VERSION "Version"

NS_ :

BS_:

BU_: Tester MCU BMS GCU EOP EVCC CCU CCURT1 CCURT2 CCU3 CCU4 ZCUF ZCUL ZCUR ZCUT PADS VDC GSM PCU TCU EMS DCDC IPS DCU2 OBC OPC LPC CPC DCU IPU SRS ECS EPS EPB IBCS RBM ICM IDC AMP WHUD IMR INU ADC IFC RRR RLR RADARRR RADARRL RADARFR RADARFL PAS PCS RPC RADARFRT RADARR SCMR SCMRR SCMRL MFS AVAS DLPFL FBLCM FLISD FLLCM FRLCM RLLCMA RLLCMB RRLCMA RRLCMB DLPML DLPMR PSDL PSDR HVSPRL HVSPRR UWB RFR SBM WCM ETC TBOX IDUR Rema2 Rema1 IID TMC RCICP CD SCMRM SCMT FCP RCP RLISD RRISD LBMS FR PLGM EDL

BO_ 2015 Fun_Diag_Rx: 64 Tester
 SG_ Fun_Diag_Request : 7|512@0+ (1,0) [0|0] ""  CCURT1,CCURT2,CCU3,CCU4,ZCUF,ZCUL,ZCUR,ZCUT,PADS,VDC,GSM,PCU,TCU,EMS,DCDC,IPS,MCU,DCU2,OBC,OPC,LPC,CPC,GCU,DCU,IPU,BMS,EOP,EVCC,SRS,ECS,EPS,EPB,IBCS,RBM,ICM,IDC,AMP,WHUD,IMR,INU,ADC,IFC,RRR,RLR,RADARRR,RADARRL,RADARFR,RADARFL,PAS,PCS,RPC,RADARFRT,RADARR,SCMR,SCMRR,SCMRL,MFS,AVAS,DLPFL,FBLCM,FLISD,FLLCM,FRLCM,RLLCMA,RLLCMB,RRLCMA,RRLCMB,DLPML,DLPMR,PSDL,PSDR,HVSPRL,HVSPRR,UWB,RFR,SBM,WCM,ETC,TBOX

BO_ 1179 DCU2_DiagEvent: 64 MCU
 SG_ DCU2_DTCCode15 : 487|32@0+ (1,0) [0|4294967295] ""  CCU,CCURT1
 SG_ DCU2_DTCCode14 : 455|32@0+ (1,0) [0|4294967295] ""  CCU,CCURT1
 SG_ DCU2_DTCCode13 : 423|32@0+ (1,0) [0|4294967295] ""  CCU,CCURT1
 SG_ DCU2_DTCCode12 : 391|32@0+ (1,0) [0|4294967295] ""  CCU,CCURT1
 SG_ DCU2_DTCCode11 : 359|32@0+ (1,0) [0|4294967295] ""  CCU,CCURT1
 SG_ DCU2_DTCCode10 : 327|32@0+ (1,0) [0|4294967295] ""  CCU,CCURT1
 SG_ DCU2_DTCCode9 : 295|32@0+ (1,0) [0|4294967295] ""  CCU,CCURT1
 SG_ DCU2_DTCCode8 : 263|32@0+ (1,0) [0|4294967295] ""  CCU,CCURT1
 SG_ DCU2_DTCCode7 : 231|32@0+ (1,0) [0|4294967295] ""  CCU,CCURT1
 SG_ DCU2_DTCCode6 : 199|32@0+ (1,0) [0|4294967295] ""  CCU,CCURT1
 SG_ DCU2_DTCCode5 : 167|32@0+ (1,0) [0|4294967295] ""  CCU,CCURT1
 SG_ DCU2_DTCCode4 : 135|32@0+ (1,0) [0|4294967295] ""  CCU,CCURT1
 SG_ DCU2_DTCCode3 : 103|32@0+ (1,0) [0|4294967295] ""  CCU,CCURT1
 SG_ DCU2_DTCCode2 : 71|32@0+ (1,0) [0|4294967295] ""  CCU,CCURT1
 SG_ DCU2_DTCCode1 : 39|32@0+ (1,0) [0|4294967295] ""  CCU,CCURT1
 SG_ DCU2_DTCCode0 : 7|32@0+ (1,0) [0|4294967295] ""  CCU,CCURT1

BO_ 1185 IPS_DigEvent: 64 MCU
 SG_ IPS_DigEvent : 7|512@0+ (1,0) [0|0] ""  CCU,CCURT1

BO_ 378 BMS_1: 64 BMS
 SG_ BMS_1_CRC : 7|16@0+ (1,0) [0|65535] ""  CCU,CCURT1,DCDC,IPS,MCU,DCU2,IDUR,OBC,GCU,DCU,IPU
 SG_ BMS_1_Counter : 23|8@0+ (1,0) [0|255] ""  CCU,CCURT1,DCDC,IPS,MCU,DCU2,IDUR,OBC,GCU,DCU,IPU
 SG_ BMS_BattCurr : 31|16@0+ (0.1,-1000) [-1000|5553.5] "A"  CCU,MCU,DCU2,IDUR,GCU,DCU,IPU
 SG_ BMS_BattVolt : 47|10@0+ (1,0) [0|1023] "V"  CCU,MCU,DCU2,IDUR,GCU,DCU,IPU
 SG_ BMS_BusVolt : 49|10@0+ (1,0) [0|1023] "V"  CCU,MCU,DCU2,IDUR,GCU,DCU,IPU
 SG_ BMS_PwrDwnReq : 97|2@0+ (1,0) [0|3] ""  CCU,DCDC,IPS,MCU,DCU2,IDUR,OBC,GCU,DCU,IPU
 SG_ BMS_DCUBattSt : 108|1@0+ (1,0) [0|1] ""  CCU,CCURT1,CCURT2,DCDC,IPS,MCU,DCU2,IDUR,OBC,GCU,DCU,IPU

BO_ 729 EDL_1: 24 EDL
 SG_ EDL_DiffLockModSt_R : 59|3@0+ (1,0) [0|7] ""  CCU,CCURT1,MCU,Rema1

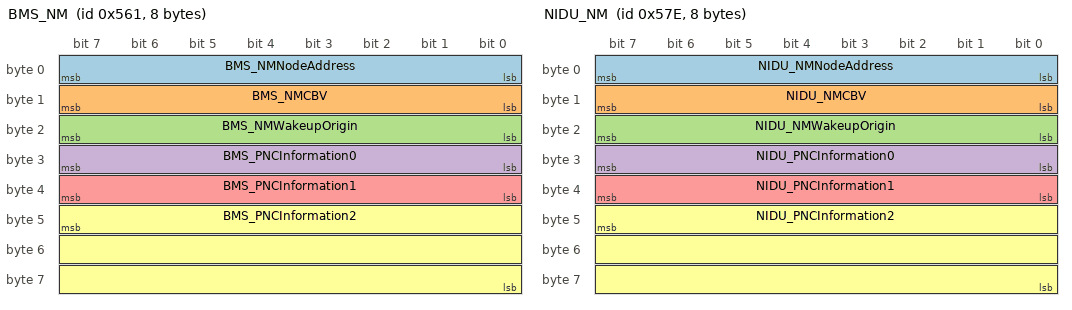
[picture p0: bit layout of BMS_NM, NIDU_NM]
BO_ 1377 BMS_NM: 8 BMS
 SG_ BMS_NMNodeAddress : 7|8@0+ (1,0) [0|255] ""  CCU,DCDC,IPS,MCU,OBC,OPC,GCU,DCU,IPU
 SG_ BMS_NMCBV : 15|8@0+ (1,0) [0|0] ""  CCU,DCDC,IPS,MCU,OBC,OPC,GCU,DCU,IPU
 SG_ BMS_NMWakeupOrigin : 23|8@0+ (1,0) [0|255] ""  CCU,DCDC,IPS,MCU,OBC,OPC,GCU,DCU,IPU
 SG_ BMS_PNCInformation0 : 31|8@0+ (1,0) [0|255] ""  CCU,DCDC,IPS,MCU,OBC,OPC,GCU,DCU,IPU
 SG_ BMS_PNCInformation1 : 39|8@0+ (1,0) [0|0] ""  CCU,DCDC,IPS,MCU,OBC,OPC,GCU,DCU,IPU
 SG_ BMS_PNCInformation2 : 47|24@0+ (1,0) [0|0] ""  CCU,DCDC,IPS,MCU,OBC,OPC,GCU,DCU,IPU

BO_ 410 GCU_1: 64 GCU
 SG_ GCU_IdcAct : 47|11@0+ (1,-1023) [-1023|1022] "A"  CCU,MCU,DCU2,IDUR,DCU,BMS

BO_ 369 DCU2_1: 64 MCU
 SG_ DCU2_1_CRC : 7|16@0+ (1,0) [0|65535] ""  CCU,CCURT1,BMS,EOP,Tester
 SG_ DCU2_1_Counter : 23|8@0+ (1,0) [0|255] ""  CCU,CCURT1,BMS,EOP,Tester
 SG_ DCU2_RotSpdAct : 31|16@0+ (1,-32767) [-32767|32766] "rpm"  CCU,CCURT1,BMS,EOP
 SG_ DCU2_IdcAct : 47|11@0+ (1,-1023) [-1023|1022] "A"  CCU,CCURT1,BMS
 SG_ DCU2_UdcAct : 52|10@0+ (1,0) [0|1021] "V"  CCU,CCURT1,BMS
 SG_ DCU2_CCUEOPPowerSup : 57|2@0+ (1,0) [0|3] ""  CCU,CCURT1,EOP
 SG_ DCU2_TorqMax : 75|10@0+ (1,0) [0|1021] "Nm"  CCU,CCURT1
 SG_ DCU2_HvilSt : 81|2@0+ (1,0) [0|3] ""  CCU,CCURT1
 SG_ DCU2_TorqMin : 95|10@0+ (1,-1023) [-1021|0] "Nm"  CCU,CCURT1
 SG_ DCU2_SelfTorqMax : 101|10@0+ (1,0) [0|1021] "Nm"  CCU,CCURT1
 SG_ DCU2_SelfTorqMin : 106|10@0+ (1,-1023) [-1021|0] "Nm"  CCU,CCURT1
 SG_ DCU2_DstActive : 112|1@0+ (1,0) [0|1] ""  CCU,CCURT1
 SG_ DCU2_GateDrvSt : 127|2@0+ (1,0) [0|3] ""  CCU,CCURT1
 SG_ DCU2_DiagErrCode : 125|6@0+ (1,0) [0|63] ""  CCU,CCURT1
 SG_ DCU2_EOP_SpdSet : 188|12@0+ (1,0) [0|4000] "rpm"  CCU,CCURT1,EOP
 SG_ DCU2_ModeSt_Hyb : 221|4@0+ (1,0) [0|15] ""  CCU,CCURT1,BMS
 SG_ DCU2_TorqAct : 169|13@0+ (0.2,-819) [-819|819] "Nm"  CCU,CCURT1,EOP
 SG_ DCU2_ADC_MCUBlkst : 268|3@0+ (1,0) [0|7] ""  CCU,CCURT1,Rema2
 SG_ DCU2_ADC_SpdSvModAvl : 256|1@0+ (1,0) [0|1] ""  CCU,CCURT1,Rema2
 SG_ DCU2_ADC_MCUStandstill : 257|1@0+ (1,0) [0|1] ""  CCU,CCURT1,Rema2
 SG_ DCU2_ADC_MCUSpdSVModFit : 271|3@0+ (1,0) [0|7] ""  CCU,CCURT1,Rema2
 SG_ DCU2_ADC_MCUVehSldSt : 258|1@0+ (1,0) [0|1] ""  CCU,CCURT1,Rema2
 SG_ DCU2_ADC_MCUReqTq : 253|11@0+ (1,-1023) [-1023|1023] "Nm"  CCU,CCURT1,Rema2
 SG_ DCU2_Iq : 338|15@0+ (0.1,-1500) [-1500|1776.7] "A"  CCU,Rema1
 SG_ DCU2_Id : 355|15@0+ (0.1,-1500) [-1500|1776.7] "A"  CCU,Rema1
 SG_ DCU2_TrqWoDstC : 406|10@0+ (1,-511) [-511|510] "Nm"  CCU,CCURT1
 SG_ DCU2_stTrqEmLim : 417|11@0+ (1,0) [0|2045] ""  CCU,CCURT1
 SG_ DCU2_KL15St : 217|1@0+ (1,0) [0|1] ""  CCU,CCURT1,Rema1

BO_ 866 DCU2_2: 64 MCU
 SG_ DCU2_2_CRC : 7|16@0+ (1,0) [0|65535] ""  CCU,CCURT1
 SG_ DCU2_2_Counter : 23|8@0+ (1,0) [0|255] ""  CCU,CCURT1
 SG_ DCU2_OffsetCalInd : 64|1@0+ (1,0) [0|1] ""  CCU,CCURT1
 SG_ DCU2_InvtTemp : 72|8@0+ (1,-40) [-40|213] "degC"  CCU,CCURT1
 SG_ DCU2_VoltageT30 : 80|6@0+ (0.5,0) [0|31.5] "V"  CCU,CCURT1
 SG_ DCU2_SysTempOvrInd : 90|1@0+ (1,0) [0|1] ""  CCU,CCURT1
 SG_ DCU2_RotTemp : 89|9@0+ (1,-40) [-40|469] "degC"  CCU,CCURT1
 SG_ DCU2_CooltReq : 96|6@0+ (0.25,0) [0|15.5] "L/min"  CCU,CCURT1
 SG_ DCU2_FaultLampInd : 106|1@0+ (1,0) [0|1] ""  CCU,CCURT1
 SG_ DCU2_StatTemp : 105|9@0+ (1,-40) [-40|469] "degC"  CCU,CCURT1
 SG_ DCU2_ErrNotice : 135|3@0+ (1,0) [0|7] ""  CCU,Rema1
 SG_ DCU2_ETCS : 182|1@0+ (1,0) [0|1] ""  CCU,CCURT1,Rema1
 SG_ DCU2_TEL_MotorNumOrder : 194|3@0+ (1,0) [0|7] ""  CCU,CCURT1
 SG_ DCU2_TEL_ECUTempOvrErr : 195|1@0+ (1,0) [0|1] ""  CCU,CCURT1
 SG_ DCU2_TEL_MotTempOvrErr : 196|1@0+ (1,0) [0|1] ""  CCU,CCURT1
 SG_ DCU2_TEL_MotorNumTotal : 199|3@0+ (1,0) [0|7] ""  CCU,CCURT1
 SG_ DCU2_TEL_InvtTemp : 207|8@0+ (1,-40) [-40|213] "deg"  CCU,CCURT1
 SG_ DCU2_TEL_RotSpdAct : 215|16@0+ (1,-20000) [-20000|45533] "rpm"  CCU,CCURT1
 SG_ DCU2_TEL_TorqAct : 231|16@0+ (0.1,-2000) [-2000|4553.3] "Nm"  CCU,CCURT1
 SG_ DCU2_TEL_StatTemp : 247|8@0+ (1,-40) [-40|213] "deg"  CCU,CCURT1
 SG_ DCU2_TEL_ModeSt : 293|3@0+ (1,0) [0|7] ""  CCU,CCURT1
 SG_ DCU2_TEL_CurrActAmend : 255|16@0+ (0.1,-1000) [-1000|1000] "A"  CCU,CCURT1
 SG_ DCU2_TEL_UdcAct : 181|14@0+ (0.1,0) [0|1000] "V"  CCU,CCURT1
 SG_ DCU2_TEL_BattCurr : 271|16@0+ (0.1,-1000) [-1000|1000] "A"  CCU,CCURT1
 SG_ DCU2_Fault1 : 138|16@0+ (1,0) [0|65535] ""  CCU,Rema1
 SG_ DCU2_Fault2 : 154|16@0+ (1,0) [0|65535] ""  CCU,Rema1
 SG_ DCU2_Fault3 : 406|16@0+ (1,0) [0|65535] ""  CCU,Rema1
 SG_ DCU2_Fault4 : 422|16@0+ (1,0) [0|65535] ""  CCU,Rema1
 SG_ DCU2_OffsetCalVal : 389|13@0+ (0.05,0) [0|409.45] "deg"  CCU,CCURT1
 SG_ DCU2_EngMilLampReq : 392|1@0+ (1,0) [0|1] ""  CCU,CCURT1
 SG_ DCU2_ZeroTorqCompensateSt : 407|1@0+ (1,0) [0|1] ""  CCU,CCURT1

BO_ 1275 DCU2_BigData: 64 MCU
 SG_ DCU2_Data1No M : 7|8@0+ (1,0) [0|205] ""  CCU,Rema1
 SG_ DCU2_Hwversion m1 : 15|16@0+ (1,0) [0|65535] ""  CCU,Rema1
 SG_ DCU2_Swversion m1 : 31|16@0+ (1,0) [0|65535] ""  CCU,Rema1
 SG_ DCU2_SwVerExt m1 : 47|32@0+ (1,0) [0|4294967295] ""  CCU,Rema1
 SG_ DCU2_OffsetAngle m1 : 79|12@0+ (1,0) [0|4095] ""  CCU,Rema1
 SG_ DCU2_BootSV m1 : 83|12@0+ (1,0) [0|4095] ""  CCU,Rema1
 SG_ DCU2_BSWVersion m1 : 103|32@0+ (1,0) [0|4294967295] ""  CCU,Rema1
 SG_ DCU2_HWConfig m1 : 135|32@0+ (1,0) [0|4294967295] ""  CCU,Rema1
 SG_ DCU2_SWConfig m1 : 167|32@0+ (1,0) [0|4294967295] ""  CCU,Rema1
 SG_ DCU2_MCAConfig m1 : 199|32@0+ (1,0) [0|4294967295] ""  CCU,Rema1
 SG_ DCU2_FHConfig m1 : 231|32@0+ (1,0) [0|4294967295] ""  CCU,Rema1
 SG_ DCU2_InvtPhaUTemp m1 : 263|8@0+ (1,-40) [-40|214] "degC"  CCU,Rema1
 SG_ DCU2_InvtPhaVTemp m1 : 271|8@0+ (1,-40) [-40|214] "degC"  CCU,Rema1
 SG_ DCU2_InvtPhaWTemp m1 : 279|8@0+ (1,-40) [-40|214] "degC"  CCU,Rema1
 SG_ DCU2_Stat1Temp m1 : 287|8@0+ (1,-40) [-40|214] "degC"  CCU,Rema1
 SG_ DCU2_Stat2Temp m1 : 295|8@0+ (1,-40) [-40|214] "degC"  CCU,Rema1
 SG_ DCU2_CtrlBoardTemp m1 : 303|8@0+ (1,-40) [-40|214] "degC"  CCU,Rema1
 SG_ DCU2_DrvBoardTemp m1 : 311|8@0+ (1,-40) [-40|214] "degC"  CCU,Rema1
 SG_ DCU2_CapTemp m1 : 319|8@0+ (1,-40) [-40|214] "degC"  CCU,Rema1
 SG_ DCU2_FusastSafePathReq m1 : 327|3@0+ (1,0) [0|7] ""  CCU,Rema1
 SG_ DCU2_FusaModeSt m1 : 324|4@0+ (1,0) [0|15] ""  CCU,Rema1
 SG_ DCU2_FusaQDisChargeReq m1 : 320|1@0+ (1,0) [0|1] ""  CCU,Rema1
 SG_ DCU2_FusastPWMEna m1 : 335|1@0+ (1,0) [0|1] ""  CCU,Rema1
 SG_ DCU2_FusaErrCode m1 : 334|6@0+ (1,0) [0|63] ""  CCU,Rema1
 SG_ DCU2_FusaRotSpdAct m1 : 328|16@0+ (1,-32767) [-32767|32766] ""  CCU,Rema1
 SG_ DCU2_FusaTorqAct m1 : 344|13@0+ (0.2,-819) [-819|819] ""  CCU,Rema1
 SG_ DCU2_FusaFaultInfo7 m1 : 363|32@0+ (1,0) [0|4294967295] ""  CCU,Rema1
 SG_ DCU2_FusaFaultInfo8 m1 : 395|32@0+ (1,0) [0|4294967295] ""  CCU,Rema1
 SG_ DCU2_FaultData_RC m2 : 15|8@0+ (1,0) [0|255] ""  CCU,Rema1
 SG_ DCU2_stHandleOff m2 : 23|1@0+ (1,0) [0|1] ""  CCU,Rema1
 SG_ DCU2_stPWMEna m2 : 22|1@0+ (1,0) [0|1] ""  CCU,Rema1
 SG_ DCU2_stMode m2 : 21|4@0+ (1,0) [0|15] ""  CCU,Rema1
 SG_ DCU2_FailCode m2 : 17|10@0+ (1,0) [0|1023] ""  CCU,Rema1
 SG_ DCU2_stASCProt m2 : 39|16@0+ (1,0) [0|65535] ""  CCU,Rema1
 SG_ DCU2_agRotorPosn m2 : 55|12@0+ (1,0) [0|4095] ""  CCU,Rema1
 SG_ DCU2_RelativeTime m2 : 193|18@0+ (1,0) [0|262143] "s"  CCU,Rema1
 SG_ DCU2_stFaultFlag100us m2 : 223|16@0+ (1,0) [0|65535] ""  CCU,Rema1
 SG_ DCU2_PWMFreq m2 : 239|16@0+ (1,0) [0|65535] "Hz"  CCU,Rema1
 SG_ DCU2_uDcVolt m2 : 255|10@0+ (1,0) [0|1023] "V"  CCU,Rema1
 SG_ DCU2_uLowVolt m2 : 261|8@0+ (0.1,0) [0|25.5] "V"  CCU,Rema1
 SG_ DCU2_iCurdFinalRef m2 : 59|12@0+ (1,-2048) [-2048|2047] "A"  CCU,Rema1
 SG_ DCU2_iCurqFinalRef m2 : 79|12@0+ (1,-2048) [-2048|2047] "A"  CCU,Rema1
 SG_ DCU2_iCurdFb m2 : 83|12@0+ (1,-2048) [-2048|2047] "A"  CCU,Rema1
 SG_ DCU2_iCurqFb m2 : 103|12@0+ (1,-2048) [-2048|2047] "A"  CCU,Rema1
 SG_ DCU2_iPhaCurU m2 : 107|12@0+ (1,-2048) [-2048|2047] "A"  CCU,Rema1
 SG_ DCU2_iPhaCurV m2 : 127|12@0+ (1,-2048) [-2048|2047] "A"  CCU,Rema1
 SG_ DCU2_iPhaCurW m2 : 131|12@0+ (1,-2048) [-2048|2047] "A"  CCU,Rema1
 SG_ DCU2_uVoltdFinalRef m2 : 151|12@0+ (1,-2048) [-2048|2047] "V"  CCU,Rema1
 SG_ DCU2_uVoltqFinalRef m2 : 155|12@0+ (1,-2048) [-2048|2047] "V"  CCU,Rema1
 SG_ DCU2_iDcCur m2 : 175|12@0+ (1,-2048) [-2048|2047] "A"  CCU,Rema1
 SG_ DCU2_ResFaultFlag m2 : 269|16@0+ (1,0) [0|65535] ""  CCU,Rema1
 SG_ DCU2_stTsc m2 : 285|16@0+ (1,0) [0|65535] ""  CCU,Rema1
 SG_ DCU2_OperatingCycle m2 : 179|18@0+ (1,0) [0|262143] ""  CCU,Rema1
 SG_ DCU2_Year m2 : 317|8@0+ (1,2000) [2000|2255] "Y"  CCU,Rema1
 SG_ DCU2_Month m2 : 325|4@0+ (1,0) [1|12] "M"  CCU,Rema1
 SG_ DCU2_Day m2 : 321|5@0+ (1,0) [1|31] "D"  CCU,Rema1
 SG_ DCU2_Hour m2 : 332|5@0+ (1,0) [0|23] "h"  CCU,Rema1
 SG_ DCU2_Minute m2 : 343|6@0+ (1,0) [0|59] "m"  CCU,Rema1
 SG_ DCU2_Second m2 : 337|6@0+ (1,0) [0|59] "s"  CCU,Rema1
 SG_ DCU2_FaultData_1Bit_1 m2 : 467|1@0+ (1,0) [0|1] ""  CCU,Rema1
 SG_ DCU2_FaultData_1Bit_2 m2 : 466|1@0+ (1,0) [0|1] ""  CCU,Rema1
 SG_ DCU2_FaultData_1Bit_3 m2 : 465|1@0+ (1,0) [0|1] ""  CCU,Rema1
 SG_ DCU2_FaultData_1Bit_4 m2 : 464|1@0+ (1,0) [0|1] ""  CCU,Rema1
 SG_ DCU2_FaultData_4Bit_1 m2 : 479|4@0+ (1,0) [0|15] ""  CCU,Rema1
 SG_ DCU2_FaultData_12Bit_1 m2 : 475|12@0+ (1,-2048) [-2048|2047] ""  CCU,Rema1
 SG_ DCU2_FaultData_16Bit_1 m2 : 495|16@0+ (1,0) [0|65535] ""  CCU,Rema1
 SG_ DCU2_stIGBTFault m2 : 301|16@0+ (1,0) [0|65535] ""  CCU,Rema1
 SG_ DCU2_stBigDataTrigger m2 : 347|4@0+ (1,0) [0|15] ""  CCU,Rema1
 SG_ DCU2_FaultData_4Bit_2 m2 : 359|4@0+ (1,0) [0|15] ""  CCU,Rema1
 SG_ DCU2_FaultData_4Bit_3 m2 : 355|4@0+ (1,0) [0|15] ""  CCU,Rema1
 SG_ DCU2_FaultData_8Bit_1 m2 : 383|8@0+ (1,0) [0|255] ""  CCU,Rema1
 SG_ DCU2_FaultData_8Bit_2 m2 : 391|8@0+ (1,0) [0|255] ""  CCU,Rema1
 SG_ DCU2_FaultData_8Bit_3 m2 : 399|8@0+ (1,0) [0|255] ""  CCU,Rema1
 SG_ DCU2_FaultData_8Bit_4 m2 : 407|8@0+ (1,0) [0|255] ""  CCU,Rema1
 SG_ DCU2_FaultData_12Bit_2 m2 : 415|12@0+ (1,0) [0|4095] ""  CCU,Rema1
 SG_ DCU2_FaultData_12Bit_3 m2 : 419|12@0+ (1,0) [0|4095] ""  CCU,Rema1
 SG_ DCU2_FaultData_16Bit_2 m2 : 439|16@0+ (1,0) [0|65535] ""  CCU,Rema1
 SG_ DCU2_FaultData_20Bit_1 m2 : 455|20@0+ (1,0) [0|1048575] ""  CCU,Rema1
 SG_ DCU2_stSBCFault m2 : 367|16@0+ (1,0) [0|65535] ""  CCU,Rema1

BO_ 384 EOP_1: 64 EOP
 SG_ EOP_1_CRC : 7|16@0+ (1,0) [0|65535] ""  MCU,DCU2
 SG_ EOP_1_Counter : 23|8@0+ (1,0) [0|255] ""  MCU,DCU2
 SG_ EOP_IdcAct : 55|8@0+ (0.1,0) [0|25] "A"  MCU,DCU2
 SG_ EOP_IphAct : 33|10@0+ (0.1,0) [0|50] "A"  MCU,DCU2
 SG_ EOP_UdcAct : 63|8@0+ (0.1,0) [0|25] "V"  MCU,DCU2
 SG_ EOP_SpdAct : 29|12@0+ (1,0) [0|4000] "rpm"  MCU,DCU2
 SG_ EOP_Status : 71|3@0+ (1,0) [0|4] ""  MCU,DCU2
 SG_ EOP_duty : 79|7@0+ (1,0) [0|100] "%"  MCU,DCU2
 SG_ EOP_ErrLevel : 68|3@0+ (1,0) [0|7] ""  MCU,DCU2
 SG_ EOP_RemoteDiagCode : 31|2@0+ (1,0) [0|3] ""  MCU,DCU2
 SG_ EOP_1_FreshnessValue : 455|16@0+ (1,0) [0|255] ""  MCU,DCU2
 SG_ EOP_1_MAC_Check : 471|48@0+ (1,0) [0|255] ""  MCU,DCU2

BO_ 704 IPS_1: 64 MCU
 SG_ IPS_DCDCHVPwr : 342|10@0+ (5,0) [0|5115] "" Vector__XXX
 SG_ IPS_1_CRC : 7|16@0+ (1,0) [0|65535] ""  CCU,CCURT1,BMS
 SG_ IPS_1_Counter : 23|8@0+ (1,0) [0|255] ""  CCU,CCURT1,BMS
 SG_ IPS_DCDCDiagErrCode : 31|8@0+ (1,0) [0|255] ""  CCU
 SG_ IPS_DCDCModeSt : 39|3@0+ (1,0) [0|7] ""  CCU,CCURT1,CCURT2
 SG_ IPS_KL15State : 36|1@0+ (1,0) [0|1] ""  CCU
 SG_ IPS_DCDCVoltLvAct : 35|10@0+ (0.1,0) [0|102.3] "V"  CCU,CCURT1
 SG_ IPS_DCDCCurrHvAct : 41|9@0+ (0.125,0) [0|63.875] "A"  CCU,DCU2
 SG_ IPS_DCDCCurrLvAct : 63|9@0+ (1,0) [0|511] "A"  CCU,CCURT1
 SG_ IPS_DCDCVoltHvAct : 70|10@0+ (1,0) [0|1023] "V"  CCU,DCU2
 SG_ IPS_OBCDiagErrCode : 151|8@0+ (1,0) [0|255] ""  CCU,CCURT1,BMS
 SG_ IPS_OBCCC_St : 159|3@0+ (1,0) [0|7] ""  CCU,CCURT1,DCU2,BMS
 SG_ IPS_OBCCC_Res : 156|10@0+ (10,0) [0|10230] "Ω"  CCU,CCURT1
 SG_ IPS_DchgOverload : 161|1@0+ (1,0) [0|1] ""  CCU
 SG_ IPS_OBCDschDisable : 162|1@0+ (1,0) [0|1] ""  CCU,CCURT1,BMS
 SG_ IPS_OBCModeSt : 175|4@0+ (1,0) [0|15] ""  CCU,CCURT1,BMS
 SG_ IPS_OBCHvDcCurrAct : 171|11@0+ (0.1,-102.4) [-102.4|102.3] "A"  CCU,CCURT1,BMS
 SG_ IPS_OBCHvDcVoltAct : 176|10@0+ (1,0) [0|1023] "V"  CCU,CCURT1,BMS
 SG_ IPS_OBCCC_Cap : 198|3@0+ (1,0) [0|7] ""  CCU,CCURT1,BMS
 SG_ IPS_OBCCpS2St : 200|1@0+ (1,0) [0|1] ""  CCU,CCURT1,BMS
 SG_ IPS_OBCCpFreqSt : 160|1@0+ (1,0) [0|1] ""  CCU,CCURT1,BMS
 SG_ IPS_OBCCPSt : 195|1@0+ (1,0) [0|1] ""  CCU,CCURT1,BMS
 SG_ IPS_OBCCp_DutyCycle : 194|10@0+ (0.1,0) [0|100] ""  CCU,CCURT1,BMS
 SG_ IPS_OBCCPVolt : 215|8@0+ (0.1,0) [0|12.7] "V"  CCU,CCURT1,BMS
 SG_ IPS_OBCV2CSt : 242|3@0+ (1,0) [0|7] ""  CCU,CCURT1,Rema1
 SG_ IPS_V2CMicSwitSt : 245|3@0+ (1,0) [0|7] ""  CCU,CCURT1,Rema1
 SG_ IPS_smo_ObcModeSt : 275|7@0+ (1,0) [0|127] ""  CCU
 SG_ IPS_smd_DcdcModeSt : 300|6@0+ (1,0) [0|63] ""  CCU
 SG_ IPS_WakeOriginSignal1 : 310|16@0+ (1,0) [0|65535] ""  CCU
 SG_ IPS_WakeOriginSignal2 : 326|16@0+ (1,0) [0|65535] ""  CCU
 SG_ IPS_OBCCurrActL1 : 254|9@0+ (0.1,0) [0|51.1] "A"  CCU,CCURT1,BMS
 SG_ IPS_OBCCurrActL2 : 261|9@0+ (0.1,0) [0|51.1] "A"  CCU,CCURT1
 SG_ IPS_OBCCurrActL3 : 268|9@0+ (0.1,0) [0|51.1] "A"  CCU,CCURT1
 SG_ IPS_DCDCKL30VoltForHyb : 384|9@0+ (0.1,0) [0|51.1] ""  CCU
 SG_ IPS_DCDCHVilSt : 302|2@0+ (1,0) [0|3] ""  CCU,CCURT1,Rema1
 SG_ IPS_OBC_DCVolt : 378|10@0+ (1,0) [0|1023] "V"  CCU,CCURT1,BMS,Rema1
 SG_ IPS_OBCUacActL1 : 431|9@0+ (1,0) [0|511] "V"  CCU,CCURT1,BMS
 SG_ IPS_OBCUacActL2 : 408|9@0+ (1,0) [0|511] "V"  CCU,CCURT1
 SG_ IPS_OBCUacActL3 : 407|9@0+ (1,0) [0|511] "V"  CCU,CCURT1
 SG_ IPS_HVDCHVilStForHyb : 435|2@0+ (1,0) [0|3] ""  CCU,BMS
 SG_ IPS_ACHvilStForHyb : 437|2@0+ (1,0) [0|3] ""  CCU,CCURT1,BMS
 SG_ IPS_OBCStStep : 433|2@0+ (1,0) [0|3] ""  CCU,CCURT1,BMS
 SG_ Reserved1 : 440|1@0+ (1,0) [0|0] ""  CCU

BO_ 872 IPS_2: 64 MCU
 SG_ IPS_2_CRC : 7|16@0+ (1,0) [0|65535] ""  CCU,CCURT1,DCU2
 SG_ IPS_2_Counter : 23|8@0+ (1,0) [0|255] ""  CCU,CCURT1,DCU2
 SG_ IPS_SwVersion : 31|16@0+ (1,0) [0|65535] ""  CCU
 SG_ IPS_HwSt : 47|4@0+ (1,0) [0|15] ""  CCU
 SG_ IPS_RemoteDiagCode : 43|2@0+ (1,0) [0|3] ""  CCU,Rema1
 SG_ IPS_TEL_DCDCFaultLampInd : 41|1@0+ (1,0) [0|1] ""  CCU
 SG_ IPS_TEL_DCDCTempOvrErr : 40|1@0+ (1,0) [0|1] ""  CCU
 SG_ IPS_TEL_DCDCModeSt : 55|2@0+ (1,0) [0|3] ""  CCU
 SG_ IPS_TempAct : 63|8@0+ (1,-40) [-40|215] "degC"  CCU,CCURT1,DCU2
 SG_ IPS_DCDCFaultLampInd : 53|1@0+ (1,0) [0|1] ""  CCU,CCURT1,ICM,IDC
 SG_ IPS_DCDCFlowReq : 52|4@0+ (1,0) [0|15] "LpMin"  CCU
 SG_ IPS_ChgWakeDisableFlg : 136|1@0+ (1,0) [0|1] ""  CCU,CCURT1,Rema1
 SG_ IPS_OBCChgPwrMax : 135|10@0+ (0.05,0) [0|51.15] "kW"  CCU,CCURT1,BMS
 SG_ IPS_OBCFlowReq : 141|4@0+ (1,0) [0|15] "LpMin"  CCU,CCURT1
 SG_ IPS_OBCFaultLampInd : 137|1@0+ (1,0) [0|1] ""  CCU,CCURT1
 SG_ IPS_DCDCState1 : 87|8@0+ (1,0) [0|255] ""  CCU
 SG_ IPS_DCDCState2 : 95|8@0+ (1,0) [0|255] ""  CCU
 SG_ IPS_DCDCState3 : 103|8@0+ (1,0) [0|255] ""  CCU
 SG_ IPS_DCDCState4 : 111|8@0+ (1,0) [0|255] ""  CCU
 SG_ IPS_DCDCState5 : 119|8@0+ (1,0) [0|255] ""  CCU
 SG_ IPS_OBCState6 : 279|8@0+ (1,0) [0|255] ""  CCU,Rema1
 SG_ IPS_OBCState7 : 207|8@0+ (1,0) [0|255] ""  CCU,Rema1
 SG_ IPS_OBCState8 : 215|8@0+ (1,0) [0|255] ""  CCU,Rema1
 SG_ IPS_OBCState9 : 223|8@0+ (1,0) [0|255] ""  CCU,Rema1
 SG_ IPS_OBCState1 : 159|8@0+ (1,0) [0|255] ""  CCU,CCURT1
 SG_ IPS_OBCState2 : 167|8@0+ (1,0) [0|255] ""  CCU,CCURT1
 SG_ IPS_OBCState3 : 175|8@0+ (1,0) [0|255] ""  CCU,CCURT1
 SG_ IPS_OBCState4 : 183|8@0+ (1,0) [0|255] ""  CCU,CCURT1
 SG_ IPS_OBCState5 : 191|8@0+ (1,0) [0|255] ""  CCU,CCURT1
 SG_ IPS_DCDCTempAct : 423|8@0+ (1,-40) [-40|215] "degC"  CCU
 SG_ IPS_ChgCurResp : 149|5@0+ (1,0) [0|31] ""  CCU,Rema1
 SG_ IPS_ChgCurRespAvail : 144|1@0+ (1,0) [0|1] ""  CCU,Rema1
 SG_ IPS_DCDCState6 : 127|8@0+ (1,0) [0|255] ""  CCU,Rema1
 SG_ IPS_DCDCFaultLampIndOperationFla : 199|1@0+ (1,0) [0|1] ""  CCU,Rema1
 SG_ IPS_DCDCFaultLampIndFlag : 198|1@0+ (1,0) [0|1] ""  CCU,Rema1
 SG_ IPS_OBCFaultLampIndOperationFlag : 197|1@0+ (1,0) [0|1] ""  CCU,Rema1
 SG_ IPS_OBCState10 : 231|8@0+ (1,0) [0|255] ""  CCU,Rema1
 SG_ IPS_OBCState11 : 239|8@0+ (1,0) [0|255] ""  CCU,Rema1
 SG_ IPS_DCDCState7 : 247|8@0+ (1,0) [0|255] ""  CCU,Rema1
 SG_ IPS_DCDCState8 : 255|8@0+ (1,0) [0|255] ""  CCU,Rema1
 SG_ IPS_DCDCState9 : 263|8@0+ (1,0) [0|255] ""  CCU,Rema1
 SG_ IPS_DCDCState10 : 271|8@0+ (1,0) [0|255] ""  CCU,Rema1
 SG_ IPS_OBCAclso_Res : 309|6@0+ (20,0) [0|1260] "KΩ"  CCU,Rema1
 SG_ IPS_OBCState12 : 319|8@0+ (1,0) [0|255] ""  CCU,Rema1
 SG_ IPS_OBCState13 : 327|8@0+ (1,0) [0|255] ""  CCU,Rema1
 SG_ IPS_OBCState14 : 335|8@0+ (1,0) [0|255] ""  CCU,Rema1
 SG_ IPS_DCDCState11 : 343|8@0+ (1,0) [0|255] ""  CCU,Rema1
 SG_ IPS_DCDCState12 : 351|8@0+ (1,0) [0|255] ""  CCU,Rema1
 SG_ IPS_DCDCState13 : 359|8@0+ (1,0) [0|255] ""  CCU,Rema1
 SG_ IPS_OBCV2CCurr : 292|9@0+ (0.1,0) [0|51.1] "A"  CCU,CCURT1,Rema1
 SG_ IPS_OBCV2CRlySt : 299|3@0+ (1,0) [0|7] ""  CCU,CCURT1,Rema1
 SG_ IPS_OBCV2LRlySt : 296|3@0+ (1,0) [0|7] ""  CCU,CCURT1,Rema1
 SG_ IPS_OBCDsgPortPwrCons : 427|12@0+ (10,0) [0|40000] "W"  CCU,CCURT1
 SG_ IPS_OBCEngMilLampReq : 428|1@0+ (1,0) [0|1] ""  CCU,CCURT1
 SG_ IPS_OBCDispDiagInfo : 447|8@0+ (1,0) [0|255] ""  CCU,CCURT1

BO_ 1790 NIDU_UDS_Diag_Tx: 64 MCU
 SG_ NIDU_UDS_Diag_Response : 7|64@0+ (1,0) [0|0] ""  Tester

BO_ 1662 NIDU_UDS_Diag_Rx: 64 Tester
 SG_ NIDU_UDS_Diag_Request : 7|64@0+ (1,0) [0|0] ""  MCU

BO_ 2028 NIDU_OBD_Diag_Tx: 64 MCU
 SG_ NIDU_OBD_Diag_Response : 7|64@0+ (1,0) [0|0] ""  Tester

BO_ 2020 NIDU_OBD_Diag_Rx: 64 Tester
 SG_ NIDU_OBD_Diag_Request : 7|64@0+ (1,0) [0|0] ""  MCU

BO_ 1406 NIDU_NM: 8 MCU
 SG_ NIDU_NMNodeAddress : 7|8@0+ (1,0) [0|255] ""  CCU,OPC,GCU,DCU,IPU,BMS
 SG_ NIDU_NMCBV : 15|8@0+ (1,0) [0|0] ""  CCU,OPC,GCU,DCU,IPU,BMS
 SG_ NIDU_NMWakeupOrigin : 23|8@0+ (1,0) [0|255] ""  CCU,OPC,GCU,DCU,IPU,BMS
 SG_ NIDU_PNCInformation0 : 31|8@0+ (1,0) [0|255] ""  CCU,OPC,GCU,DCU,IPU,BMS
 SG_ NIDU_PNCInformation1 : 39|8@0+ (1,0) [0|0] ""  CCU,OPC,GCU,DCU,IPU,BMS
 SG_ NIDU_PNCInformation2 : 47|24@0+ (1,0) [0|0] ""  CCU,OPC,GCU,DCU,IPU,BMS

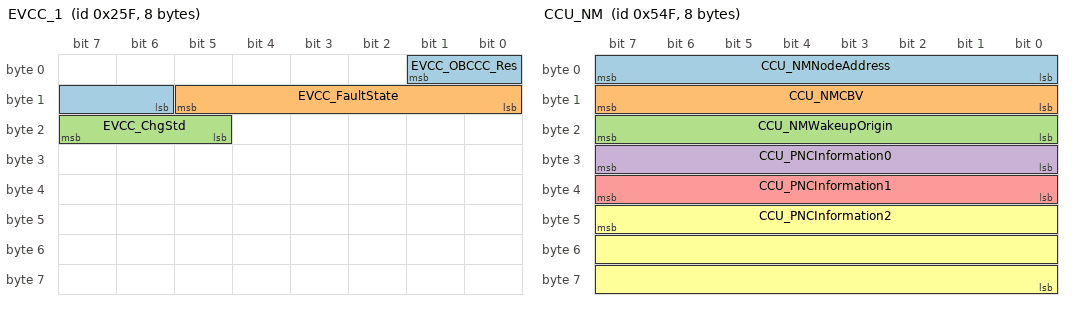
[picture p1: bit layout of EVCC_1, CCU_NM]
BO_ 607 EVCC_1: 8 EVCC
 SG_ EVCC_OBCCC_Res : 1|4@0+ (1,0) [0|15] ""  CCU,IPS,MCU
 SG_ EVCC_FaultState : 13|6@0+ (1,0) [0|63] ""  CCU,IPS,MCU
 SG_ EVCC_ChgStd : 23|3@0+ (1,0) [0|7] ""  CCU,IPS,MCU

BO_ 418 CCU_VCU_2: 48 CCU
 SG_ VCU_MotTqRateLimMin : 220|12@0+ (5,-20475) [-20475|0] "Nm/s"  MCU,DCU2,DCU,IPU,Rema2
 SG_ VCU_TqUnloadEna : 161|2@0+ (1,0) [0|3] ""  MCU,DCU2,DCU,IPU,Rema2
 SG_ VCU_MotTqRateLimMax : 224|10@0+ (5,0) [0|5115] "Nm/s"  MCU,DCU2,DCU,IPU,Rema2

BO_ 417 CCU_VCU_13: 64 CCU
 SG_ VCU_13_CRC : 7|16@0+ (1,0) [0|65535] ""  MCU,DCU2,IDUR
 SG_ VCU_13_Counter : 23|8@0+ (1,0) [0|255] ""  MCU,DCU2,IDUR
 SG_ VCU_DCU2_IdcMax : 31|11@0+ (1,-1024) [-1024|1023] "A"  MCU,DCU2,IDUR
 SG_ VCU_DCU2_IdcMin : 36|11@0+ (1,-1024) [-1024|1023] "A"  MCU,DCU2,IDUR
 SG_ VCU_DCU2_TorqAllwd : 41|2@0+ (1,0) [0|3] ""  MCU,DCU2,IDUR
 SG_ VCU_DCU2_UdcMin : 55|10@0+ (1,0) [0|1021] "V"  MCU,DCU2,IDUR
 SG_ VCU_DCU2_UdcMax : 61|10@0+ (1,0) [0|1021] "V"  MCU,DCU2,IDUR
 SG_ VCU_DCU2_ModeReq : 67|4@0+ (1,0) [0|15] ""  MCU,DCU2,IDUR
 SG_ VCU_DCU2_SpdSet : 79|16@0+ (1,-32767) [-32767|32766] "rpm"  MCU,DCU2,IDUR
 SG_ VCU_DCU2_DampGain : 95|2@0+ (1,0) [0|3] ""  MCU,DCU2,IDUR
 SG_ VCU_DCU2_ZeroTorqCompensateReq : 97|1@0+ (1,0) [0|1] ""  MCU,DCU2,IDUR
 SG_ VCU_DCU2_DampReq : 98|1@0+ (1,0) [0|1] ""  MCU,DCU2,IDUR
 SG_ VCU_DCU2_MaxTorqGradient : 96|14@0+ (32,0) [0|524192] "Nm/s"  MCU,DCU2,IDUR
 SG_ VCU_DCU2_TorqMinETCS : 114|10@0+ (1,-512) [-512|511] "Nm"  MCU,DCU2,IDUR
 SG_ VCU_DCU2_TorqMaxETCS : 120|10@0+ (1,-512) [-512|511] "Nm"  MCU,DCU2,IDUR
 SG_ VCU_DCU2_TorqMin : 142|10@0+ (1,-512) [-512|511] "Nm"  MCU,DCU2,IDUR
 SG_ VCU_DCU2_TorqMax : 148|10@0+ (1,-512) [-512|511] "Nm"  MCU,DCU2,IDUR
 SG_ VCU_DCU2_SpdLmt : 154|16@0+ (1,-32767) [-32767|32766] "rpm"  MCU,DCU2,IDUR
 SG_ VCU_DCU2_MaxTorqDampgCtl : 170|8@0+ (1,0) [0|253] "Nm"  MCU,DCU2,IDUR
 SG_ VCU_DCU2_TorqSet_Hyb : 178|13@0+ (0.2,-819) [-819|819] "Nm"  MCU,DCU2,IDUR
 SG_ VCU_ReTqUnloadEna : 437|2@0+ (1,0) [0|3] ""  MCU,DCU2
 SG_ VCU_ReMotTqRateLimMax : 431|10@0+ (5,0) [0|5115] "Nm/s"  MCU,DCU2
 SG_ VCU_ReMotTqRateLimMin : 435|12@0+ (5,-20475) [-20475|0] "Nm/s"  MCU,DCU2

BO_ 557 CCU_VCU_3: 24 CCU
 SG_ VCU_3_CRC : 7|16@0+ (1,0) [0|65535] ""  IPS,MCU,OBC,OPC,LPC,BMS
 SG_ VCU_3_Counter : 23|8@0+ (1,0) [0|255] ""  IPS,MCU,OBC,OPC,LPC,BMS
 SG_ VCU_IPS_OBCModeReq : 61|3@0+ (1,0) [0|7] ""  IPS,MCU,OBC
 SG_ VCU_IPS_OBCDsChDCCurrLim : 55|10@0+ (0.1,0) [0|102.3] "A"  IPS,MCU,OBC

BO_ 920 CCU_VCU_4: 64 CCU
 SG_ VCU_4_CRC : 7|16@0+ (1,0) [0|65535] ""  ZCUF,ZCUL,ZCUR,ZCUT,DCDC,IPS,MCU
 SG_ VCU_4_Counter : 23|8@0+ (1,0) [0|255] ""  ZCUF,ZCUL,ZCUR,ZCUT,DCDC,IPS,MCU
 SG_ VCU_IPS_DCDCModeReq : 37|3@0+ (1,0) [0|7] ""  DCDC,IPS,MCU
 SG_ VCU_IPS_DCDCLvCurrLim : 31|10@0+ (0.5,0) [0|500] "A"  DCDC,IPS,MCU
 SG_ VCU_SRSCrashOutputSt : 143|8@0+ (1,0) [0|160] ""  MCU,DCU2,GCU,IPU,BMS
 SG_ VCU_IPS_DCDCVoltLvSet : 176|9@0+ (0.1,0) [0|51.1] "V"  DCDC,IPS,MCU
 SG_ VCU_IPS_DCDCVoltLvModeSt : 223|4@0+ (1,0) [0|15] ""  DCDC,IPS,MCU
 SG_ VCU_DCDCVoltLvModeSt : 219|4@0+ (1,0) [0|15] ""  DCDC,IPS,MCU
 SG_ VCU_DCDCVoltLvSet : 200|9@0+ (0.1,0) [0|51.1] "V"  DCDC,IPS,MCU
 SG_ VCU_OBCCPJumpCounter : 285|6@0+ (1,0) [0|63] ""  IPS,MCU,Rema1
 SG_ VCU_OBCCPWarning : 295|1@0+ (1,0) [0|1] ""  IPS,MCU,Rema1

BO_ 998 CCU_VCU_5: 24 CCU
 SG_ VCU_5_CRC : 7|16@0+ (1,0) [0|65535] ""  IPS,MCU,OBC,BMS
 SG_ VCU_5_Counter : 23|8@0+ (1,0) [0|255] ""  IPS,MCU,OBC,BMS
 SG_ VCU_IPS_OBCChgVoltReq : 63|16@0+ (0.1,0) [0|6553.5] "V"  IPS,MCU,OBC
 SG_ VCU_IPS_OBCChgCurrReq : 79|16@0+ (0.1,0) [0|6553.5] "A"  IPS,MCU,OBC

BO_ 1034 CCU_VCU_6: 24 CCU
 SG_ VCU_6_CRC : 7|16@0+ (1,0) [0|65535] ""  IPS,MCU,DCU2,IDUR,OBC,GCU,DCU,IPU
 SG_ VCU_6_Counter : 23|8@0+ (1,0) [0|255] ""  IPS,MCU,DCU2,IDUR,OBC,GCU,DCU,IPU
 SG_ VCU_SubEngWarmUPCycle : 58|1@0+ (1,0) [0|1] ""  EMS,IPS,MCU,DCU2,IDUR,OBC,GCU,DCU,IPU,BMS,IBCS
 SG_ VCU_VehAltitude : 55|13@0+ (1,-90) [-90|8100] "m"  EMS,IPS,MCU,DCU2,IDUR,OBC,GCU,DCU,IPU,BMS
 SG_ VCU_VehIdleRunningTime : 71|8@0+ (1,0) [0|200] "S"  EMS,IPS,MCU,DCU2,IDUR,OBC,GCU,DCU,IPU,BMS
 SG_ VCU_VehRunningTime : 89|10@0+ (1,0) [0|800] "S"  EMS,IPS,MCU,DCU2,IDUR,OBC,GCU,DCU,IPU,BMS
 SG_ VCU_DriveCycleSt : 94|2@0+ (1,0) [0|3] ""  EMS,IPS,MCU,DCU2,IDUR,OBC,GCU,DCU,IPU,BMS,IBCS
 SG_ VCU_VehStopTime : 87|9@0+ (1,0) [0|400] "min"  EMS,IPS,MCU,DCU2,IDUR,OBC,GCU,DCU,IPU,BMS

BO_ 860 CCU_VCU_7: 64 CCU
 SG_ VCU_VehRdySt : 39|1@0+ (1,0) [0|1] ""  CCURT2,ZCUF,ZCUL,ZCUR,ZCUT,EMS,IPS,MCU,DCU2,IDUR,OBC,GCU,DCU,IPU,BMS,ECS,IBCS,ICM,IID,IDC,ADC,IFC,RRR,RLR
 SG_ VCU_PlgConnSt : 91|1@0+ (1,0) [0|1] ""  CCURT2,ZCUR,ZCUT,MCU,DCU2,IDUR,GCU,DCU,IPU,ECS,ICM,IID,IDC,ADC,IFC

BO_ 516 CCU_VCU_9: 64 CCU
 SG_ VCU_9_CRC : 7|16@0+ (1,0) [0|65535] ""  CCURT2,ZCUF,ZCUL,ZCUR,ZCUT,EMS,MCU,DCU2,IDUR,ECS,IBCS,ICM,IDC,INU,ADC,IFC,RRR,RLR,PAS
 SG_ VCU_9_Counter : 23|8@0+ (1,0) [0|255] ""  CCURT2,ZCUF,ZCUL,ZCUR,ZCUT,EMS,MCU,DCU2,IDUR,ECS,IBCS,ICM,IDC,INU,ADC,IFC,RRR,RLR,PAS
 SG_ VCU_CrntGearLvl : 92|3@0+ (1,0) [0|7] ""  CCURT2,ZCUF,ZCUL,ZCUR,ZCUT,MCU,DCU2,IDUR,DCU,IPU,SRS,ECS,EPS,IBCS,IDC,AMP,INU,ADC,IFC,RRR,RLR,PAS,DLPML,DLPMR,TBOX
 SG_ VCU_BrkPedPstVD : 89|1@0+ (1,0) [0|1] ""  CCURT2,MCU,DCU2,IDUR,SRS,ECS,IBCS,IDC,ADC,IFC
 SG_ VCU_BrkPedPst : 103|8@0+ (0.392,0) [0|99.96] "%"  CCURT2,MCU,DCU2,IDUR,SRS,ECS,IBCS,IDC,ADC,IFC
 SG_ VCU_EMS_AccPedalActPst : 127|8@0+ (0.392,0) [0|99.96] "%"  CCURT2,EMS,MCU,DCU2,IDUR,SRS,ECS,IBCS,IDC,AMP,ADC,IFC,RRR,RLR
 SG_ VCU_EMS_AccPedalActPstVD : 136|1@0+ (1,0) [0|1] ""  CCURT2,EMS,MCU,DCU2,IDUR,SRS,ECS,IBCS,IDC,AMP,ADC,IFC
 SG_ VCU_HTMSMTCoolantTemp : 223|8@0+ (1,-40) [-40|213] "degC"  EMS,DCDC,IPS,MCU,GCU,DCU,IPU
 SG_ VCU_HTMSMTCoolantTempVD : 211|1@0+ (1,0) [0|1] ""  EMS,DCDC,IPS,MCU,GCU,DCU,IPU

BO_ 616 CCU_1: 64 CCU
 SG_ CCU_1_CRC : 7|16@0+ (1,0) [0|65535] ""  CCURT2,ZCUF,ZCUL,ZCUR,ZCUT,MCU,DCU2,BMS,ICM,IDC
 SG_ CCU_1_Counter : 23|8@0+ (1,0) [0|255] ""  CCURT2,ZCUF,ZCUL,ZCUR,ZCUT,MCU,DCU2,BMS,ICM,IDC
 SG_ UMM_UsageModeSt : 26|3@0+ (1,0) [0|7] ""  CCURT2,TMC,ZCUF,ZCUL,ZCUR,ZCUT,PCU,TCU,EMS,DCDC,IPS,MCU,DCU2,IDUR,OBC,OPC,LPC,CPC,GCU,DCU,IPU,BMS,EOP,SRS,ECS,EPS,IBCS,ICM,IID,IDC,RCICP,AMP,WHUD,IMR,CD,INU,ADC,IFC,RRR,RLR,PAS,SCMR,SCMRR,SCMRL,SCMRM,SCMT,MFS,FCP,RCP,AVAS,DLPFL,FBLCM,FLISD,FLLCM,FRLCM,RLLCMA,RLLCMB,RRLCMA,RRLCMB,RLISD,RRISD,DLPML,DLPMR,PSDL,PSDR,HVSPRL,HVSPRR,LBMS,TBOX
 SG_ VMM_VehModeSt : 159|4@0+ (1,0) [0|15] ""  CCURT2,TMC,ZCUF,ZCUL,ZCUR,ZCUT,PADS,VDC,GSM,PCU,TCU,EMS,DCDC,IPS,MCU,DCU2,IDUR,OBC,OPC,LPC,CPC,GCU,DCU,IPU,BMS,EOP,SRS,ECS,EPS,EPB,IBCS,RBM,ICM,IDC,RCICP,AMP,WHUD,IMR,ADC,IFC,RRR,RLR,RADARRR,RADARRL,RADARFR,RADARFL,PAS,RPC,FR,RADARFRT,RADARR,SCMR,SCMRR,SCMRL,SCMT,MFS,FCP,RCP,AVAS,DLPFL,FBLCM,FLISD,FLLCM,FRLCM,RLLCMA,RLLCMB,RRLCMA,RRLCMB,RLISD,RRISD,DLPML,DLPMR,PSDL,PSDR,HVSPRL,HVSPRR,LBMS,UWB,RFR,SBM,WCM,ETC,TBOX
 SG_ VMM_LastVehModeSt : 155|4@0+ (1,0) [0|15] ""  TMC,ZCUF,ZCUL,ZCUR,ZCUT,PADS,VDC,GSM,PCU,TCU,EMS,DCDC,IPS,MCU,DCU2,IDUR,OBC,OPC,LPC,CPC,GCU,DCU,IPU,BMS,SRS,EPS,EPB,IBCS,RBM,ICM,IDC,AMP,ADC,IFC,RADARRR,RADARRL,RADARFR,RADARFL,PAS,RPC,FR,RADARFRT,RADARR,SCMR,SCMRR,SCMRL,MFS,RCP,AVAS,FLLCM,FRLCM,PSDL,UWB,RFR,SBM,WCM,ETC,TBOX
 SG_ VMM_OTAModeSt : 167|2@0+ (1,0) [0|3] ""  CCURT2,ZCUF,ZCUL,ZCUR,ZCUT,PADS,VDC,GSM,PCU,TCU,EMS,DCDC,IPS,MCU,DCU2,IDUR,OBC,OPC,LPC,CPC,GCU,DCU,IPU,BMS,EOP,SRS,ECS,EPS,EPB,IBCS,RBM,ICM,IDC,RCICP,AMP,WHUD,ADC,IFC,RRR,RLR,RADARRR,RADARRL,RADARFR,RADARFL,PAS,RPC,FR,RADARFRT,RADARR,SCMR,SCMRR,SCMRL,SCMT,MFS,RCP,AVAS,DLPFL,FBLCM,FLISD,FLLCM,FRLCM,RLLCMA,RLLCMB,RRLCMA,RRLCMB,RLISD,RRISD,DLPML,DLPMR,PSDL,PSDR,HVSPRL,HVSPRR,LBMS,UWB,RFR,SBM,WCM,ETC,TBOX
 SG_ IPDS_DysWakeupPowerSup : 322|2@0+ (1,0) [0|3] ""  ZCUR,EMS,IPS,MCU,BMS,Rema1
 SG_ IPDS_EnablePowerSup : 327|2@0+ (1,0) [0|3] ""  CCURT2,ZCUF,ZCUL,ZCUR,ZCUT,PCU,TCU,EMS,IPS,MCU,DCU2,IDUR,OBC,OPC,LPC,CPC,GCU,DCU,IPU,BMS,SRS,ECS,IBCS,ICM,IID,IDC,ADC,PCS
 SG_ Time_Year : 343|8@0+ (1,2000) [2000|2255] "y"  CCURT2,TMC,ZCUF,ZCUL,ZCUR,ZCUT,TCU,EMS,DCDC,IPS,MCU,DCU2,IDUR,OBC,OPC,LPC,CPC,GCU,DCU,IPU,BMS,EOP,SRS,ECS,EPS,IBCS,RCICP,AMP,WHUD,IMR,INU,ADC,IFC,RRR,RLR,PAS,PCS,SCMR,SCMRR,SCMRL,SCMT,MFS,RCP,DLPFL,FBLCM,FLISD,FLLCM,FRLCM,RLLCMA,RLLCMB,RRLCMA,RRLCMB,RLISD,RRISD,DLPML,DLPMR,PSDL,PSDR,LBMS
 SG_ Time_Month : 351|4@0+ (1,0) [1|12] "m"  CCURT2,TMC,ZCUF,ZCUL,ZCUR,ZCUT,TCU,EMS,DCDC,IPS,MCU,DCU2,IDUR,OBC,OPC,LPC,CPC,GCU,DCU,IPU,BMS,EOP,SRS,ECS,EPS,IBCS,RCICP,AMP,WHUD,IMR,INU,ADC,IFC,RRR,RLR,PAS,PCS,SCMR,SCMRR,SCMRL,SCMT,MFS,RCP,DLPFL,FBLCM,FLISD,FLLCM,FRLCM,RLLCMA,RLLCMB,RRLCMA,RRLCMB,RLISD,RRISD,DLPML,DLPMR,PSDL,PSDR,LBMS
 SG_ Time_Day : 347|5@0+ (1,0) [1|31] "d"  CCURT2,TMC,ZCUF,ZCUL,ZCUR,ZCUT,TCU,EMS,DCDC,IPS,MCU,DCU2,IDUR,OBC,OPC,LPC,CPC,GCU,DCU,IPU,BMS,EOP,SRS,ECS,EPS,IBCS,RCICP,AMP,WHUD,IMR,INU,ADC,IFC,RRR,RLR,PAS,PCS,SCMR,SCMRR,SCMRL,SCMT,MFS,RCP,DLPFL,FBLCM,FLISD,FLLCM,FRLCM,RLLCMA,RLLCMB,RRLCMA,RRLCMB,RLISD,RRISD,DLPML,DLPMR,PSDL,PSDR,LBMS
 SG_ Time_Hour : 358|5@0+ (1,0) [0|23] "h"  CCURT2,TMC,ZCUF,ZCUL,ZCUR,ZCUT,TCU,EMS,DCDC,IPS,MCU,DCU2,IDUR,OBC,OPC,LPC,CPC,GCU,DCU,IPU,BMS,EOP,SRS,ECS,EPS,IBCS,RCICP,AMP,WHUD,IMR,INU,ADC,IFC,RRR,RLR,PAS,PCS,SCMR,SCMRR,SCMRL,SCMT,MFS,RCP,DLPFL,FBLCM,FLISD,FLLCM,FRLCM,RLLCMA,RLLCMB,RRLCMA,RRLCMB,RLISD,RRISD,DLPML,DLPMR,PSDL,PSDR,LBMS
 SG_ Time_Min : 353|6@0+ (1,0) [0|59] "min"  CCURT2,TMC,ZCUF,ZCUL,ZCUR,ZCUT,TCU,EMS,DCDC,IPS,MCU,DCU2,IDUR,OBC,OPC,LPC,CPC,GCU,DCU,IPU,BMS,EOP,SRS,ECS,EPS,IBCS,RCICP,AMP,WHUD,IMR,INU,ADC,IFC,RRR,RLR,PAS,PCS,SCMR,SCMRR,SCMRL,SCMT,MFS,RCP,DLPFL,FBLCM,FLISD,FLLCM,FRLCM,RLLCMA,RLLCMB,RRLCMA,RRLCMB,RLISD,RRISD,DLPML,DLPMR,PSDL,PSDR,LBMS
 SG_ Time_Sec : 363|6@0+ (1,0) [0|59] "s"  CCURT2,TMC,ZCUF,ZCUL,ZCUR,ZCUT,TCU,EMS,DCDC,IPS,MCU,DCU2,IDUR,OBC,OPC,LPC,CPC,GCU,DCU,IPU,BMS,EOP,SRS,ECS,EPS,IBCS,RCICP,AMP,WHUD,IMR,INU,ADC,IFC,RRR,RLR,PAS,PCS,SCMR,SCMRR,SCMRL,SCMT,MFS,RCP,DLPFL,FBLCM,FLISD,FLLCM,FRLCM,RLLCMA,RLLCMB,RRLCMA,RRLCMB,RLISD,RRISD,DLPML,DLPMR,PSDL,PSDR,LBMS

BO_ 816 CCU_2: 64 CCU
 SG_ HVAC_CorrectedExterTemp : 135|8@0+ (0.5,-40) [-40|87.5] "°C"  CCURT1,CCURT2,TMC,ZCUF,ZCUL,ZCUR,ZCUT,TCU,EMS,IPS,MCU,DCU2,IDUR,OBC,GCU,DCU,IPU,BMS,ECS,IBCS,ICM,IDC,ADC,IFC,PAS
 SG_ HVAC_CorrectedExterTempVD : 143|1@0+ (1,0) [0|1] ""  CCURT1,CCURT2,TMC,ZCUF,ZCUL,ZCUR,ZCUT,TCU,EMS,IPS,MCU,DCU2,IDUR,OBC,GCU,DCU,IPU,BMS,IBCS,ICM,IDC,ADC,IFC,PAS
 SG_ HVAC_PTCHeatingReq : 142|7@0+ (1,0) [0|100] "%"  CCURT1,TMC,ZCUF,ZCUL,MCU,DCU2
 SG_ HVAC_PTCSt : 168|1@0+ (1,0) [0|1] ""  CCURT1,TMC,MCU,DCU2
 SG_ HVAC_ECPPwrConsump : 367|11@0+ (10,0) [0|20320] "W"  CCURT1,TMC,MCU,DCU2,BMS,ICM,IDC
 SG_ HVAC_PTCOnReq : 427|2@0+ (1,0) [0|3] ""  CCURT1,TMC,ZCUF,ZCUL,MCU,DCU2

BO_ 960 TMS_4: 64 CCU
 SG_ TMS_4_CRC : 7|16@0+ (1,0) [0|65535] ""  MCU,DCU2,GCU,Rema1
 SG_ TMS_4_Counter : 23|8@0+ (1,0) [0|255] ""  MCU,DCU2,GCU,Rema1
 SG_ TMS_WtrPmp1DutyReq : 50|7@0+ (1,0) [0|100] "%"  TMC,ZCUF,ZCUL,MCU,DCU2,GCU,Rema1
 SG_ TMS_WtrPmp1PerdReq : 59|9@0+ (100,0) [0|50000] "us"  TMC,ZCUF,ZCUL,MCU,DCU2,GCU,Rema1
 SG_ TMS_MotRadrOutCooltT : 200|9@0+ (0.5,-50) [-50|200] "degC"  TMC,EMS,DCDC,IPS,MCU,DCU2,IDUR,OBC,GCU,IPU,BMS,ADC,Rema1
 SG_ TMS_MotRadrOutCooltTVld : 223|1@0+ (1,0) [0|1] ""  TMC,EMS,DCDC,IPS,MCU,DCU2,IDUR,OBC,GCU,IPU,BMS,ADC,Rema1
 SG_ TMS_WtrPmp1Fault : 264|1@0+ (1,0) [0|1] ""  TMC,ZCUF,ZCUL,EMS,MCU,DCU2,GCU,IPU,ADC,Rema1
 SG_ TMS_MotRadrInCooltTFault : 300|2@0+ (1,0) [0|3] ""  MCU,Rema1
 SG_ TMS_MotRadrInCooltT : 390|9@0+ (0.5,-50) [-50|200] "degC"  MCU,Rema1

BO_ 290 CCU_PowerOn: 64 CCU
 SG_ IPDS_RearEOPPowerSup : 131|2@0+ (1,0) [0|3] ""  CCURT2,ZCUR,ZCUT,MCU,DCU2
 SG_ IPDS_KL15T1PowerSup : 169|2@0+ (1,0) [0|3] ""  CCURT2,ZCUR,ZCUT,MCU,DCU2

BO_ 1359 CCU_NM: 8 CCU
 SG_ CCU_NMNodeAddress : 7|8@0+ (1,0) [0|255] ""  CCURT1,ZCUF,ZCUL,ZCUR,ZCUT,TCU,EMS,DCDC,IPS,MCU,OBC,OPC,GCU,DCU,IPU,BMS,ECS,IBCS,ICM,IDC,AMP,ADC,SCMR,SCMRR,SCMRL,SCMRM,SCMT,MFS,PLGM,PSDL,PSDR,LBMS,TBOX
 SG_ CCU_NMCBV : 15|8@0+ (1,0) [0|0] ""  CCURT1,ZCUF,ZCUL,ZCUR,ZCUT,TCU,EMS,DCDC,IPS,MCU,OBC,OPC,GCU,DCU,IPU,BMS,ECS,IBCS,ICM,IDC,AMP,ADC,SCMR,SCMRR,SCMRL,SCMRM,SCMT,MFS,PLGM,PSDL,PSDR,LBMS,TBOX
 SG_ CCU_NMWakeupOrigin : 23|8@0+ (1,0) [0|255] ""  CCURT1,ZCUF,ZCUL,ZCUR,ZCUT,TCU,EMS,DCDC,IPS,MCU,OBC,OPC,GCU,DCU,IPU,BMS,ECS,IBCS,ICM,IDC,AMP,ADC,SCMR,SCMRR,SCMRL,SCMRM,SCMT,MFS,PLGM,PSDL,PSDR,LBMS,TBOX
 SG_ CCU_PNCInformation0 : 31|8@0+ (1,0) [0|255] ""  CCURT1,ZCUF,ZCUL,ZCUR,ZCUT,TCU,EMS,DCDC,IPS,MCU,OBC,OPC,GCU,DCU,IPU,BMS,ECS,IBCS,ICM,IDC,AMP,ADC,SCMR,SCMRR,SCMRL,SCMRM,SCMT,MFS,PLGM,PSDL,PSDR,LBMS,TBOX
 SG_ CCU_PNCInformation1 : 39|8@0+ (1,0) [0|0] ""  CCURT1,ZCUF,ZCUL,ZCUR,ZCUT,TCU,EMS,DCDC,IPS,MCU,OBC,OPC,GCU,DCU,IPU,BMS,ECS,IBCS,ICM,IDC,AMP,ADC,SCMR,SCMRR,SCMRL,SCMRM,SCMT,MFS,PLGM,PSDL,PSDR,LBMS,TBOX
 SG_ CCU_PNCInformation2 : 47|24@0+ (1,0) [0|0] ""  CCURT1,ZCUF,ZCUL,ZCUR,ZCUT,TCU,EMS,DCDC,IPS,MCU,OBC,OPC,GCU,DCU,IPU,BMS,ECS,IBCS,ICM,IDC,AMP,ADC,SCMR,SCMRR,SCMRL,SCMRM,SCMT,MFS,PLGM,PSDL,PSDR,LBMS,TBOX

BO_ 352 CCU_BCS_2_C: 64 CCU
 SG_ BCS_2_CRC : 7|16@0+ (1,0) [0|65535] ""  ZCUF,ZCUL,ZCUR,ZCUT,IPS,MCU,DCU2,IDUR,OBC,DCU,IPU,ICM,IDC,INU,ADC,IFC,RRR,RLR,FLISD,RLLCMA,RLLCMB,RRLCMA,RRLCMB,PSDL,PSDR
 SG_ BCS_2_Counter : 23|8@0+ (1,0) [0|255] ""  ZCUF,ZCUL,ZCUR,ZCUT,IPS,MCU,DCU2,IDUR,OBC,DCU,IPU,ICM,IDC,INU,ADC,IFC,RRR,RLR,FLISD
 SG_ BCS_VehSpd : 31|13@0+ (0.05625,0) [0|240] "km/h"  TMC,ZCUF,ZCUL,ZCUR,ZCUT,PCU,TCU,EMS,DCDC,IPS,MCU,DCU2,IDUR,OBC,OPC,LPC,CPC,GCU,DCU,IPU,BMS,EDL,ICM,IID,IDC,AMP,IMR,INU,ADC,IFC,RRR,RLR,PAS,PCS,SCMR,SCMRR,SCMRL,SCMRM,SCMT,MFS,RCP,AVAS,DLPFL,FBLCM,FLISD,FLLCM,FRLCM,RLLCMA,RLLCMB,RRLCMA,RRLCMB,RLISD,RRISD,DLPML,DLPMR,PSDL,PSDR,LBMS,TBOX
 SG_ BCS_VehSpdVD : 34|1@0+ (1,0) [0|1] ""  TMC,ZCUF,ZCUL,ZCUR,ZCUT,PCU,TCU,EMS,DCDC,IPS,MCU,DCU2,IDUR,OBC,OPC,LPC,CPC,GCU,DCU,IPU,BMS,ICM,IID,IDC,AMP,IMR,INU,ADC,IFC,RRR,RLR,PAS,SCMR,SCMRR,SCMRL,SCMRM,SCMT,MFS,RCP,AVAS,DLPFL,FBLCM,FLISD,FLLCM,FRLCM,RLLCMA,RLLCMB,RRLCMA,RRLCMB,RLISD,RRISD,DLPML,DLPMR,PSDL,PSDR,LBMS,TBOX
 SG_ BCS_EBDActiveSt : 32|1@0+ (1,0) [0|1] ""  ZCUF,ZCUL,MCU,DCU2,ADC,IFC,RRR,RLR
 SG_ BCS_EBDFaultSt : 47|1@0+ (1,0) [0|1] ""  ZCUF,ZCUL,MCU,DCU2,ICM,IID,IDC,ADC,IFC
 SG_ BCS_ABSActiveSt : 46|1@0+ (1,0) [0|1] ""  ZCUF,ZCUL,MCU,DCU2,IDUR,ADC,IFC,RRR,RLR
 SG_ BCS_ABSFaultSt : 45|1@0+ (1,0) [0|1] ""  ZCUF,ZCUL,MCU,DCU2,IDUR,ICM,IID,IDC,ADC,IFC,TBOX
 SG_ BCS_TCSActiveSt : 44|1@0+ (1,0) [0|1] ""  ZCUF,ZCUL,ZCUR,ZCUT,TCU,MCU,DCU2,IDUR,ICM,IID,IDC,ADC,IFC,RRR,RLR
 SG_ BCS_TCSFaultSt : 43|1@0+ (1,0) [0|1] ""  ZCUF,ZCUL,ZCUR,ZCUT,TCU,MCU,DCU2,IDUR,ICM,IID,IDC,ADC,IFC,RRR,RLR
 SG_ BCS_VDCActiveSt : 42|1@0+ (1,0) [0|1] ""  ZCUF,ZCUL,MCU,DCU2,IDUR,ICM,IID,IDC,ADC,IFC,RRR,RLR,PCS
 SG_ BCS_VDCFaultSt : 41|1@0+ (1,0) [0|1] ""  ZCUF,ZCUL,TCU,MCU,DCU2,IDUR,ICM,IID,IDC,ADC,IFC,RRR,RLR
 SG_ BCS_RegenModulationAvailable : 64|1@0+ (1,0) [0|1] ""  ZCUF,ZCUL,MCU,DCU2,IDUR,ADC,IFC
 SG_ BCS_RegenModuleActive : 79|1@0+ (1,0) [0|1] ""  ZCUF,ZCUL,MCU,DCU2,IDUR,ADC,IFC
 SG_ BCS_DMCTarSpdFA : 135|16@0+ (1,-32767) [-32767|32766] "rpm"  ZCUF,ZCUL,MCU,DCU2,DCU,IPU
 SG_ BCS_DMCCtrModeFA : 151|3@0+ (1,0) [0|7] "NA"  ZCUF,ZCUL,MCU,DCU2,DCU,IPU
 SG_ BCS_DMCVariant : 148|6@0+ (1,0) [0|63] "NA"  ZCUF,ZCUL,MCU,DCU2,IDUR,DCU,IPU
 SG_ BCS_DMCTarSpdRA : 167|16@0+ (1,-32767) [-32767|32766] "rpm"  ZCUF,ZCUL,MCU,DCU2,IDUR,IPU
 SG_ BCS_DMCCtrModeRA : 183|3@0+ (1,0) [0|7] "NA"  ZCUF,ZCUL,MCU,DCU2,IDUR,IPU
 SG_ BCS_EngTorqDecActiveStRA : 233|1@0+ (1,0) [0|1] ""  MCU,DCU2,IDUR,ADC,IFC

BO_ 398 CCU_EMS_1: 48 CCU
 SG_ EMS_EngSpd : 31|16@0+ (1,0) [0|65535] "rpm"  IPS,MCU,DCU2,IDUR,OBC,GCU,DCU,IPU,BMS
 SG_ EMS_EngSpdVD : 48|1@0+ (1,0) [0|1] ""  IPS,MCU,DCU2,IDUR,OBC,GCU,DCU,IPU,BMS
 SG_ EMS_EngIdleRefSpd : 47|12@0+ (1,0) [0|4095] "rpm"  MCU,DCU2,IDUR,GCU,DCU,IPU
 SG_ EMS_OBDDrivingCycleStForPDTC : 60|1@0+ (1,0) [0|1] ""  IPS,MCU,DCU2,IDUR,OBC,GCU,DCU,IPU,BMS
 SG_ EMS_OBDWarmUpCycleSt : 61|1@0+ (1,0) [0|1] ""  IPS,MCU,DCU2,IDUR,OBC,GCU,DCU,IPU,BMS
 SG_ EMS_AbsoluteThrottlepst : 79|8@0+ (0.392,0) [0|99.96] "%"  IPS,MCU,DCU2,IDUR,OBC,GCU,DCU,IPU,BMS
 SG_ EMS_EngWaterTemp : 159|8@0+ (1,-40) [-40|214] "deg C"  IPS,MCU,DCU2,IDUR,OBC,GCU,DCU,IPU,BMS
 SG_ EMS_EngWaterTempVD : 160|1@0+ (1,0) [0|1] ""  IPS,MCU,DCU2,IDUR,OBC,GCU,DCU,IPU,BMS
 SG_ EMS_EngCalculatedLoad : 207|8@0+ (0.392,0) [0|99.96] "%"  IPS,MCU,DCU2,IDUR,OBC,GCU,DCU,IPU,BMS

BO_ 445 CCU_EMS_2: 48 CCU
 SG_ EMS_IUPRGenInh : 36|1@0+ (1,0) [0|1] ""  IPS,MCU,DCU2,IDUR,OBC,GCU,DCU,IPU,BMS
 SG_ EMS_IURPGenDen : 37|1@0+ (1,0) [0|1] ""  IPS,MCU,DCU2,IDUR,OBC,GCU,DCU,IPU,BMS
 SG_ EMS_IUPRIgCnt : 38|1@0+ (1,0) [0|1] ""  IPS,MCU,DCU2,IDUR,OBC,GCU,DCU,IPU,BMS

BO_ 407 CCU_EMS_3: 32 CCU
 SG_ EMS_EngRunningTime : 87|8@0+ (1,0) [0|200] "s"  IPS,MCU,DCU2,IDUR,OBC,GCU,DCU,IPU,BMS

BO_ 905 CCU_IDC_ICM_1: 64 CCU
 SG_ ICM_TotalOdometer : 35|20@0+ (1,0) [0|999999] "km"  ZCUF,ZCUL,ZCUR,ZCUT,TCU,EMS,MCU,DCU2,IDUR,GCU,DCU,IPU,ECS,EPS,IBCS,ADC,IFC,RRR,RLR,PCS

BO_ 161 CCU_IDC_1: 64 CCU
 SG_ ACU_ACChgCurCfg : 209|5@0+ (1,0) [0|31] ""  IPS,MCU,Rema2

BO_ 909 CCU_ZCU_1: 64 CCU
 SG_ WtrPmp1DutyFb : 76|7@0+ (1,0) [0|100] "%"  MCU,DCU2,Rema1
 SG_ IPDS_RearMotorPowerSt : 228|1@0+ (1,0) [0|1] ""  MCU,DCU2,EOP,Rema1
 SG_ IPDS_RearEOPPowerSt : 223|1@0+ (1,0) [0|1] ""  MCU,DCU2,Rema1
 SG_ IPDS_RearMotorPowerFaultSt : 218|3@0+ (1,0) [0|7] ""  MCU,DCU2,EOP,Rema1
 SG_ IPDS_RearEOPPowerFaultSt : 221|3@0+ (1,0) [0|7] ""  MCU,DCU2,Rema1
 SG_ IPDS_KL15T1PowerSt : 222|1@0+ (1,0) [0|1] ""  MCU,DCU2,Rema1

BO_ 2683306021 DCU2_DEBUG_1: 32 MCU
 SG_ DCU2_BSWVersion_Debug : 112|32@0+ (1,0) [0|4294967295] ""  Tester
 SG_ DCU2_OffsetCalSt : 114|2@0+ (1,0) [0|3] ""  Tester
 SG_ DCU2_OffsetAngleCal : 15|16@0+ (1,0) [0|65535] ""  Tester
 SG_ DCU2_EOP_OilTempAct : 7|8@0+ (1,-40) [-40|180] "degC"  Tester
 SG_ DCU2_Debug_1Bit_1 : 95|1@0+ (1,0) [0|1] "-"  Tester
 SG_ DCU2_Ignition : 94|1@0+ (1,0) [0|1] ""  Tester
 SG_ DCU2_OffsetAngle_Debug : 91|12@0+ (1,0) [0|4095] "-"  Tester
 SG_ DCU2_StoreDataSt : 93|2@0+ (1,0) [0|3] ""  Tester
 SG_ DCU2_SendDataSt : 115|1@0+ (1,0) [0|1] ""  Tester
 SG_ DCU2_BootSV_Debug : 111|12@0+ (1,0) [0|4095] "-"  Tester
 SG_ DCU2_Hwversion_Debug : 31|16@0+ (1,0) [0|65535] "-"  Tester
 SG_ DCU2_Swversion_Debug : 47|16@0+ (1,0) [0|65535] "-"  Tester
 SG_ DCU2_SwVerExt_Debug : 63|32@0+ (1,0) [0|4294967295] "-"  Tester

BO_ 2683306010 DCU2_DEBUG_2: 32 MCU
 SG_ DCU2_CapTemp_Debug : 23|8@0+ (1,-40) [-40|215] "degC"  Tester
 SG_ DCU2_CtlBoardTemp_Debug : 15|8@0+ (1,-40) [-40|215] "degC"  Tester
 SG_ DCU2_PWMFreq_Debug : 63|12@0+ (10,0) [0|40950] "Hz"  Tester
 SG_ DCU2_IgbtNtcTempMax : 7|8@0+ (1,-40) [-40|215] "degC"  Tester
 SG_ DCU2_Debug_1Bit_2 : 67|1@0+ (1,0) [0|1] "-"  Tester
 SG_ DCU2_Debug_1Bit_3 : 66|1@0+ (1,0) [0|1] ""  Tester
 SG_ DCU2_Debug_16Bit_2 : 31|16@0+ (1,0) [0|65535] ""  Tester
 SG_ DCU2_Debug_16Bit_3 : 47|16@0+ (1,0) [0|65535] ""  Tester

BO_ 2683305995 DCU2_DEBUG_3: 64 MCU
 SG_ DCU2_FusaFaultInfo8_Debug : 461|32@0+ (1,0) [0|4294967295] ""  Tester
 SG_ DCU2_FusaFaultInfo7_Debug : 429|32@0+ (1,0) [0|4294967295] ""  Tester
 SG_ DCU2_TempCoolant : 421|8@0+ (1,-40) [-40|215] "degC"  Tester
 SG_ DCU2_FusaTorqAct_Debug : 402|13@0+ (0.2,-819) [-819|819] ""  Tester
 SG_ DCU2_FusaRotSpdAct_Debug : 386|16@0+ (1,-32767) [-32767|32766] ""  Tester
 SG_ DCU2_FusaErrCode_Debug : 376|6@0+ (1,0) [0|63] ""  Tester
 SG_ DCU2_FusastPWMEna_Debug : 377|1@0+ (1,0) [0|1] ""  Tester
 SG_ DCU2_FusaQDisChargeReq_Debug : 378|1@0+ (1,0) [0|0] ""  Tester
 SG_ DCU2_FusaModeSt_Debug : 382|4@0+ (1,0) [0|15] ""  Tester
 SG_ DCU2_FusastSafePathReq_Debug : 369|3@0+ (1,0) [0|7] ""  Tester
 SG_ DCU2_DataFaultHandle : 373|4@0+ (1,0) [0|15] ""  Tester
 SG_ DCU2_stTorqLmtTsc : 240|22@0+ (1,0) [0|4194303] "-"  Tester
 SG_ DCU2_TrqAntiJerk : 7|8@0+ (1,-127) [-127|128] "Nm"  Tester
 SG_ DCU2_TrefFinal_Debug : 266|11@0+ (1,-1000) [-1000|1047] "Nm"  Tester
 SG_ DCU2_Iq_Debug : 287|15@0+ (0.1,-1500) [-1500|1776.7] "A"  Tester
 SG_ DCU2_Id_Debug : 288|15@0+ (0.1,-1500) [-1500|1776.7] "A"  Tester
 SG_ DCU2_Debug_1Bit_4 : 239|1@0+ (1,0) [0|1] ""  Tester
 SG_ DCU2_Debug_8Bit_4 : 15|8@0+ (1,0) [0|255] "-"  Tester
 SG_ DCU2_Debug_16Bit_4 : 23|16@0+ (1,0) [0|65535] "-"  Tester
 SG_ DCU2_Fault6_Debug : 39|32@0+ (1,0) [0|65535] ""  Tester
 SG_ DCU2_Fault5_Debug : 71|32@0+ (1,0) [0|65535] "-"  Tester
 SG_ DCU2_Fault4_Debug : 103|32@0+ (1,0) [0|65535] "-"  Tester
 SG_ DCU2_Fault3_Debug : 135|32@0+ (1,0) [0|1048575] "-"  Tester
 SG_ DCU2_Fault2_Debug : 167|32@0+ (1,0) [0|1048575] "-"  Tester
 SG_ DCU2_Fault1_Debug : 199|32@0+ (1,0) [0|1048575] "-"  Tester
 SG_ DCU2_TjMax : 231|8@0+ (1,-40) [-40|215] "degC"  Tester
 SG_ DCU2_VoltUtilRatio : 238|7@0+ (0.01,0) [0|1.27] ""  Tester
 SG_ DCU2_TorqueRatio : 247|7@0+ (0.01,0) [0|1.27] ""  Tester
 SG_ DCU2_iCurqRef_Debug : 305|15@0+ (0.1,-1500) [-1500|1776.7] "A"  Tester
 SG_ DCU2_iCurdRef_Debug : 322|15@0+ (0.1,-1500) [-1500|1776.7] "A"  Tester
 SG_ DCU2_uVoltqRef : 339|15@0+ (0.1,-1500) [-1500|1776.7] "V"  Tester
 SG_ DCU2_uVoltdRef : 356|15@0+ (0.1,-1500) [-1500|1776.7] "V"  Tester

BO_ 2683305992 DCU2_DEBUG_4: 32 MCU
 SG_ DCU2_DMC_BCSDbgSig1 : 7|16@0+ (1,-30000) [-30000|30000] ""  Tester
 SG_ DCU2_DMC_BCSDbgSig2 : 23|16@0+ (1,-30000) [-30000|30000] ""  Tester
 SG_ DCU2_DMC_BCSDbgSig3 : 103|3@0+ (1,0) [0|7] ""  Tester
 SG_ DCU2_DMC_BCSDbgSig4 : 100|3@0+ (1,0) [0|7] ""  Tester
 SG_ DCU2_DMC_BCSDbgSig5 : 39|16@0+ (1,-32767) [-32767|32766] ""  Tester
 SG_ DCU2_DMC_BCSDbgSig6 : 55|16@0+ (1,-32767) [-32767|32766] ""  Tester
 SG_ DCU2_DMC_BCSDbgSig7 : 143|11@0+ (1,-1023) [-1023|1024] ""  Tester
 SG_ DCU2_DMC_BCSDbgSig8 : 97|10@0+ (1,0) [0|1023] ""  Tester
 SG_ DCU2_DMC_BCSDbgSig9 : 113|10@0+ (1,-1023) [-1023|0] ""  Tester
 SG_ DCU2_DMC_BCSDbgSig10 : 71|16@0+ (1,-30000) [-30000|30000] ""  Tester
 SG_ DCU2_DMC_BCSDbgSig11 : 87|16@0+ (1,-30000) [-30000|30000] ""  Tester
 SG_ DCU2_DMC_BCSDbgSig12 : 119|6@0+ (1,0) [0|63] ""  Tester

BO_ 2683305998 DCU2_DEBUG_5: 64 MCU
 SG_ DCU2_OSC_Signal1 : 7|8@0+ (1,0) [0|255] ""  Tester
 SG_ DCU2_OSC_Signal2 : 15|8@0+ (1,0) [0|255] ""  Tester
 SG_ DCU2_OSC_Signal3 : 23|8@0+ (1,0) [0|255] ""  Tester
 SG_ DCU2_OSC_Signal4 : 31|8@0+ (1,0) [0|255] ""  Tester
 SG_ DCU2_OSC_Signal5 : 39|8@0+ (1,0) [0|255] ""  Tester
 SG_ DCU2_OSC_Signal6 : 47|8@0+ (1,0) [0|255] ""  Tester
 SG_ DCU2_OSC_Signal7 : 55|8@0+ (1,0) [0|255] ""  Tester
 SG_ DCU2_OSC_Signal8 : 63|8@0+ (1,0) [0|255] ""  Tester
 SG_ DCU2_OSC_Signal9 : 71|8@0+ (1,0) [0|255] ""  Tester
 SG_ DCU2_OSC_Signal10 : 79|8@0+ (1,0) [0|255] ""  Tester
 SG_ DCU2_OSC_Signal11 : 87|8@0+ (1,0) [0|255] ""  Tester
 SG_ DCU2_OSC_Signal12 : 95|8@0+ (1,0) [0|255] ""  Tester
 SG_ DCU2_OSC_Signal13 : 103|8@0+ (1,0) [0|255] ""  Tester
 SG_ DCU2_OSC_Signal14 : 111|8@0+ (1,0) [0|255] ""  Tester
 SG_ DCU2_OSC_Signal15 : 119|8@0+ (1,0) [0|255] ""  Tester
 SG_ DCU2_OSC_Signal16 : 127|8@0+ (1,0) [0|255] ""  Tester
 SG_ DCU2_OSC_Signal17 : 135|8@0+ (1,0) [0|255] ""  Tester
 SG_ DCU2_OSC_Signal18 : 143|8@0+ (1,0) [0|255] ""  Tester
 SG_ DCU2_OSC_Signal19 : 151|8@0+ (1,0) [0|255] ""  Tester
 SG_ DCU2_OSC_Signal20 : 159|8@0+ (1,0) [0|255] ""  Tester
 SG_ DCU2_OSC_Signal21 : 167|8@0+ (1,0) [0|255] ""  Tester
 SG_ DCU2_OSC_Signal22 : 175|8@0+ (1,0) [0|255] ""  Tester
 SG_ DCU2_OSC_Signal23 : 183|8@0+ (1,0) [0|255] ""  Tester
 SG_ DCU2_OSC_Signal24 : 191|8@0+ (1,0) [0|255] ""  Tester
 SG_ DCU2_OSC_Signal25 : 199|8@0+ (1,0) [0|255] ""  Tester
 SG_ DCU2_OSC_Signal26 : 207|8@0+ (1,0) [0|255] ""  Tester
 SG_ DCU2_OSC_Signal27 : 215|8@0+ (1,0) [0|255] ""  Tester
 SG_ DCU2_OSC_Signal28 : 223|8@0+ (1,0) [0|255] ""  Tester
 SG_ DCU2_OSC_Signal29 : 231|8@0+ (1,0) [0|255] ""  Tester
 SG_ DCU2_OSC_Signal30 : 239|8@0+ (1,0) [0|255] ""  Tester
 SG_ DCU2_OSC_Signal31 : 247|8@0+ (1,0) [0|255] ""  Tester
 SG_ DCU2_OSC_Signal32 : 255|8@0+ (1,0) [0|255] ""  Tester
 SG_ DCU2_OSC_Signal33 : 263|8@0+ (1,0) [0|255] ""  Tester
 SG_ DCU2_OSC_Signal34 : 271|8@0+ (1,0) [0|255] ""  Tester
 SG_ DCU2_OSC_Signal35 : 279|8@0+ (1,0) [0|255] ""  Tester
 SG_ DCU2_OSC_Signal36 : 287|8@0+ (1,0) [0|255] ""  Tester
 SG_ DCU2_OSC_Signal37 : 295|8@0+ (1,0) [0|255] ""  Tester
 SG_ DCU2_OSC_Signal38 : 303|8@0+ (1,0) [0|255] ""  Tester
 SG_ DCU2_OSC_Signal39 : 311|8@0+ (1,0) [0|255] ""  Tester
 SG_ DCU2_OSC_Signal40 : 319|8@0+ (1,0) [0|255] ""  Tester
 SG_ DCU2_OSC_Signal41 : 327|8@0+ (1,0) [0|255] ""  Tester
 SG_ DCU2_OSC_Signal42 : 335|8@0+ (1,0) [0|255] ""  Tester
 SG_ DCU2_OSC_Signal43 : 343|8@0+ (1,0) [0|255] ""  Tester
 SG_ DCU2_OSC_Signal44 : 351|8@0+ (1,0) [0|255] ""  Tester
 SG_ DCU2_OSC_Signal45 : 359|8@0+ (1,0) [0|255] ""  Tester
 SG_ DCU2_OSC_Signal46 : 367|8@0+ (1,0) [0|255] ""  Tester
 SG_ DCU2_OSC_Signal47 : 375|8@0+ (1,0) [0|255] ""  Tester
 SG_ DCU2_OSC_Signal48 : 383|8@0+ (1,0) [0|255] ""  Tester
 SG_ DCU2_OSC_Signal49 : 391|8@0+ (1,0) [0|255] ""  Tester
 SG_ DCU2_OSC_Signal50 : 399|8@0+ (1,0) [0|255] ""  Tester
 SG_ DCU2_OSC_Signal51 : 407|8@0+ (1,0) [0|255] ""  Tester
 SG_ DCU2_OSC_Signal52 : 415|8@0+ (1,0) [0|255] ""  Tester
 SG_ DCU2_OSC_Signal53 : 423|8@0+ (1,0) [0|255] ""  Tester
 SG_ DCU2_OSC_Signal54 : 431|8@0+ (1,0) [0|255] ""  Tester
 SG_ DCU2_OSC_Signal55 : 439|8@0+ (1,0) [0|255] ""  Tester
 SG_ DCU2_OSC_Signal56 : 447|8@0+ (1,0) [0|255] ""  Tester
 SG_ DCU2_OSC_Signal57 : 455|8@0+ (1,0) [0|255] ""  Tester
 SG_ DCU2_OSC_Signal58 : 463|8@0+ (1,0) [0|255] ""  Tester
 SG_ DCU2_OSC_Signal59 : 471|8@0+ (1,0) [0|255] ""  Tester
 SG_ DCU2_OSC_Signal60 : 479|8@0+ (1,0) [0|255] ""  Tester
 SG_ DCU2_OSC_Signal61 : 487|8@0+ (1,0) [0|255] ""  Tester
 SG_ DCU2_OSC_Signal62 : 495|8@0+ (1,0) [0|255] ""  Tester
 SG_ DCU2_OSC_Signal63 : 503|8@0+ (1,0) [0|255] ""  Tester
 SG_ DCU2_OSC_Signal64 : 511|8@0+ (1,0) [0|255] ""  Tester

BO_ 2683305999 DCU2_DEBUG_6: 32 MCU
 SG_ DCU2_Debug_IdcEst : 59|15@0+ (0.1,-1500) [-1500|1776.7] "A"  Tester
 SG_ DCU2_Debug_TorqEstByPower : 42|15@0+ (0.1,-1500) [-1500|1776.7] "Nm"  Tester
 SG_ DCU2_Debug_TorqEstByTable : 25|15@0+ (0.1,-1500) [-1500|1776.7] "Nm"  Tester
 SG_ DCU2_Debug_Iq : 8|15@0+ (0.1,-1500) [-1500|1776.7] "A"  Tester
 SG_ DCU2_Debug_Id : 7|15@0+ (0.1,-1500) [-1500|1776.7] "A"  Tester

BO_ 2683306017 Err_OSCManage: 8 Tester
 SG_ Err_Read : 7|1@0+ (1,0) [0|1] ""  DCU2,MCU
 SG_ Err_Clear : 6|1@0+ (1,0) [0|0] ""  DCU2,MCU

BO_ 2634022913 XCP_Frame_Tx: 8 MCU
 SG_ XCP_Data_Tx : 7|64@0+ (1,0) [0|0] ""  Tester

BO_ 2634022912 XCP_Frame_Rx: 8 Tester
 SG_ XCP_Data_Rx : 7|64@0+ (1,0) [0|0] ""  DCU2,MCU

BO_ 2683306093 IPS_Debug_3: 64 MCU
 SG_ IPS_Debug : 7|64@0+ (1,0) [0|0] ""  Tester

BO_ 2683306000 IPS_Debug_1: 64 Tester
 SG_ IPS_Password : 7|8@0+ (1,0) [0|255] "-"  IPS,MCU
 SG_ IPS_TEL_DCDCFaultLampInd2 : 8|1@0+ (1,0) [0|1] "-"  IPS,MCU
 SG_ IPS_TEL_DCDCTempOvrErr2 : 9|1@0+ (1,0) [0|1] "-"  IPS,MCU
 SG_ IPS_Disable_CC : 12|3@0+ (1,0) [0|7] ""  IPS,MCU
 SG_ IPS_Disable_CP : 15|3@0+ (1,0) [0|7] "-"  IPS,MCU
 SG_ IPS_Disable_RCChecksum : 16|1@0+ (1,0) [0|1] "-"  IPS,MCU
 SG_ IPS_DCDCSet : 17|1@0+ (1,0) [0|1] "-"  IPS,MCU
 SG_ IPS_OBCSet : 18|1@0+ (1,0) [0|1] ""  IPS,MCU
 SG_ IPS_OBCHvVoltLimSet : 19|1@0+ (1,0) [0|1] ""  IPS,MCU
 SG_ IPS_Disable_DCDCSelfChck : 20|1@0+ (1,0) [0|1] ""  IPS,MCU
 SG_ IPS_DCDCLvVoltSet : 31|10@0+ (0.1,0) [0|102.3] "V"  IPS,MCU
 SG_ IPS_OBCChgVoltReqManCal : 37|10@0+ (1,0) [0|1023] "V"  IPS,MCU
 SG_ IPS_OBCChgCurrReqManCal : 43|10@0+ (0.1,0) [0|102.3] "A"  IPS,MCU
 SG_ IPS_OBCDchgDcCurrLim : 49|10@0+ (0.1,0) [0|102.3] "A"  IPS,MCU

BO_ 2683306012 IPS_Debug_2: 64 MCU
 SG_ IPS_DcdcVersion : 279|8@0+ (1,0) [0|255] ""  Tester
 SG_ IPS_LlcVersion : 271|8@0+ (1,0) [0|255] ""  Tester
 SG_ IPS_PfcVersion : 263|8@0+ (1,0) [0|255] ""  Tester
 SG_ IPS_ocm_AswVersion : 255|8@0+ (1,0) [0|255] ""  Tester
 SG_ IPS_DiagDtcSetSt : 8|1@0+ (1,0) [0|1] ""  Tester
 SG_ IPS_DiagClrErr : 9|1@0+ (1,0) [0|1] ""  Tester
 SG_ IPS_pwrObcChgCap : 7|14@0+ (0.01,0) [0|163.83] "KW"  Tester
 SG_ IPS_PfcPwrModeSt : 27|4@0+ (1,0) [0|15] ""  Tester
 SG_ IPS_tPfcTemp : 23|12@0+ (0.1,-50) [-50|359.5] "degC"  Tester
 SG_ IPS_LLcPwrModeSt : 43|4@0+ (1,0) [0|15] ""  Tester
 SG_ IPS_fCpFrq : 39|12@0+ (1,0) [0|4095] "Hz"  Tester
 SG_ IPS_DcdcPwrModeSt : 61|4@0+ (1,0) [0|15] ""  Tester
 SG_ IPS_reAcIsoRes : 55|10@0+ (1,0) [0|1023] "KOhm"  Tester
 SG_ IPS_smd_uDcdcLvVoltSet : 71|10@0+ (0.1,0) [0|102.3] "V"  Tester
 SG_ IPS_fmd_DcdcFaultStopEn : 92|1@0+ (1,0) [0|1] ""  Tester
 SG_ IPS_fmo_ObcFaultStopEn : 93|1@0+ (1,0) [0|1] ""  Tester
 SG_ IPS_smo_dDchgCpDucyc : 87|10@0+ (0.1,0) [0|100] "%"  Tester
 SG_ IPS_smo_IsoTestEn : 101|3@0+ (1,0) [0|7] ""  Tester
 SG_ IPS_fmd_FsDcdcPwrOffEn : 102|1@0+ (1,0) [0|1] ""  Tester
 SG_ IPS_smd_FsDcdcOvpSelfChckSt : 103|1@0+ (1,0) [0|1] ""  Tester
 SG_ IPS_smo_iObcDcCurrLim : 117|4@0+ (1,0) [0|15] ""  Tester
 SG_ IPS_smo_ObcModeSet : 111|10@0+ (0.1,0) [0|102.3] "A"  Tester
 SG_ IPS_smo_uObcDcVoltSet : 113|10@0+ (1,0) [0|1023] "V"  Tester
 SG_ IPS_RelaySts : 139|4@0+ (1,0) [0|15] ""  Tester
 SG_ IPS_DcdcRadTemp : 135|12@0+ (0.1,-50) [-50|359.5] "degC"  Tester
 SG_ IPS_PfcVbulk : 151|14@0+ (0.1,0) [0|1638.3] "V"  Tester
 SG_ IPS_iObcHvCurr : 153|10@0+ (0.1,0) [0|102.3] "A"  Tester
 SG_ IPS_fmo_ObcFaultReset : 171|1@0+ (1,0) [0|1] ""  Tester
 SG_ IPS_fmd_DcdcFaultReset : 172|1@0+ (1,0) [0|1] ""  Tester
 SG_ IPS_smo_Cp9vTiOut : 173|1@0+ (1,0) [0|1] ""  Tester
 SG_ IPS_smo_Cp12vTiOut : 174|1@0+ (1,0) [0|1] ""  Tester
 SG_ IPS_spd_NmReq : 91|4@0+ (1,0) [0|15] ""  Tester
 SG_ IPS_smd_iDcdcLvCurrLim : 170|9@0+ (1,0) [0|511] "A"  Tester
 SG_ IPS_spo_iObcCcCpAcCurrLim : 177|10@0+ (0.1,0) [0|102.3] "A"  Tester
 SG_ IPS_DcdcSRSts : 215|4@0+ (1,0) [0|15] ""  Tester
 SG_ IPS_LlcWorkFreq : 211|12@0+ (0.1,0) [0|409.5] ""  Tester
 SG_ IPS_DcdcBuckDuty : 231|10@0+ (0.1,0) [0|100] "%"  Tester
 SG_ IPS_uFsDcdcLvVolt : 237|10@0+ (0.1,0) [0|102.3] "V"  Tester

CM_ SG_ 2015 Fun_Diag_Request "Diagnostic function request";
CM_ SG_ 1179 DCU2_DTCCode15 "DTC code";
CM_ SG_ 1179 DCU2_DTCCode14 "DTC code";
CM_ SG_ 1179 DCU2_DTCCode13 "DTC code";
CM_ SG_ 1179 DCU2_DTCCode12 "DTC code";
CM_ SG_ 1179 DCU2_DTCCode11 "DTC code";
CM_ SG_ 1179 DCU2_DTCCode10 "DTC code";
CM_ SG_ 1179 DCU2_DTCCode9 "DTC code";
CM_ SG_ 1179 DCU2_DTCCode8 "DTC code";
CM_ SG_ 1179 DCU2_DTCCode7 "DTC code";
CM_ SG_ 1179 DCU2_DTCCode6 "DTC code";
CM_ SG_ 1179 DCU2_DTCCode5 "DTC code";
CM_ SG_ 1179 DCU2_DTCCode4 "DTC code";
CM_ SG_ 1179 DCU2_DTCCode3 "DTC code";
CM_ SG_ 1179 DCU2_DTCCode2 "DTC code";
CM_ SG_ 1179 DCU2_DTCCode1 "DTC code";
CM_ SG_ 1179 DCU2_DTCCode0 "DTC code";
CM_ SG_ 1185 IPS_DigEvent "IPS DTC Sent To CCU";
CM_ SG_ 378 BMS_1_CRC "E2E Profile 5 CRC";
CM_ SG_ 378 BMS_1_Counter "E2E Profile 5 Counter";
CM_ SG_ 378 BMS_BattCurr "actual current of battery";
CM_ SG_ 378 BMS_BattVolt "Sample value of pack voltage ( BR )";
CM_ SG_ 378 BMS_BusVolt "Sample value of HV_BUS voltage( CG )";
CM_ SG_ 378 BMS_PwrDwnReq "Emergency power-off warning. when the HV battery needs an emergency power-off, this signal is used to notify each HV node. The received node should reduce their power  to 0  as soon as possible.";
CM_ SG_ 378 BMS_DCUBattSt "working state of battery system for DCU";
CM_ SG_ 729 EDL_DiffLockModSt_R "Rear differential lock mode state";
CM_ SG_ 1377 BMS_NMNodeAddress "BMS node address";
CM_ SG_ 1377 BMS_NMCBV "BMS Network management control bit vector";
CM_ SG_ 1377 BMS_NMWakeupOrigin "Origin of the wake up";
CM_ SG_ 1377 BMS_PNCInformation0 "PNC Information";
CM_ SG_ 1377 BMS_PNCInformation1 "PNC Information";
CM_ SG_ 1377 BMS_PNCInformation2 "PNC Information";
CM_ SG_ 410 GCU_IdcAct "actual HV current at generator";
CM_ SG_ 369 DCU2_1_CRC "E2E Profile 5 CRC";
CM_ SG_ 369 DCU2_1_Counter "E2E Profile 5 Counter";
CM_ SG_ 369 DCU2_RotSpdAct "actual rotation speed of drvie motor";
CM_ SG_ 369 DCU2_IdcAct "actual current at HV of DCU";
CM_ SG_ 369 DCU2_UdcAct "actual voltage at HV of DCU";
CM_ SG_ 369 DCU2_CCUEOPPowerSup "DCU request CCU give EOP power supply";
CM_ SG_ 369 DCU2_TorqMax "maximum positive Torque allowed (motor)";
CM_ SG_ 369 DCU2_HvilSt "DCU send HVIL status by itself";
CM_ SG_ 369 DCU2_TorqMin "maximum negative torque allowed (generator)";
CM_ SG_ 369 DCU2_SelfTorqMax "Actual value of maximum positive Torque without Idc max limit";
CM_ SG_ 369 DCU2_SelfTorqMin "Actual value maximum negative torque? without Idc mini limit";
CM_ SG_ 369 DCU2_DstActive "Surge Damping state active";
CM_ SG_ 369 DCU2_GateDrvSt "state of gate driver";
CM_ SG_ 369 DCU2_DiagErrCode "DCU diagnostics error code";
CM_ SG_ 369 DCU2_EOP_SpdSet "requestable oil pump speed";
CM_ SG_ 369 DCU2_ModeSt_Hyb "mode status of drive motor";
CM_ SG_ 369 DCU2_TorqAct "actual torque of drive motor";
CM_ SG_ 369 DCU2_ADC_MCUBlkst "DCU2 block state";
CM_ SG_ 369 DCU2_ADC_SpdSvModAvl "DCU2 speed mode available state";
CM_ SG_ 369 DCU2_ADC_MCUStandstill "DCU2 standstill state";
CM_ SG_ 369 DCU2_ADC_MCUSpdSVModFit "DCU2 speed mode fault";
CM_ SG_ 369 DCU2_ADC_MCUVehSldSt "DCU2 detect vehicle slide state";
CM_ SG_ 369 DCU2_ADC_MCUReqTq "DCU2 innner request torque";
CM_ SG_ 369 DCU2_Iq "Actual current of axis q";
CM_ SG_ 369 DCU2_Id "Actual current of axis d";
CM_ SG_ 369 DCU2_TrqWoDstC "Torque without damping control (in Nm)";
CM_ SG_ 369 DCU2_stTrqEmLim "actual state of derating regarding torque";
CM_ SG_ 369 DCU2_KL15St "DCU2 KL15 Enable state";
CM_ SG_ 866 DCU2_2_CRC "E2E Profile 5 CRC";
CM_ SG_ 866 DCU2_2_Counter "E2E Profile 5 Counter";
CM_ SG_ 866 DCU2_OffsetCalInd "indication of óffset calibration successfull flag";
CM_ SG_ 866 DCU2_InvtTemp "Current temperature of inverter";
CM_ SG_ 866 DCU2_VoltageT30 "Current UT30 Voltage at inverter";
CM_ SG_ 866 DCU2_SysTempOvrInd "Indicator of overheat warning lamp, which is lighten if temperature of drive motor system is too high.";
CM_ SG_ 866 DCU2_RotTemp "Current temperature of rotor";
CM_ SG_ 866 DCU2_CooltReq "Requested DCU coolant massflow";
CM_ SG_ 866 DCU2_FaultLampInd "Warning indicator to lighten fault lamp (Malfunction Indication Lamp,MIL)";
CM_ SG_ 866 DCU2_StatTemp "Current temperature of stator";
CM_ SG_ 866 DCU2_ErrNotice "DCU2 error notice";
CM_ SG_ 866 DCU2_ETCS "IPU ETCS function active state";
CM_ SG_ 866 DCU2_TEL_MotorNumOrder "The order number of motors in the vehicle (this value cannot be larger than the total number)";
CM_ SG_ 866 DCU2_TEL_ECUTempOvrErr "The  temperature  of ECU is too high";
CM_ SG_ 866 DCU2_TEL_MotTempOvrErr "The  temperature  of Motor is too high";
CM_ SG_ 866 DCU2_TEL_MotorNumTotal "The total number of motors in the vehicle";
CM_ SG_ 866 DCU2_TEL_InvtTemp "Current temperature of inverter";
CM_ SG_ 866 DCU2_TEL_RotSpdAct "actual rotation speed of drvie motor";
CM_ SG_ 866 DCU2_TEL_TorqAct "actual torque of drive motor";
CM_ SG_ 866 DCU2_TEL_StatTemp "Current temperature of stator";
CM_ SG_ 866 DCU2_TEL_ModeSt "Mode state for TEL ONLY";
CM_ SG_ 866 DCU2_TEL_CurrActAmend "actual current at HV of DCU（by amend）";
CM_ SG_ 866 DCU2_TEL_UdcAct "actual voltage at HV of DCU";
CM_ SG_ 866 DCU2_TEL_BattCurr "actual current of battery(BMS_BattCurr)";
CM_ SG_ 866 DCU2_Fault1 "ERAD fault information1";
CM_ SG_ 866 DCU2_Fault2 "ERAD fault information2";
CM_ SG_ 866 DCU2_Fault3 "ERAD fault information3";
CM_ SG_ 866 DCU2_Fault4 "ERAD fault information4";
CM_ SG_ 866 DCU2_OffsetCalVal "offset angle";
CM_ SG_ 866 DCU2_EngMilLampReq "DCU2 request engine MIL lamp on";
CM_ SG_ 866 DCU2_ZeroTorqCompensateSt "Driving motor zero-torque compensation state";
CM_ SG_ 1275 DCU2_Data1No "DCU2 Data 1 Number 1";
CM_ SG_ 1275 DCU2_Hwversion "Hardware version of Inverter";
CM_ SG_ 1275 DCU2_Swversion "Software1 version of Inverter";
CM_ SG_ 1275 DCU2_SwVerExt "Software2 version of Inverter";
CM_ SG_ 1275 DCU2_OffsetAngle "Resover Offset";
CM_ SG_ 1275 DCU2_BootSV "BOOT  Version";
CM_ SG_ 1275 DCU2_BSWVersion "Basic software Version";
CM_ SG_ 1275 DCU2_InvtPhaUTemp "Current temperature of inverter Phase U";
CM_ SG_ 1275 DCU2_InvtPhaVTemp "Current temperature of inverter Phase V";
CM_ SG_ 1275 DCU2_InvtPhaWTemp "Current temperature of inverter Phase W";
CM_ SG_ 1275 DCU2_Stat1Temp "Current temperature of Stator 1";
CM_ SG_ 1275 DCU2_Stat2Temp "Current temperature of Stator 2";
CM_ SG_ 1275 DCU2_CtrlBoardTemp "Current temperature of Control Board";
CM_ SG_ 1275 DCU2_DrvBoardTemp "Current temperature of Drive Board";
CM_ SG_ 1275 DCU2_CapTemp "Current temperature of Capacitor";
CM_ SG_ 1275 DCU2_FusastSafePathReq "SafePathReq of LV2";
CM_ SG_ 1275 DCU2_FusaModeSt "ModeSt of LV2";
CM_ SG_ 1275 DCU2_FusaQDisChargeReq "QDisChargeReq of LV2";
CM_ SG_ 1275 DCU2_FusastPWMEna "PWMEna of LV2";
CM_ SG_ 1275 DCU2_FusaErrCode "ErrCode of LV2";
CM_ SG_ 1275 DCU2_FusaRotSpdAct "RotSpdAct of LV2";
CM_ SG_ 1275 DCU2_FusaTorqAct "TorqAct of LV2";
CM_ SG_ 1275 DCU2_FusaFaultInfo7 "FaultInfo7 of LV2";
CM_ SG_ 1275 DCU2_FusaFaultInfo8 "FaultInfo8 of LV2";
CM_ SG_ 1275 DCU2_FaultData_RC "Fault Data";
CM_ SG_ 1275 DCU2_stHandleOff "Fault Handle";
CM_ SG_ 1275 DCU2_stPWMEna "PWM Enable Status ";
CM_ SG_ 1275 DCU2_stMode "Mode status of inverter";
CM_ SG_ 1275 DCU2_FailCode "Failcode";
CM_ SG_ 1275 DCU2_stASCProt "Active short curcurt ";
CM_ SG_ 1275 DCU2_agRotorPosn "Rotor position of motor";
CM_ SG_ 1275 DCU2_PWMFreq "PWM  frequency";
CM_ SG_ 1275 DCU2_uDcVolt "actual voltage of inveter";
CM_ SG_ 1275 DCU2_uLowVolt "low voltage";
CM_ SG_ 1275 DCU2_iCurdFinalRef "Target current of axis q";
CM_ SG_ 1275 DCU2_iCurqFinalRef "Target current of axis q";
CM_ SG_ 1275 DCU2_iCurdFb "Actual current of axis d";
CM_ SG_ 1275 DCU2_iCurqFb "Actual current of axis q";
CM_ SG_ 1275 DCU2_iPhaCurU "Phase U  Actual current of Motor";
CM_ SG_ 1275 DCU2_iPhaCurV "Phase V  Actual current of Motor";
CM_ SG_ 1275 DCU2_iPhaCurW "Phase W  Actual current of Motor";
CM_ SG_ 1275 DCU2_uVoltdFinalRef "Axis D  Actual Voltage of Motor";
CM_ SG_ 1275 DCU2_uVoltqFinalRef "Axis Q Actual Voltage of Motor";
CM_ SG_ 1275 DCU2_iDcCur "dc current";
CM_ SG_ 1275 DCU2_ResFaultFlag "reset Flag";
CM_ SG_ 1275 DCU2_OperatingCycle "operating cycle";
CM_ SG_ 1275 DCU2_Year "year";
CM_ SG_ 1275 DCU2_Month "month";
CM_ SG_ 1275 DCU2_Day "day";
CM_ SG_ 1275 DCU2_Hour "hour";
CM_ SG_ 1275 DCU2_Minute "miniute";
CM_ SG_ 1275 DCU2_Second "second";
CM_ SG_ 1275 DCU2_FaultData_1Bit_1 "1bit fault data1";
CM_ SG_ 1275 DCU2_FaultData_1Bit_2 "1bit fault data2";
CM_ SG_ 1275 DCU2_FaultData_1Bit_3 "1bit fault data3";
CM_ SG_ 1275 DCU2_FaultData_1Bit_4 "1bit fault data4";
CM_ SG_ 1275 DCU2_FaultData_4Bit_1 "4bit fault data";
CM_ SG_ 1275 DCU2_FaultData_12Bit_1 "12bit fault data";
CM_ SG_ 1275 DCU2_FaultData_16Bit_1 "16bit fault data";
CM_ SG_ 1275 DCU2_stIGBTFault "Status of IGBT";
CM_ SG_ 1275 DCU2_stBigDataTrigger "Status of BigDataTrigger";
CM_ SG_ 1275 DCU2_FaultData_4Bit_2 "4bit fault data2";
CM_ SG_ 1275 DCU2_FaultData_4Bit_3 "4bit fault data3";
CM_ SG_ 1275 DCU2_FaultData_8Bit_1 "8bit fault data1";
CM_ SG_ 1275 DCU2_FaultData_8Bit_2 "8bit fault data2";
CM_ SG_ 1275 DCU2_FaultData_8Bit_3 "8bit fault data3";
CM_ SG_ 1275 DCU2_FaultData_8Bit_4 "8bit fault data4";
CM_ SG_ 1275 DCU2_FaultData_12Bit_2 "12bit fault data2";
CM_ SG_ 1275 DCU2_FaultData_12Bit_3 "12bit fault data3";
CM_ SG_ 1275 DCU2_FaultData_16Bit_2 "16bit fault data2";
CM_ SG_ 1275 DCU2_FaultData_20Bit_1 "20bit fault data1";
CM_ SG_ 1275 DCU2_stSBCFault "Status of SBC";
CM_ SG_ 384 EOP_1_CRC "E2E Profile 5 CRC";
CM_ SG_ 384 EOP_1_Counter "E2E Profile 5 Counter";
CM_ SG_ 384 EOP_IdcAct "oil pump DC current";
CM_ SG_ 384 EOP_IphAct "oil pump phase current";
CM_ SG_ 384 EOP_UdcAct "actual voltage of oil pump";
CM_ SG_ 384 EOP_SpdAct "Actual speed of oil pump";
CM_ SG_ 384 EOP_Status "EOP Status";
CM_ SG_ 384 EOP_duty "duty cycle of oil pump";
CM_ SG_ 384 EOP_ErrLevel "to inform DCU that the error level of the EOP";
CM_ SG_ 384 EOP_RemoteDiagCode "The flag that ECU need to be remote diagnosed";
CM_ SG_ 704 IPS_DCDCHVPwr "DCDC high-voltage power";
CM_ SG_ 704 IPS_1_CRC "E2E Profile 5 CRC";
CM_ SG_ 704 IPS_1_Counter "E2E Profile 5 Counter";
CM_ SG_ 704 IPS_DCDCDiagErrCode "DCDC diagnostics error code";
CM_ SG_ 704 IPS_DCDCModeSt "mode status of DCDC";
CM_ SG_ 704 IPS_KL15State "IPS or DCDC Enable state";
CM_ SG_ 704 IPS_DCDCVoltLvAct "actual LV voltage at DCDC";
CM_ SG_ 704 IPS_DCDCCurrHvAct "HV Current? of DCDC";
CM_ SG_ 704 IPS_DCDCCurrLvAct "LV Current? of DCDC";
CM_ SG_ 704 IPS_DCDCVoltHvAct "actual HV voltage at DCDC";
CM_ SG_ 704 IPS_OBCDiagErrCode "OBC diagnostics error code";
CM_ SG_ 704 IPS_OBCCC_St "Status of slow charging cable connection (CC) including type of connected cable (charging/V2V, or V2L)";
CM_ SG_ 704 IPS_OBCCC_Res "CC Resistance value in Ohm";
CM_ SG_ 704 IPS_DchgOverload "Discharge Overload";
CM_ SG_ 704 IPS_OBCDschDisable "Status of control pilot signal (CP) for discharging";
CM_ SG_ 704 IPS_OBCModeSt "OBC mode state";
CM_ SG_ 704 IPS_OBCHvDcCurrAct "OBC HVDC actual current (Positive current+：Charging mode output current from IPS to HVBAT, Negative current-: DisCharging mode input current from HVBAT)";
CM_ SG_ 704 IPS_OBCHvDcVoltAct "OBC HVDC voltage";
CM_ SG_ 704 IPS_OBCCC_Cap "AC charging capability of the charging cable detected by OBC";
CM_ SG_ 704 IPS_OBCCpS2St "S2 swtich state";
CM_ SG_ 704 IPS_OBCCpFreqSt "CP frequency is in the GB range";
CM_ SG_ 704 IPS_OBCCPSt "Status of control pilot signal (CP) for charging";
CM_ SG_ 704 IPS_OBCCp_DutyCycle "CP Duty";
CM_ SG_ 704 IPS_OBCCPVolt "CP high level";
CM_ SG_ 704 IPS_OBCV2CSt "OBC V2C mode status";
CM_ SG_ 704 IPS_V2CMicSwitSt "Micro switch state of V2C";
CM_ SG_ 704 IPS_smo_ObcModeSt "OBC basic StateMation";
CM_ SG_ 704 IPS_smd_DcdcModeSt "DCDC basic StateMation";
CM_ SG_ 704 IPS_WakeOriginSignal1 "Wake up OriginSignal1";
CM_ SG_ 704 IPS_WakeOriginSignal2 "Wake up OriginSignal2";
CM_ SG_ 704 IPS_OBCCurrActL1 "L1 phase current";
CM_ SG_ 704 IPS_OBCCurrActL2 "L2 phase current";
CM_ SG_ 704 IPS_OBCCurrActL3 "L3 phase current";
CM_ SG_ 704 IPS_DCDCKL30VoltForHyb "IPS or DCDC LV power supply voltage";
CM_ SG_ 704 IPS_DCDCHVilSt "DCDC send DC side HVIL status measued by itself";
CM_ SG_ 704 IPS_OBC_DCVolt "OBC sample value of DC charging pile voltage( DG ) ";
CM_ SG_ 704 IPS_OBCUacActL1 "L1 phase voltage";
CM_ SG_ 704 IPS_OBCUacActL2 "L2 phase voltage";
CM_ SG_ 704 IPS_OBCUacActL3 "L3 phase voltage";
CM_ SG_ 704 IPS_HVDCHVilStForHyb "IPS send DC side HVIL status measued by itself";
CM_ SG_ 704 IPS_ACHvilStForHyb "IPS send AC side HVIL status measued by itself";
CM_ SG_ 704 IPS_OBCStStep "OBC Charging or V2V orV2L state Step";
CM_ SG_ 872 IPS_2_CRC "E2E Profile 5 CRC";
CM_ SG_ 872 IPS_2_Counter "E2E Profile 5 Counter";
CM_ SG_ 872 IPS_SwVersion "software version of DCDC, according to GAC Definition (see Diagnostic Tables)";
CM_ SG_ 872 IPS_HwSt "tell it is that IPS or DCDC(because they are same ID)";
CM_ SG_ 872 IPS_RemoteDiagCode "The flag that ECU need to be remote diagnosed";
CM_ SG_ 872 IPS_TEL_DCDCFaultLampInd "Warning indicator to lighten fault lamp (Malfunction Indication Lamp, MIL), FOR TEL";
CM_ SG_ 872 IPS_TEL_DCDCTempOvrErr "over temperature, DCDC not able to work, FOR TEL";
CM_ SG_ 872 IPS_TEL_DCDCModeSt "mode status of DCDC for TEL";
CM_ SG_ 872 IPS_TempAct "OBC internal temperature";
CM_ SG_ 872 IPS_DCDCFlowReq "The DCDC required coolant flow speed? (L/min)";
CM_ SG_ 872 IPS_ChgWakeDisableFlg "AC charge wakeup disable flag";
CM_ SG_ 872 IPS_OBCChgPwrMax "Available OBC charging power depending on provided current and voltage from charging station, limitations from cable OBC efficiency and OBC derating.";
CM_ SG_ 872 IPS_OBCFlowReq "The OBC required coolant flow speed? (L/min)";
CM_ SG_ 872 IPS_DCDCState1 "DCDC state information 1";
CM_ SG_ 872 IPS_DCDCState2 "DCDC state information 2";
CM_ SG_ 872 IPS_DCDCState3 "DCDC state information 3";
CM_ SG_ 872 IPS_DCDCState4 "DCDC state information 4";
CM_ SG_ 872 IPS_DCDCState5 "DCDC state information 5";
CM_ SG_ 872 IPS_OBCState6 "OBC state information 6";
CM_ SG_ 872 IPS_OBCState7 "OBC state information 7";
CM_ SG_ 872 IPS_OBCState8 "OBC state information 8";
CM_ SG_ 872 IPS_OBCState9 "OBC state information 9";
CM_ SG_ 872 IPS_OBCState1 "OBC state information 1";
CM_ SG_ 872 IPS_OBCState2 "OBC state information 2";
CM_ SG_ 872 IPS_OBCState3 "OBC state information 3";
CM_ SG_ 872 IPS_OBCState4 "OBC state information 4";
CM_ SG_ 872 IPS_OBCState5 "OBC state information 5";
CM_ SG_ 872 IPS_DCDCTempAct "Actual temperature of DCDC";
CM_ SG_ 872 IPS_ChgCurResp "Charge current response of IPS for display";
CM_ SG_ 872 IPS_ChgCurRespAvail "To indicate if Charge current of HV IPS is available";
CM_ SG_ 872 IPS_DCDCState6 "DCDC state information 6";
CM_ SG_ 872 IPS_DCDCFaultLampIndOperationFla "Operation flag for IPS_DCDCFaultLampInd";
CM_ SG_ 872 IPS_DCDCFaultLampIndFlag "Popup?flag?for??DCDC?error?notice";
CM_ SG_ 872 IPS_OBCFaultLampIndOperationFlag "Operation flag for  IPS_OBCFaultLampInd";
CM_ SG_ 872 IPS_OBCState10 "OBC state information 10";
CM_ SG_ 872 IPS_OBCState11 "OBC state information 11";
CM_ SG_ 872 IPS_DCDCState7 "DCDC state information 7";
CM_ SG_ 872 IPS_DCDCState8 "DCDC state information 8";
CM_ SG_ 872 IPS_DCDCState9 "DCDC state information 9";
CM_ SG_ 872 IPS_DCDCState10 "DCDC state information 10";
CM_ SG_ 872 IPS_OBCAclso_Res "Ac Line Iso Resistance Value";
CM_ SG_ 872 IPS_OBCState12 "OBC state information 12";
CM_ SG_ 872 IPS_OBCState13 "OBC state information 13";
CM_ SG_ 872 IPS_OBCState14 "OBC state information 14";
CM_ SG_ 872 IPS_DCDCState11 "DCDC state information 11";
CM_ SG_ 872 IPS_DCDCState12 "DCDC state information 12";
CM_ SG_ 872 IPS_DCDCState13 "DCDC state information 13";
CM_ SG_ 872 IPS_OBCV2CCurr "OBC V2C  current";
CM_ SG_ 872 IPS_OBCV2CRlySt "Actual state of OBC V2C relay";
CM_ SG_ 872 IPS_OBCV2LRlySt "Actual state of OBC V2L relay";
CM_ SG_ 872 IPS_OBCDsgPortPwrCons "V2V, V2L discharge port constant power max (CC，IPS discharging max power)";
CM_ SG_ 872 IPS_OBCEngMilLampReq "OBC  request engine MIL lamp on";
CM_ SG_ 872 IPS_OBCDispDiagInfo "OBC diagnostics Information for display";
CM_ SG_ 1790 NIDU_UDS_Diag_Response "NIDU diagnostic response For UDS";
CM_ SG_ 1662 NIDU_UDS_Diag_Request "NIDU diagnostic request For UDS";
CM_ SG_ 2028 NIDU_OBD_Diag_Response "NIDU diagnostic response For OBD";
CM_ SG_ 2020 NIDU_OBD_Diag_Request "NIDU diagnostic request For OBD";
CM_ SG_ 1406 NIDU_NMNodeAddress "NIDU node address";
CM_ SG_ 1406 NIDU_NMCBV "NIDU Network management control bit vector";
CM_ SG_ 1406 NIDU_NMWakeupOrigin "Origin of the wake up";
CM_ SG_ 1406 NIDU_PNCInformation0 "PNC Information";
CM_ SG_ 1406 NIDU_PNCInformation1 "PNC Information";
CM_ SG_ 1406 NIDU_PNCInformation2 "PNC Information";
CM_ SG_ 607 EVCC_OBCCC_Res "CC Resistance state";
CM_ SG_ 607 EVCC_FaultState "EVCC fault state";
CM_ SG_ 607 EVCC_ChgStd "Charging pile standard";
CM_ SG_ 418 VCU_MotTqRateLimMin "电机轴端扭矩变化率下限";
CM_ SG_ 418 VCU_TqUnloadEna "请求卸扭使能";
CM_ SG_ 418 VCU_MotTqRateLimMax "电机轴端扭矩变化率上限";
CM_ SG_ 417 VCU_13_CRC "E2E Profile 5 CRC";
CM_ SG_ 417 VCU_13_Counter "E2E Profile 5 Counter";
CM_ SG_ 417 VCU_DCU2_IdcMax "max current for drive torque";
CM_ SG_ 417 VCU_DCU2_IdcMin "max current for regenerative torque";
CM_ SG_ 417 VCU_DCU2_TorqAllwd "Indication if drive motor is allowed to apply propulsive orregenerative torque on wheels";
CM_ SG_ 417 VCU_DCU2_UdcMin "min voltage at HV";
CM_ SG_ 417 VCU_DCU2_UdcMax "max voltage at HV";
CM_ SG_ 417 VCU_DCU2_ModeReq "requestable state/mode of drive motor";
CM_ SG_ 417 VCU_DCU2_SpdSet "target speed for drive motor, only with openclutch";
CM_ SG_ 417 VCU_DCU2_DampGain "Dynamic factor used to convert vibrations due to speed into equivalent damping";
CM_ SG_ 417 VCU_DCU2_ZeroTorqCompensateReq "request for Driving motor zero-torque compensation";
CM_ SG_ 417 VCU_DCU2_DampReq "request of damping for DCU2";
CM_ SG_ 417 VCU_DCU2_MaxTorqGradient "Maximum change rate of the torque demand";
CM_ SG_ 417 VCU_DCU2_TorqMin "max limit of negative torque for drive motor";
CM_ SG_ 417 VCU_DCU2_TorqMax "max limit of positive torque for drive motor";
CM_ SG_ 417 VCU_DCU2_SpdLmt "Speed limit for drive motor";
CM_ SG_ 417 VCU_DCU2_MaxTorqDampgCtl "Maximum limit for damping torque that shall be applied (in Nm).";
CM_ SG_ 417 VCU_DCU2_TorqSet_Hyb "target torque for hybrid drive motor";
CM_ SG_ 417 VCU_ReTqUnloadEna "请求卸扭使能";
CM_ SG_ 417 VCU_ReMotTqRateLimMax "电机轴端扭矩变化率上限";
CM_ SG_ 417 VCU_ReMotTqRateLimMin "电机轴端扭矩变化率下限";
CM_ SG_ 557 VCU_3_CRC "E2E Profile 5 CRC";
CM_ SG_ 557 VCU_3_Counter "E2E Profile 5 Counter";
CM_ SG_ 557 VCU_IPS_OBCModeReq "OBC mode request (0: no request, sleep indication allowed)";
CM_ SG_ 557 VCU_IPS_OBCDsChDCCurrLim "max allowed (limit) discharging current on DC side of OBC";
CM_ SG_ 920 VCU_4_CRC "E2E Profile 5 CRC";
CM_ SG_ 920 VCU_4_Counter "E2E Profile 5 Counter";
CM_ SG_ 920 VCU_IPS_DCDCModeReq "requestable target mode for DCDC";
CM_ SG_ 920 VCU_IPS_DCDCLvCurrLim "Limitation of DCDC LV output current. Current is positive, if energy flow is from IPS into the LV system(reserved).";
CM_ SG_ 920 VCU_SRSCrashOutputSt "To inform there's crash event happen in last 2sec.After 2 sec, the signal will turn to 0";
CM_ SG_ 920 VCU_IPS_DCDCVoltLvSet "requestable target output DC voltage at LV of DCDC";
CM_ SG_ 920 VCU_IPS_DCDCVoltLvModeSt "Main requestable target output DC voltage at LV of DCDC";
CM_ SG_ 920 VCU_DCDCVoltLvModeSt "Sub requestable target output DC voltage at LV of DCDC";
CM_ SG_ 920 VCU_DCDCVoltLvSet "Sub requestable target output DC voltage at LV ofDCDC";
CM_ SG_ 920 VCU_OBCCPJumpCounter "VCU check OBC CP jumping times counter";
CM_ SG_ 920 VCU_OBCCPWarning "OBC CP signal check error warning";
CM_ SG_ 998 VCU_5_CRC "E2E Profile 5 CRC";
CM_ SG_ 998 VCU_5_Counter "E2E Profile 5 Counter";
CM_ SG_ 998 VCU_IPS_OBCChgVoltReq "Required AC charge valtage from IPS_OBC";
CM_ SG_ 998 VCU_IPS_OBCChgCurrReq "Required AC charge current  from IPS_OBC";
CM_ SG_ 1034 VCU_6_CRC "E2E Profile 5 CRC";
CM_ SG_ 1034 VCU_6_Counter "E2E Profile 5 Counter";
CM_ SG_ 1034 VCU_SubEngWarmUPCycle "VCU replace engine warm up cycle";
CM_ SG_ 1034 VCU_VehAltitude "Vehicle altitude";
CM_ SG_ 1034 VCU_VehIdleRunningTime "Vehicle idle running time";
CM_ SG_ 1034 VCU_VehRunningTime "Vehilce drive system running time";
CM_ SG_ 1034 VCU_DriveCycleSt "Vehicle drive cycle status";
CM_ SG_ 1034 VCU_VehStopTime "Vehicle drive system stop time";
CM_ SG_ 860 VCU_VehRdySt "HEV system ready status";
CM_ SG_ 860 VCU_PlgConnSt "Charge connector  connected Status";
CM_ SG_ 516 VCU_9_CRC "E2E Profile 5 CRC";
CM_ SG_ 516 VCU_9_Counter "E2E Profile 5 Counter";
CM_ SG_ 516 VCU_CrntGearLvl "VCU current carry out gear level";
CM_ SG_ 516 VCU_BrkPedPstVD "Current brake pedal position valid data";
CM_ SG_ 516 VCU_BrkPedPst "Current brake pedal position";
CM_ SG_ 516 VCU_EMS_AccPedalActPst "Current accelerate pedal actual position";
CM_ SG_ 516 VCU_EMS_AccPedalActPstVD "Current accelerate pedal actual position validity";
CM_ SG_ 516 VCU_HTMSMTCoolantTemp "HTMS water pump outlet coolant temperature";
CM_ SG_ 516 VCU_HTMSMTCoolantTempVD "HTMS water pump outlet coolant temperature VD";
CM_ SG_ 616 CCU_1_CRC "E2E Profile 5 CRC";
CM_ SG_ 616 CCU_1_Counter "E2E Profile 5 Counter";
CM_ SG_ 616 UMM_UsageModeSt "Usage mode state";
CM_ SG_ 616 VMM_VehModeSt "Vehicle mode state";
CM_ SG_ 616 VMM_LastVehModeSt "Last time vehicle mode";
CM_ SG_ 616 VMM_OTAModeSt "OTA Mode state";
CM_ SG_ 616 IPDS_DysWakeupPowerSup "Dynamical System Wake up Power Supply";
CM_ SG_ 616 IPDS_EnablePowerSup "Enable power supply";
CM_ SG_ 616 Time_Year "Year number";
CM_ SG_ 616 Time_Month "Month number";
CM_ SG_ 616 Time_Day "Day number";
CM_ SG_ 616 Time_Hour "Hour number";
CM_ SG_ 616 Time_Min "Minute number";
CM_ SG_ 616 Time_Sec "Second number";
CM_ SG_ 816 HVAC_CorrectedExterTemp "Corrected External temperature";
CM_ SG_ 816 HVAC_CorrectedExterTempVD "External temperature valid data";
CM_ SG_ 816 HVAC_PTCHeatingReq "PTC Heating Duty request";
CM_ SG_ 816 HVAC_PTCSt "HVAC's PTC OFF or dowmshift status";
CM_ SG_ 816 HVAC_ECPPwrConsump "ECP power consumption";
CM_ SG_ 816 HVAC_PTCOnReq "Enables operation of HV-PTC";
CM_ SG_ 960 TMS_4_CRC "E2E Profile 5 CRC";
CM_ SG_ 960 TMS_4_Counter "E2E Profile 5 Counter";
CM_ SG_ 960 TMS_WtrPmp1DutyReq " WaterPump1 duty request";
CM_ SG_ 960 TMS_WtrPmp1PerdReq " WaterPump1 period request";
CM_ SG_ 960 TMS_MotRadrOutCooltT " Motor inlet water temperature";
CM_ SG_ 960 TMS_MotRadrOutCooltTVld " Motor inlet water temperature valid flag";
CM_ SG_ 960 TMS_WtrPmp1Fault " WaterPump1 fault";
CM_ SG_ 960 TMS_MotRadrInCooltTFault "EGR inlet coolant temperature sensor Fault Status ";
CM_ SG_ 960 TMS_MotRadrInCooltT "EGR inlet water temperature";
CM_ SG_ 290 IPDS_RearEOPPowerSup "Rear EOP power supply";
CM_ SG_ 290 IPDS_KL15T1PowerSup "KL15 T1 power supply";
CM_ SG_ 1359 CCU_NMNodeAddress "CCU node address";
CM_ SG_ 1359 CCU_NMCBV "CCU Network management control bit vector";
CM_ SG_ 1359 CCU_NMWakeupOrigin "Origin of the wake up";
CM_ SG_ 1359 CCU_PNCInformation0 "PNC Information";
CM_ SG_ 1359 CCU_PNCInformation1 "PNC Information";
CM_ SG_ 1359 CCU_PNCInformation2 "PNC Information";
CM_ SG_ 352 BCS_2_CRC "E2E Profile 5 CRC";
CM_ SG_ 352 BCS_2_Counter "E2E Profile 5 Counter";
CM_ SG_ 352 BCS_VehSpd "Vehicle speed";
CM_ SG_ 352 BCS_VehSpdVD "Quality/fault information to vehicle speed";
CM_ SG_ 352 BCS_EBDActiveSt "Indication that EBD system currently performs a brake/engine intervention";
CM_ SG_ 352 BCS_EBDFaultSt "ABS system has detected a heavy fault, which does not even allow a reliable electronic brake distribution and is therefore completely shut down";
CM_ SG_ 352 BCS_ABSActiveSt "Indication that ABS system currently performs a brake intervention";
CM_ SG_ 352 BCS_ABSFaultSt "ABS system has detected a failure which does no allow a reliable ABS regulation and is therefore switched off";
CM_ SG_ 352 BCS_TCSActiveSt "Indication that TCS system currently performs a brake/engine intervention";
CM_ SG_ 352 BCS_TCSFaultSt "TCS is switched off due to detected failure";
CM_ SG_ 352 BCS_VDCActiveSt "Indication that VDC system currently performs a brake/engine intervention when ESP adjust the posture of vehicle ";
CM_ SG_ 352 BCS_VDCFaultSt "VDC is switched off due to detected failure";
CM_ SG_ 352 BCS_RegenModulationAvailable "Indicate whether ESP can follow ePedal request and modify the recuperation torque";
CM_ SG_ 352 BCS_RegenModuleActive "Reduce repcuperation torque requested by oppotize TCS control active status";
CM_ SG_ 352 BCS_DMCTarSpdFA "Engine rotational target speed for TCS-DMCIt is calculated continuously, but used only in the case of an vehicle acceleXAtion request. The signal is modified by ESPdepending on the driving situation and the opeXAtion mode. The signal is sent as an absolute value irrespective offorward or reverse driving direction. For reverse driving, necessary transformations must be done in PE.";
CM_ SG_ 352 BCS_DMCCtrModeFA "Control mode for TCS-DMCSignal contains the release state of the TCS function for the vehicle, e.g. initialization/release/degeradation.";
CM_ SG_ 352 BCS_DMCVariant "ESP variant info, mainly used for handshake check";
CM_ SG_ 352 BCS_DMCTarSpdRA "Engine rotational target speed for TCS-DMCIt is calculated continuously, but used only in the case of an vehicle acceleXAtion request. The signal is modified by ESP for rear Axle or   left rear wheel hub motor";
CM_ SG_ 352 BCS_DMCCtrModeRA "Control mode for TCS-DMCSignal contains the release state of the TCS function for the vehicle for Rear  Axlefor rear Axle or  left rear wheel hub motor";
CM_ SG_ 352 BCS_EngTorqDecActiveStRA "Decrease enginetorque  active status (fast and low) for Rear Axle";
CM_ SG_ 398 EMS_EngSpd "Engine Speed";
CM_ SG_ 398 EMS_EngSpdVD "EMS_EngSpd validity";
CM_ SG_ 398 EMS_EngIdleRefSpd "Engine Idle reference speed";
CM_ SG_ 398 EMS_OBDDrivingCycleStForPDTC "Diagnosis,DrivingCycle status after OBD $04 clear the PDTC";
CM_ SG_ 398 EMS_OBDWarmUpCycleSt "Diagnosis";
CM_ SG_ 398 EMS_AbsoluteThrottlepst "Absolute throttle position";
CM_ SG_ 398 EMS_EngWaterTemp "Engine Water Temperature";
CM_ SG_ 398 EMS_EngWaterTempVD "EMS_EngWaterTemp validity";
CM_ SG_ 398 EMS_EngCalculatedLoad "Diagnosis,Engine load Calculated by EMS";
CM_ SG_ 445 EMS_IUPRGenInh "indicates the general denominator related pending fault state";
CM_ SG_ 445 EMS_IURPGenDen "indicates the update permission state of general denominator";
CM_ SG_ 445 EMS_IUPRIgCnt "indicates the update permission state of IG counter";
CM_ SG_ 407 EMS_EngRunningTime "The time of engine running";
CM_ SG_ 905 ICM_TotalOdometer "Total odometer";
CM_ SG_ 161 ACU_ACChgCurCfg "ACCharge current setting  to IPS";
CM_ SG_ 909 WtrPmp1DutyFb " WaterPump1 duty feedback";
CM_ SG_ 909 IPDS_RearMotorPowerSt "Rear motor power state";
CM_ SG_ 909 IPDS_RearEOPPowerSt "Rear EOP power state";
CM_ SG_ 909 IPDS_RearMotorPowerFaultSt "Rear motor power Fault state";
CM_ SG_ 909 IPDS_RearEOPPowerFaultSt "Rear EOP power Fault state";
CM_ SG_ 909 IPDS_KL15T1PowerSt "KL15 T1 power state";
CM_ SG_ 2683305995 DCU2_TempCoolant "temperature of inverter cooling water";
CM_ SG_ 2683305995 DCU2_DataFaultHandle "Status of Resover";
BA_DEF_ BO_  "GenMsgCycleTime" INT 0 0;
BA_DEF_ BO_  "GenMsgCycleTimeFast" INT 0 0;
BA_DEF_ BO_  "GenMsgSendType" ENUM  "Periodic","Event","IfActive","POE","PA","FixedPeriodic","Event","EnabledPeriodic","NotUsed","NotUsed","EventPeriodic","NotUsed","NotUsed","NoMsgSendType";
BA_DEF_ BO_  "VFrameFormat" ENUM  "StandardCAN","ExtendedCAN","reserved","reserved","reserved","reserved","reserved","reserved","reserved","reserved","reserved","reserved","reserved","reserved","StandardCAN_FD","ExtendedCAN_FD";
BA_DEF_ BO_  "CANFD_BRS" ENUM  "0","1";
BA_DEF_ SG_  "EventCommandSignal" ENUM  "No","Yes";
BA_DEF_ SG_  "GatewayedSignals" ENUM  "No","Yes";
BA_DEF_ SG_  "GenSigInactiveValue" HEX 0 0;
BA_DEF_ SG_  "GenSigInvalidValue" HEX 0 0;
BA_DEF_ SG_  "GenSigSendType" ENUM  "Trigger","Passive","Cyclic","OnWrite","OnWriteWithRepetition","OnChange","OnChangeWithRepetition","IfActive","IfActiveWithRepetition","NoSigSendType";
BA_DEF_ SG_  "GenSigStartValue" HEX 0 0;
BA_DEF_ SG_  "GenSigTimeoutValue" HEX 0 0;
BA_DEF_ SG_  "Remark" STRING ;
BA_DEF_  "Manufacturer" STRING ;
BA_DEF_  "Project" STRING ;
BA_DEF_  "Version" STRING ;
BA_DEF_  "Date" STRING ;
BA_DEF_  "Author" STRING ;
BA_DEF_  "DBName" STRING ;
BA_DEF_  "BusType" STRING ;
BA_DEF_  "Checker" STRING ;
BA_DEF_  "Approver" STRING ;
BA_DEF_ SG_  "SystemSignalLongSymbol" STRING ;
BA_DEF_DEF_  "GenMsgCycleTime" 0;
BA_DEF_DEF_  "GenMsgCycleTimeFast" 0;
BA_DEF_DEF_  "GenMsgSendType" "";
BA_DEF_DEF_  "VFrameFormat" "";
BA_DEF_DEF_  "CANFD_BRS" "";
BA_DEF_DEF_  "EventCommandSignal" "";
BA_DEF_DEF_  "GatewayedSignals" "";
BA_DEF_DEF_  "GenSigInactiveValue" 0;
BA_DEF_DEF_  "GenSigInvalidValue" 0;
BA_DEF_DEF_  "GenSigSendType" "";
BA_DEF_DEF_  "GenSigStartValue" 0;
BA_DEF_DEF_  "GenSigTimeoutValue" 0;
BA_DEF_DEF_  "Remark" "";
BA_DEF_DEF_  "Manufacturer" "";
BA_DEF_DEF_  "Project" "";
BA_DEF_DEF_  "Version" "";
BA_DEF_DEF_  "Date" "";
BA_DEF_DEF_  "Author" "";
BA_DEF_DEF_  "DBName" "";
BA_DEF_DEF_  "BusType" "";
BA_DEF_DEF_  "Checker" "";
BA_DEF_DEF_  "Approver" "";
BA_DEF_DEF_  "SystemSignalLongSymbol" "";
BA_ "Manufacturer" "GACRND";
BA_ "Project" "A88";
BA_ "Version" "0.1";
BA_ "Date" "2025/1/21 15:54:02";
BA_ "Author" "LeoFeng";
BA_ "BusType" "CAN FD";
BA_ "Checker" "Miss Fan";
BA_ "Approver" "Mr Hu";
BA_ "DBName" "NIDUCCU_CANFD2";
BA_ "GenMsgSendType" BO_ 2015 1;
BA_ "CANFD_BRS" BO_ 2015 1;
BA_ "VFrameFormat" BO_ 2015 14;
BA_ "GenMsgSendType" BO_ 1179 1;
BA_ "CANFD_BRS" BO_ 1179 1;
BA_ "VFrameFormat" BO_ 1179 14;
BA_ "GenMsgSendType" BO_ 1185 1;
BA_ "CANFD_BRS" BO_ 1185 1;
BA_ "VFrameFormat" BO_ 1185 14;
BA_ "GenMsgCycleTime" BO_ 378 10;
BA_ "GenMsgSendType" BO_ 378 0;
BA_ "CANFD_BRS" BO_ 378 1;
BA_ "VFrameFormat" BO_ 378 14;
BA_ "GenMsgCycleTime" BO_ 729 20;
BA_ "GenMsgSendType" BO_ 729 0;
BA_ "CANFD_BRS" BO_ 729 1;
BA_ "VFrameFormat" BO_ 729 14;
BA_ "GenMsgCycleTime" BO_ 1377 200;
BA_ "GenMsgSendType" BO_ 1377 0;
BA_ "VFrameFormat" BO_ 1377 0;
BA_ "CANFD_BRS" BO_ 1377 1;
BA_ "GenMsgCycleTime" BO_ 410 10;
BA_ "GenMsgSendType" BO_ 410 0;
BA_ "CANFD_BRS" BO_ 410 1;
BA_ "VFrameFormat" BO_ 410 14;
BA_ "GenMsgCycleTime" BO_ 369 10;
BA_ "GenMsgSendType" BO_ 369 0;
BA_ "CANFD_BRS" BO_ 369 1;
BA_ "VFrameFormat" BO_ 369 14;
BA_ "GenMsgCycleTime" BO_ 866 100;
BA_ "GenMsgSendType" BO_ 866 0;
BA_ "CANFD_BRS" BO_ 866 1;
BA_ "VFrameFormat" BO_ 866 14;
BA_ "GenMsgCycleTime" BO_ 1275 1000;
BA_ "GenMsgCycleTimeFast" BO_ 1275 40;
BA_ "GenMsgSendType" BO_ 1275 4;
BA_ "CANFD_BRS" BO_ 1275 1;
BA_ "VFrameFormat" BO_ 1275 14;
BA_ "GenMsgCycleTime" BO_ 384 100;
BA_ "GenMsgSendType" BO_ 384 0;
BA_ "CANFD_BRS" BO_ 384 1;
BA_ "VFrameFormat" BO_ 384 14;
BA_ "GenMsgCycleTime" BO_ 704 20;
BA_ "GenMsgSendType" BO_ 704 0;
BA_ "CANFD_BRS" BO_ 704 1;
BA_ "VFrameFormat" BO_ 704 14;
BA_ "GenMsgCycleTime" BO_ 872 100;
BA_ "GenMsgSendType" BO_ 872 0;
BA_ "CANFD_BRS" BO_ 872 1;
BA_ "VFrameFormat" BO_ 872 14;
BA_ "GenMsgSendType" BO_ 1790 1;
BA_ "CANFD_BRS" BO_ 1790 1;
BA_ "VFrameFormat" BO_ 1790 14;
BA_ "GenMsgSendType" BO_ 1662 1;
BA_ "CANFD_BRS" BO_ 1662 1;
BA_ "VFrameFormat" BO_ 1662 14;
BA_ "GenMsgSendType" BO_ 2028 1;
BA_ "CANFD_BRS" BO_ 2028 1;
BA_ "VFrameFormat" BO_ 2028 14;
BA_ "GenMsgSendType" BO_ 2020 1;
BA_ "CANFD_BRS" BO_ 2020 1;
BA_ "VFrameFormat" BO_ 2020 14;
BA_ "GenMsgCycleTime" BO_ 1406 200;
BA_ "GenMsgSendType" BO_ 1406 0;
BA_ "VFrameFormat" BO_ 1406 0;
BA_ "CANFD_BRS" BO_ 1406 1;
BA_ "GenMsgCycleTime" BO_ 607 20;
BA_ "GenMsgSendType" BO_ 607 0;
BA_ "CANFD_BRS" BO_ 607 1;
BA_ "VFrameFormat" BO_ 607 14;
BA_ "GenMsgCycleTime" BO_ 418 10;
BA_ "GenMsgSendType" BO_ 418 0;
BA_ "CANFD_BRS" BO_ 418 1;
BA_ "VFrameFormat" BO_ 418 14;
BA_ "GenMsgCycleTime" BO_ 417 10;
BA_ "GenMsgSendType" BO_ 417 0;
BA_ "CANFD_BRS" BO_ 417 1;
BA_ "VFrameFormat" BO_ 417 14;
BA_ "GenMsgCycleTime" BO_ 557 20;
BA_ "GenMsgSendType" BO_ 557 0;
BA_ "CANFD_BRS" BO_ 557 1;
BA_ "VFrameFormat" BO_ 557 14;
BA_ "GenMsgCycleTime" BO_ 920 100;
BA_ "GenMsgSendType" BO_ 920 0;
BA_ "CANFD_BRS" BO_ 920 1;
BA_ "VFrameFormat" BO_ 920 14;
BA_ "GenMsgCycleTime" BO_ 998 200;
BA_ "GenMsgSendType" BO_ 998 0;
BA_ "CANFD_BRS" BO_ 998 1;
BA_ "VFrameFormat" BO_ 998 14;
BA_ "GenMsgCycleTime" BO_ 1034 500;
BA_ "GenMsgSendType" BO_ 1034 0;
BA_ "CANFD_BRS" BO_ 1034 1;
BA_ "VFrameFormat" BO_ 1034 14;
BA_ "GenMsgCycleTime" BO_ 860 100;
BA_ "GenMsgSendType" BO_ 860 0;
BA_ "CANFD_BRS" BO_ 860 1;
BA_ "VFrameFormat" BO_ 860 14;
BA_ "GenMsgCycleTime" BO_ 516 20;
BA_ "GenMsgSendType" BO_ 516 0;
BA_ "CANFD_BRS" BO_ 516 1;
BA_ "VFrameFormat" BO_ 516 14;
BA_ "GenMsgCycleTime" BO_ 616 20;
BA_ "GenMsgSendType" BO_ 616 0;
BA_ "CANFD_BRS" BO_ 616 1;
BA_ "VFrameFormat" BO_ 616 14;
BA_ "GenMsgCycleTime" BO_ 816 100;
BA_ "GenMsgSendType" BO_ 816 0;
BA_ "CANFD_BRS" BO_ 816 1;
BA_ "VFrameFormat" BO_ 816 14;
BA_ "GenMsgCycleTime" BO_ 960 400;
BA_ "GenMsgSendType" BO_ 960 0;
BA_ "CANFD_BRS" BO_ 960 1;
BA_ "VFrameFormat" BO_ 960 14;
BA_ "GenMsgCycleTime" BO_ 290 500;
BA_ "GenMsgCycleTimeFast" BO_ 290 40;
BA_ "GenMsgSendType" BO_ 290 3;
BA_ "CANFD_BRS" BO_ 290 1;
BA_ "VFrameFormat" BO_ 290 14;
BA_ "GenMsgCycleTime" BO_ 1359 200;
BA_ "GenMsgSendType" BO_ 1359 0;
BA_ "VFrameFormat" BO_ 1359 0;
BA_ "CANFD_BRS" BO_ 1359 1;
BA_ "GenMsgCycleTime" BO_ 352 10;
BA_ "GenMsgSendType" BO_ 352 0;
BA_ "CANFD_BRS" BO_ 352 1;
BA_ "VFrameFormat" BO_ 352 14;
BA_ "GenMsgCycleTime" BO_ 398 100;
BA_ "GenMsgSendType" BO_ 398 0;
BA_ "CANFD_BRS" BO_ 398 1;
BA_ "VFrameFormat" BO_ 398 14;
BA_ "GenMsgCycleTime" BO_ 445 100;
BA_ "GenMsgSendType" BO_ 445 0;
BA_ "CANFD_BRS" BO_ 445 1;
BA_ "VFrameFormat" BO_ 445 14;
BA_ "GenMsgCycleTime" BO_ 407 100;
BA_ "GenMsgSendType" BO_ 407 0;
BA_ "CANFD_BRS" BO_ 407 1;
BA_ "VFrameFormat" BO_ 407 14;
BA_ "GenMsgCycleTime" BO_ 905 100;
BA_ "GenMsgSendType" BO_ 905 0;
BA_ "CANFD_BRS" BO_ 905 1;
BA_ "VFrameFormat" BO_ 905 14;
BA_ "GenMsgSendType" BO_ 161 1;
BA_ "CANFD_BRS" BO_ 161 1;
BA_ "VFrameFormat" BO_ 161 14;
BA_ "GenMsgCycleTime" BO_ 909 100;
BA_ "GenMsgSendType" BO_ 909 0;
BA_ "CANFD_BRS" BO_ 909 1;
BA_ "VFrameFormat" BO_ 909 14;
BA_ "GenMsgCycleTime" BO_ 2683306021 1000;
BA_ "GenMsgSendType" BO_ 2683306021 0;
BA_ "CANFD_BRS" BO_ 2683306021 1;
BA_ "VFrameFormat" BO_ 2683306021 15;
BA_ "GenMsgCycleTime" BO_ 2683306010 100;
BA_ "GenMsgSendType" BO_ 2683306010 0;
BA_ "CANFD_BRS" BO_ 2683306010 1;
BA_ "VFrameFormat" BO_ 2683306010 15;
BA_ "GenMsgCycleTime" BO_ 2683305995 10;
BA_ "GenMsgSendType" BO_ 2683305995 0;
BA_ "CANFD_BRS" BO_ 2683305995 1;
BA_ "VFrameFormat" BO_ 2683305995 15;
BA_ "GenMsgCycleTime" BO_ 2683305992 10;
BA_ "GenMsgSendType" BO_ 2683305992 0;
BA_ "CANFD_BRS" BO_ 2683305992 1;
BA_ "VFrameFormat" BO_ 2683305992 15;
BA_ "GenMsgCycleTime" BO_ 2683305998 10;
BA_ "GenMsgSendType" BO_ 2683305998 0;
BA_ "CANFD_BRS" BO_ 2683305998 1;
BA_ "VFrameFormat" BO_ 2683305998 15;
BA_ "GenMsgCycleTime" BO_ 2683305999 10;
BA_ "GenMsgSendType" BO_ 2683305999 0;
BA_ "CANFD_BRS" BO_ 2683305999 1;
BA_ "VFrameFormat" BO_ 2683305999 15;
BA_ "GenMsgCycleTime" BO_ 2683306017 100;
BA_ "GenMsgSendType" BO_ 2683306017 0;
BA_ "CANFD_BRS" BO_ 2683306017 1;
BA_ "VFrameFormat" BO_ 2683306017 15;
BA_ "GenMsgSendType" BO_ 2634022913 1;
BA_ "VFrameFormat" BO_ 2634022913 1;
BA_ "GenMsgSendType" BO_ 2634022912 1;
BA_ "VFrameFormat" BO_ 2634022912 1;
BA_ "GenMsgCycleTime" BO_ 2683306093 1000;
BA_ "GenMsgSendType" BO_ 2683306093 0;
BA_ "CANFD_BRS" BO_ 2683306093 1;
BA_ "VFrameFormat" BO_ 2683306093 15;
BA_ "GenMsgCycleTime" BO_ 2683306000 200;
BA_ "GenMsgSendType" BO_ 2683306000 0;
BA_ "CANFD_BRS" BO_ 2683306000 1;
BA_ "VFrameFormat" BO_ 2683306000 15;
BA_ "GenMsgCycleTime" BO_ 2683306012 200;
BA_ "GenMsgSendType" BO_ 2683306012 0;
BA_ "CANFD_BRS" BO_ 2683306012 1;
BA_ "VFrameFormat" BO_ 2683306012 15;
BA_ "EventCommandSignal" SG_ 2015 Fun_Diag_Request 0;
BA_ "GatewayedSignals" SG_ 2015 Fun_Diag_Request 0;
BA_ "GenSigSendType" SG_ 2015 Fun_Diag_Request 1;
BA_ "EventCommandSignal" SG_ 1179 DCU2_DTCCode15 1;
BA_ "GatewayedSignals" SG_ 1179 DCU2_DTCCode15 0;
BA_ "GenSigSendType" SG_ 1179 DCU2_DTCCode15 0;
BA_ "EventCommandSignal" SG_ 1179 DCU2_DTCCode14 1;
BA_ "GatewayedSignals" SG_ 1179 DCU2_DTCCode14 0;
BA_ "GenSigSendType" SG_ 1179 DCU2_DTCCode14 0;
BA_ "EventCommandSignal" SG_ 1179 DCU2_DTCCode13 1;
BA_ "GatewayedSignals" SG_ 1179 DCU2_DTCCode13 0;
BA_ "GenSigSendType" SG_ 1179 DCU2_DTCCode13 0;
BA_ "EventCommandSignal" SG_ 1179 DCU2_DTCCode12 1;
BA_ "GatewayedSignals" SG_ 1179 DCU2_DTCCode12 0;
BA_ "GenSigSendType" SG_ 1179 DCU2_DTCCode12 0;
BA_ "EventCommandSignal" SG_ 1179 DCU2_DTCCode11 1;
BA_ "GatewayedSignals" SG_ 1179 DCU2_DTCCode11 0;
BA_ "GenSigSendType" SG_ 1179 DCU2_DTCCode11 0;
BA_ "EventCommandSignal" SG_ 1179 DCU2_DTCCode10 1;
BA_ "GatewayedSignals" SG_ 1179 DCU2_DTCCode10 0;
BA_ "GenSigSendType" SG_ 1179 DCU2_DTCCode10 0;
BA_ "EventCommandSignal" SG_ 1179 DCU2_DTCCode9 1;
BA_ "GatewayedSignals" SG_ 1179 DCU2_DTCCode9 0;
BA_ "GenSigSendType" SG_ 1179 DCU2_DTCCode9 0;
BA_ "EventCommandSignal" SG_ 1179 DCU2_DTCCode8 1;
BA_ "GatewayedSignals" SG_ 1179 DCU2_DTCCode8 0;
BA_ "GenSigSendType" SG_ 1179 DCU2_DTCCode8 0;
BA_ "EventCommandSignal" SG_ 1179 DCU2_DTCCode7 1;
BA_ "GatewayedSignals" SG_ 1179 DCU2_DTCCode7 0;
BA_ "GenSigSendType" SG_ 1179 DCU2_DTCCode7 0;
BA_ "EventCommandSignal" SG_ 1179 DCU2_DTCCode6 1;
BA_ "GatewayedSignals" SG_ 1179 DCU2_DTCCode6 0;
BA_ "GenSigSendType" SG_ 1179 DCU2_DTCCode6 0;
BA_ "EventCommandSignal" SG_ 1179 DCU2_DTCCode5 1;
BA_ "GatewayedSignals" SG_ 1179 DCU2_DTCCode5 0;
BA_ "GenSigSendType" SG_ 1179 DCU2_DTCCode5 0;
BA_ "EventCommandSignal" SG_ 1179 DCU2_DTCCode4 1;
BA_ "GatewayedSignals" SG_ 1179 DCU2_DTCCode4 0;
BA_ "GenSigSendType" SG_ 1179 DCU2_DTCCode4 0;
BA_ "EventCommandSignal" SG_ 1179 DCU2_DTCCode3 1;
BA_ "GatewayedSignals" SG_ 1179 DCU2_DTCCode3 0;
BA_ "GenSigSendType" SG_ 1179 DCU2_DTCCode3 0;
BA_ "EventCommandSignal" SG_ 1179 DCU2_DTCCode2 1;
BA_ "GatewayedSignals" SG_ 1179 DCU2_DTCCode2 0;
BA_ "GenSigSendType" SG_ 1179 DCU2_DTCCode2 0;
BA_ "GenSigSendType" SG_ 1179 DCU2_DTCCode1 0;
BA_ "GatewayedSignals" SG_ 1179 DCU2_DTCCode1 0;
BA_ "EventCommandSignal" SG_ 1179 DCU2_DTCCode1 1;
BA_ "EventCommandSignal" SG_ 1179 DCU2_DTCCode0 1;
BA_ "GatewayedSignals" SG_ 1179 DCU2_DTCCode0 0;
BA_ "GenSigSendType" SG_ 1179 DCU2_DTCCode0 0;
BA_ "EventCommandSignal" SG_ 1185 IPS_DigEvent 1;
BA_ "GatewayedSignals" SG_ 1185 IPS_DigEvent 0;
BA_ "GenSigSendType" SG_ 1185 IPS_DigEvent 0;
BA_ "EventCommandSignal" SG_ 378 BMS_1_CRC 0;
BA_ "GatewayedSignals" SG_ 378 BMS_1_CRC 0;
BA_ "GenSigSendType" SG_ 378 BMS_1_CRC 1;
BA_ "EventCommandSignal" SG_ 378 BMS_1_Counter 0;
BA_ "GatewayedSignals" SG_ 378 BMS_1_Counter 0;
BA_ "GenSigSendType" SG_ 378 BMS_1_Counter 1;
BA_ "EventCommandSignal" SG_ 378 BMS_BattCurr 0;
BA_ "GatewayedSignals" SG_ 378 BMS_BattCurr 0;
BA_ "GenSigSendType" SG_ 378 BMS_BattCurr 1;
BA_ "GenSigStartValue" SG_ 378 BMS_BattCurr 10000;
BA_ "EventCommandSignal" SG_ 378 BMS_BattVolt 0;
BA_ "GatewayedSignals" SG_ 378 BMS_BattVolt 0;
BA_ "GenSigSendType" SG_ 378 BMS_BattVolt 1;
BA_ "EventCommandSignal" SG_ 378 BMS_BusVolt 0;
BA_ "GatewayedSignals" SG_ 378 BMS_BusVolt 0;
BA_ "GenSigSendType" SG_ 378 BMS_BusVolt 1;
BA_ "EventCommandSignal" SG_ 378 BMS_PwrDwnReq 0;
BA_ "GatewayedSignals" SG_ 378 BMS_PwrDwnReq 0;
BA_ "GenSigSendType" SG_ 378 BMS_PwrDwnReq 1;
BA_ "EventCommandSignal" SG_ 378 BMS_DCUBattSt 0;
BA_ "GatewayedSignals" SG_ 378 BMS_DCUBattSt 0;
BA_ "GenSigSendType" SG_ 378 BMS_DCUBattSt 1;
BA_ "EventCommandSignal" SG_ 729 EDL_DiffLockModSt_R 0;
BA_ "GatewayedSignals" SG_ 729 EDL_DiffLockModSt_R 0;
BA_ "GenSigSendType" SG_ 729 EDL_DiffLockModSt_R 1;
BA_ "EventCommandSignal" SG_ 1377 BMS_NMNodeAddress 0;
BA_ "GatewayedSignals" SG_ 1377 BMS_NMNodeAddress 0;
BA_ "GenSigSendType" SG_ 1377 BMS_NMNodeAddress 1;
BA_ "GenSigStartValue" SG_ 1377 BMS_NMNodeAddress 97;
BA_ "EventCommandSignal" SG_ 1377 BMS_NMCBV 0;
BA_ "GatewayedSignals" SG_ 1377 BMS_NMCBV 0;
BA_ "GenSigSendType" SG_ 1377 BMS_NMCBV 1;
BA_ "EventCommandSignal" SG_ 1377 BMS_NMWakeupOrigin 0;
BA_ "GatewayedSignals" SG_ 1377 BMS_NMWakeupOrigin 0;
BA_ "GenSigSendType" SG_ 1377 BMS_NMWakeupOrigin 1;
BA_ "EventCommandSignal" SG_ 1377 BMS_PNCInformation0 0;
BA_ "GatewayedSignals" SG_ 1377 BMS_PNCInformation0 0;
BA_ "GenSigSendType" SG_ 1377 BMS_PNCInformation0 1;
BA_ "EventCommandSignal" SG_ 1377 BMS_PNCInformation1 0;
BA_ "GatewayedSignals" SG_ 1377 BMS_PNCInformation1 0;
BA_ "GenSigSendType" SG_ 1377 BMS_PNCInformation1 1;
BA_ "EventCommandSignal" SG_ 1377 BMS_PNCInformation2 0;
BA_ "GatewayedSignals" SG_ 1377 BMS_PNCInformation2 0;
BA_ "GenSigSendType" SG_ 1377 BMS_PNCInformation2 1;
BA_ "EventCommandSignal" SG_ 410 GCU_IdcAct 0;
BA_ "GatewayedSignals" SG_ 410 GCU_IdcAct 0;
BA_ "GenSigInvalidValue" SG_ 410 GCU_IdcAct 2047;
BA_ "GenSigSendType" SG_ 410 GCU_IdcAct 1;
BA_ "EventCommandSignal" SG_ 369 DCU2_1_CRC 0;
BA_ "GatewayedSignals" SG_ 369 DCU2_1_CRC 0;
BA_ "GenSigSendType" SG_ 369 DCU2_1_CRC 1;
BA_ "EventCommandSignal" SG_ 369 DCU2_1_Counter 0;
BA_ "GatewayedSignals" SG_ 369 DCU2_1_Counter 0;
BA_ "GenSigSendType" SG_ 369 DCU2_1_Counter 1;
BA_ "EventCommandSignal" SG_ 369 DCU2_RotSpdAct 0;
BA_ "GatewayedSignals" SG_ 369 DCU2_RotSpdAct 0;
BA_ "GenSigInvalidValue" SG_ 369 DCU2_RotSpdAct 65535;
BA_ "GenSigSendType" SG_ 369 DCU2_RotSpdAct 1;
BA_ "GenSigStartValue" SG_ 369 DCU2_RotSpdAct 32767;
BA_ "EventCommandSignal" SG_ 369 DCU2_IdcAct 0;
BA_ "GatewayedSignals" SG_ 369 DCU2_IdcAct 0;
BA_ "GenSigInvalidValue" SG_ 369 DCU2_IdcAct 2047;
BA_ "GenSigSendType" SG_ 369 DCU2_IdcAct 1;
BA_ "GenSigStartValue" SG_ 369 DCU2_IdcAct 1023;
BA_ "EventCommandSignal" SG_ 369 DCU2_UdcAct 0;
BA_ "GatewayedSignals" SG_ 369 DCU2_UdcAct 0;
BA_ "GenSigInvalidValue" SG_ 369 DCU2_UdcAct 1023;
BA_ "GenSigSendType" SG_ 369 DCU2_UdcAct 1;
BA_ "EventCommandSignal" SG_ 369 DCU2_CCUEOPPowerSup 0;
BA_ "GatewayedSignals" SG_ 369 DCU2_CCUEOPPowerSup 0;
BA_ "GenSigSendType" SG_ 369 DCU2_CCUEOPPowerSup 1;
BA_ "GenSigStartValue" SG_ 369 DCU2_CCUEOPPowerSup 1;
BA_ "EventCommandSignal" SG_ 369 DCU2_TorqMax 0;
BA_ "GatewayedSignals" SG_ 369 DCU2_TorqMax 0;
BA_ "GenSigInvalidValue" SG_ 369 DCU2_TorqMax 1023;
BA_ "GenSigSendType" SG_ 369 DCU2_TorqMax 1;
BA_ "EventCommandSignal" SG_ 369 DCU2_HvilSt 0;
BA_ "GatewayedSignals" SG_ 369 DCU2_HvilSt 0;
BA_ "GenSigSendType" SG_ 369 DCU2_HvilSt 1;
BA_ "EventCommandSignal" SG_ 369 DCU2_TorqMin 0;
BA_ "GatewayedSignals" SG_ 369 DCU2_TorqMin 0;
BA_ "GenSigSendType" SG_ 369 DCU2_TorqMin 1;
BA_ "GenSigStartValue" SG_ 369 DCU2_TorqMin 1023;
BA_ "EventCommandSignal" SG_ 369 DCU2_SelfTorqMax 0;
BA_ "GatewayedSignals" SG_ 369 DCU2_SelfTorqMax 0;
BA_ "GenSigInvalidValue" SG_ 369 DCU2_SelfTorqMax 1023;
BA_ "GenSigSendType" SG_ 369 DCU2_SelfTorqMax 1;
BA_ "EventCommandSignal" SG_ 369 DCU2_SelfTorqMin 0;
BA_ "GatewayedSignals" SG_ 369 DCU2_SelfTorqMin 0;
BA_ "GenSigSendType" SG_ 369 DCU2_SelfTorqMin 1;
BA_ "GenSigStartValue" SG_ 369 DCU2_SelfTorqMin 1023;
BA_ "EventCommandSignal" SG_ 369 DCU2_DstActive 0;
BA_ "GatewayedSignals" SG_ 369 DCU2_DstActive 0;
BA_ "GenSigSendType" SG_ 369 DCU2_DstActive 1;
BA_ "EventCommandSignal" SG_ 369 DCU2_GateDrvSt 0;
BA_ "GatewayedSignals" SG_ 369 DCU2_GateDrvSt 0;
BA_ "GenSigSendType" SG_ 369 DCU2_GateDrvSt 1;
BA_ "EventCommandSignal" SG_ 369 DCU2_DiagErrCode 0;
BA_ "GatewayedSignals" SG_ 369 DCU2_DiagErrCode 0;
BA_ "GenSigSendType" SG_ 369 DCU2_DiagErrCode 1;
BA_ "EventCommandSignal" SG_ 369 DCU2_EOP_SpdSet 0;
BA_ "GatewayedSignals" SG_ 369 DCU2_EOP_SpdSet 0;
BA_ "GenSigSendType" SG_ 369 DCU2_EOP_SpdSet 1;
BA_ "EventCommandSignal" SG_ 369 DCU2_ModeSt_Hyb 0;
BA_ "GatewayedSignals" SG_ 369 DCU2_ModeSt_Hyb 0;
BA_ "GenSigSendType" SG_ 369 DCU2_ModeSt_Hyb 1;
BA_ "GenSigStartValue" SG_ 369 DCU2_ModeSt_Hyb 1;
BA_ "EventCommandSignal" SG_ 369 DCU2_TorqAct 0;
BA_ "GatewayedSignals" SG_ 369 DCU2_TorqAct 0;
BA_ "GenSigSendType" SG_ 369 DCU2_TorqAct 1;
BA_ "GenSigStartValue" SG_ 369 DCU2_TorqAct 4095;
BA_ "EventCommandSignal" SG_ 369 DCU2_ADC_MCUBlkst 0;
BA_ "GatewayedSignals" SG_ 369 DCU2_ADC_MCUBlkst 0;
BA_ "GenSigInvalidValue" SG_ 369 DCU2_ADC_MCUBlkst 7;
BA_ "GenSigSendType" SG_ 369 DCU2_ADC_MCUBlkst 1;
BA_ "EventCommandSignal" SG_ 369 DCU2_ADC_SpdSvModAvl 0;
BA_ "GatewayedSignals" SG_ 369 DCU2_ADC_SpdSvModAvl 0;
BA_ "GenSigInvalidValue" SG_ 369 DCU2_ADC_SpdSvModAvl 1;
BA_ "GenSigSendType" SG_ 369 DCU2_ADC_SpdSvModAvl 1;
BA_ "EventCommandSignal" SG_ 369 DCU2_ADC_MCUStandstill 0;
BA_ "GatewayedSignals" SG_ 369 DCU2_ADC_MCUStandstill 0;
BA_ "GenSigInvalidValue" SG_ 369 DCU2_ADC_MCUStandstill 1;
BA_ "GenSigSendType" SG_ 369 DCU2_ADC_MCUStandstill 1;
BA_ "EventCommandSignal" SG_ 369 DCU2_ADC_MCUSpdSVModFit 0;
BA_ "GatewayedSignals" SG_ 369 DCU2_ADC_MCUSpdSVModFit 0;
BA_ "GenSigInvalidValue" SG_ 369 DCU2_ADC_MCUSpdSVModFit 7;
BA_ "GenSigSendType" SG_ 369 DCU2_ADC_MCUSpdSVModFit 1;
BA_ "EventCommandSignal" SG_ 369 DCU2_ADC_MCUVehSldSt 0;
BA_ "GatewayedSignals" SG_ 369 DCU2_ADC_MCUVehSldSt 0;
BA_ "GenSigInvalidValue" SG_ 369 DCU2_ADC_MCUVehSldSt 1;
BA_ "GenSigSendType" SG_ 369 DCU2_ADC_MCUVehSldSt 1;
BA_ "EventCommandSignal" SG_ 369 DCU2_ADC_MCUReqTq 0;
BA_ "GatewayedSignals" SG_ 369 DCU2_ADC_MCUReqTq 0;
BA_ "GenSigInvalidValue" SG_ 369 DCU2_ADC_MCUReqTq 2047;
BA_ "GenSigSendType" SG_ 369 DCU2_ADC_MCUReqTq 1;
BA_ "GenSigStartValue" SG_ 369 DCU2_ADC_MCUReqTq 1023;
BA_ "EventCommandSignal" SG_ 369 DCU2_Iq 0;
BA_ "GatewayedSignals" SG_ 369 DCU2_Iq 0;
BA_ "GenSigSendType" SG_ 369 DCU2_Iq 1;
BA_ "EventCommandSignal" SG_ 369 DCU2_Id 0;
BA_ "GatewayedSignals" SG_ 369 DCU2_Id 0;
BA_ "GenSigSendType" SG_ 369 DCU2_Id 1;
BA_ "EventCommandSignal" SG_ 369 DCU2_TrqWoDstC 0;
BA_ "GatewayedSignals" SG_ 369 DCU2_TrqWoDstC 0;
BA_ "GenSigInvalidValue" SG_ 369 DCU2_TrqWoDstC 1023;
BA_ "GenSigSendType" SG_ 369 DCU2_TrqWoDstC 1;
BA_ "EventCommandSignal" SG_ 369 DCU2_stTrqEmLim 0;
BA_ "GatewayedSignals" SG_ 369 DCU2_stTrqEmLim 0;
BA_ "GenSigInvalidValue" SG_ 369 DCU2_stTrqEmLim 2047;
BA_ "GenSigSendType" SG_ 369 DCU2_stTrqEmLim 1;
BA_ "EventCommandSignal" SG_ 369 DCU2_KL15St 0;
BA_ "GatewayedSignals" SG_ 369 DCU2_KL15St 0;
BA_ "GenSigSendType" SG_ 369 DCU2_KL15St 1;
BA_ "EventCommandSignal" SG_ 866 DCU2_2_CRC 0;
BA_ "GatewayedSignals" SG_ 866 DCU2_2_CRC 0;
BA_ "GenSigSendType" SG_ 866 DCU2_2_CRC 1;
BA_ "EventCommandSignal" SG_ 866 DCU2_2_Counter 0;
BA_ "GatewayedSignals" SG_ 866 DCU2_2_Counter 0;
BA_ "GenSigSendType" SG_ 866 DCU2_2_Counter 1;
BA_ "EventCommandSignal" SG_ 866 DCU2_OffsetCalInd 0;
BA_ "GatewayedSignals" SG_ 866 DCU2_OffsetCalInd 0;
BA_ "GenSigSendType" SG_ 866 DCU2_OffsetCalInd 1;
BA_ "EventCommandSignal" SG_ 866 DCU2_InvtTemp 0;
BA_ "GatewayedSignals" SG_ 866 DCU2_InvtTemp 0;
BA_ "GenSigInvalidValue" SG_ 866 DCU2_InvtTemp 255;
BA_ "GenSigSendType" SG_ 866 DCU2_InvtTemp 1;
BA_ "GenSigStartValue" SG_ 866 DCU2_InvtTemp 40;
BA_ "EventCommandSignal" SG_ 866 DCU2_VoltageT30 0;
BA_ "GatewayedSignals" SG_ 866 DCU2_VoltageT30 0;
BA_ "GenSigSendType" SG_ 866 DCU2_VoltageT30 1;
BA_ "EventCommandSignal" SG_ 866 DCU2_SysTempOvrInd 0;
BA_ "GatewayedSignals" SG_ 866 DCU2_SysTempOvrInd 0;
BA_ "GenSigSendType" SG_ 866 DCU2_SysTempOvrInd 1;
BA_ "EventCommandSignal" SG_ 866 DCU2_RotTemp 0;
BA_ "GatewayedSignals" SG_ 866 DCU2_RotTemp 0;
BA_ "GenSigInvalidValue" SG_ 866 DCU2_RotTemp 511;
BA_ "GenSigSendType" SG_ 866 DCU2_RotTemp 1;
BA_ "GenSigStartValue" SG_ 866 DCU2_RotTemp 40;
BA_ "EventCommandSignal" SG_ 866 DCU2_CooltReq 0;
BA_ "GatewayedSignals" SG_ 866 DCU2_CooltReq 0;
BA_ "GenSigSendType" SG_ 866 DCU2_CooltReq 1;
BA_ "EventCommandSignal" SG_ 866 DCU2_FaultLampInd 0;
BA_ "GatewayedSignals" SG_ 866 DCU2_FaultLampInd 0;
BA_ "GenSigSendType" SG_ 866 DCU2_FaultLampInd 1;
BA_ "EventCommandSignal" SG_ 866 DCU2_StatTemp 0;
BA_ "GatewayedSignals" SG_ 866 DCU2_StatTemp 0;
BA_ "GenSigInvalidValue" SG_ 866 DCU2_StatTemp 511;
BA_ "GenSigSendType" SG_ 866 DCU2_StatTemp 1;
BA_ "GenSigStartValue" SG_ 866 DCU2_StatTemp 40;
BA_ "EventCommandSignal" SG_ 866 DCU2_ErrNotice 0;
BA_ "GatewayedSignals" SG_ 866 DCU2_ErrNotice 0;
BA_ "GenSigSendType" SG_ 866 DCU2_ErrNotice 1;
BA_ "EventCommandSignal" SG_ 866 DCU2_ETCS 0;
BA_ "GatewayedSignals" SG_ 866 DCU2_ETCS 0;
BA_ "GenSigSendType" SG_ 866 DCU2_ETCS 1;
BA_ "EventCommandSignal" SG_ 866 DCU2_TEL_MotorNumOrder 0;
BA_ "GatewayedSignals" SG_ 866 DCU2_TEL_MotorNumOrder 0;
BA_ "GenSigSendType" SG_ 866 DCU2_TEL_MotorNumOrder 1;
BA_ "EventCommandSignal" SG_ 866 DCU2_TEL_ECUTempOvrErr 0;
BA_ "GatewayedSignals" SG_ 866 DCU2_TEL_ECUTempOvrErr 0;
BA_ "GenSigSendType" SG_ 866 DCU2_TEL_ECUTempOvrErr 1;
BA_ "EventCommandSignal" SG_ 866 DCU2_TEL_MotTempOvrErr 0;
BA_ "GatewayedSignals" SG_ 866 DCU2_TEL_MotTempOvrErr 0;
BA_ "GenSigSendType" SG_ 866 DCU2_TEL_MotTempOvrErr 1;
BA_ "EventCommandSignal" SG_ 866 DCU2_TEL_MotorNumTotal 0;
BA_ "GatewayedSignals" SG_ 866 DCU2_TEL_MotorNumTotal 0;
BA_ "GenSigSendType" SG_ 866 DCU2_TEL_MotorNumTotal 1;
BA_ "EventCommandSignal" SG_ 866 DCU2_TEL_InvtTemp 0;
BA_ "GatewayedSignals" SG_ 866 DCU2_TEL_InvtTemp 0;
BA_ "GenSigInvalidValue" SG_ 866 DCU2_TEL_InvtTemp 255;
BA_ "GenSigSendType" SG_ 866 DCU2_TEL_InvtTemp 1;
BA_ "GenSigStartValue" SG_ 866 DCU2_TEL_InvtTemp 40;
BA_ "EventCommandSignal" SG_ 866 DCU2_TEL_RotSpdAct 0;
BA_ "GatewayedSignals" SG_ 866 DCU2_TEL_RotSpdAct 0;
BA_ "GenSigInvalidValue" SG_ 866 DCU2_TEL_RotSpdAct 65535;
BA_ "GenSigSendType" SG_ 866 DCU2_TEL_RotSpdAct 1;
BA_ "EventCommandSignal" SG_ 866 DCU2_TEL_TorqAct 0;
BA_ "GatewayedSignals" SG_ 866 DCU2_TEL_TorqAct 0;
BA_ "GenSigInvalidValue" SG_ 866 DCU2_TEL_TorqAct 65535;
BA_ "GenSigSendType" SG_ 866 DCU2_TEL_TorqAct 1;
BA_ "EventCommandSignal" SG_ 866 DCU2_TEL_StatTemp 0;
BA_ "GatewayedSignals" SG_ 866 DCU2_TEL_StatTemp 0;
BA_ "GenSigInvalidValue" SG_ 866 DCU2_TEL_StatTemp 255;
BA_ "GenSigSendType" SG_ 866 DCU2_TEL_StatTemp 1;
BA_ "GenSigStartValue" SG_ 866 DCU2_TEL_StatTemp 40;
BA_ "EventCommandSignal" SG_ 866 DCU2_TEL_ModeSt 0;
BA_ "GatewayedSignals" SG_ 866 DCU2_TEL_ModeSt 0;
BA_ "GenSigSendType" SG_ 866 DCU2_TEL_ModeSt 1;
BA_ "EventCommandSignal" SG_ 866 DCU2_TEL_CurrActAmend 0;
BA_ "GatewayedSignals" SG_ 866 DCU2_TEL_CurrActAmend 0;
BA_ "GenSigSendType" SG_ 866 DCU2_TEL_CurrActAmend 1;
BA_ "EventCommandSignal" SG_ 866 DCU2_TEL_UdcAct 0;
BA_ "GatewayedSignals" SG_ 866 DCU2_TEL_UdcAct 0;
BA_ "GenSigSendType" SG_ 866 DCU2_TEL_UdcAct 1;
BA_ "EventCommandSignal" SG_ 866 DCU2_TEL_BattCurr 0;
BA_ "GatewayedSignals" SG_ 866 DCU2_TEL_BattCurr 0;
BA_ "GenSigSendType" SG_ 866 DCU2_TEL_BattCurr 1;
BA_ "EventCommandSignal" SG_ 866 DCU2_Fault1 0;
BA_ "GatewayedSignals" SG_ 866 DCU2_Fault1 0;
BA_ "GenSigSendType" SG_ 866 DCU2_Fault1 1;
BA_ "EventCommandSignal" SG_ 866 DCU2_Fault2 0;
BA_ "GatewayedSignals" SG_ 866 DCU2_Fault2 0;
BA_ "GenSigSendType" SG_ 866 DCU2_Fault2 1;
BA_ "EventCommandSignal" SG_ 866 DCU2_Fault3 0;
BA_ "GatewayedSignals" SG_ 866 DCU2_Fault3 0;
BA_ "GenSigSendType" SG_ 866 DCU2_Fault3 1;
BA_ "EventCommandSignal" SG_ 866 DCU2_Fault4 0;
BA_ "GatewayedSignals" SG_ 866 DCU2_Fault4 0;
BA_ "GenSigSendType" SG_ 866 DCU2_Fault4 1;
BA_ "EventCommandSignal" SG_ 866 DCU2_OffsetCalVal 0;
BA_ "GatewayedSignals" SG_ 866 DCU2_OffsetCalVal 0;
BA_ "GenSigSendType" SG_ 866 DCU2_OffsetCalVal 1;
BA_ "GenSigStartValue" SG_ 866 DCU2_OffsetCalVal 8191;
BA_ "EventCommandSignal" SG_ 866 DCU2_EngMilLampReq 0;
BA_ "GatewayedSignals" SG_ 866 DCU2_EngMilLampReq 0;
BA_ "GenSigSendType" SG_ 866 DCU2_EngMilLampReq 1;
BA_ "EventCommandSignal" SG_ 866 DCU2_ZeroTorqCompensateSt 0;
BA_ "GatewayedSignals" SG_ 866 DCU2_ZeroTorqCompensateSt 0;
BA_ "GenSigSendType" SG_ 866 DCU2_ZeroTorqCompensateSt 1;
BA_ "EventCommandSignal" SG_ 1275 DCU2_Data1No 0;
BA_ "GatewayedSignals" SG_ 1275 DCU2_Data1No 0;
BA_ "GenSigSendType" SG_ 1275 DCU2_Data1No 1;
BA_ "GenSigStartValue" SG_ 1275 DCU2_Data1No 1;
BA_ "EventCommandSignal" SG_ 1275 DCU2_Hwversion 1;
BA_ "GatewayedSignals" SG_ 1275 DCU2_Hwversion 0;
BA_ "GenSigSendType" SG_ 1275 DCU2_Hwversion 0;
BA_ "EventCommandSignal" SG_ 1275 DCU2_Swversion 1;
BA_ "GatewayedSignals" SG_ 1275 DCU2_Swversion 0;
BA_ "GenSigSendType" SG_ 1275 DCU2_Swversion 0;
BA_ "EventCommandSignal" SG_ 1275 DCU2_SwVerExt 1;
BA_ "GatewayedSignals" SG_ 1275 DCU2_SwVerExt 0;
BA_ "GenSigSendType" SG_ 1275 DCU2_SwVerExt 0;
BA_ "EventCommandSignal" SG_ 1275 DCU2_OffsetAngle 1;
BA_ "GatewayedSignals" SG_ 1275 DCU2_OffsetAngle 0;
BA_ "GenSigSendType" SG_ 1275 DCU2_OffsetAngle 0;
BA_ "EventCommandSignal" SG_ 1275 DCU2_BootSV 1;
BA_ "GatewayedSignals" SG_ 1275 DCU2_BootSV 0;
BA_ "GenSigSendType" SG_ 1275 DCU2_BootSV 0;
BA_ "EventCommandSignal" SG_ 1275 DCU2_BSWVersion 1;
BA_ "GatewayedSignals" SG_ 1275 DCU2_BSWVersion 0;
BA_ "GenSigSendType" SG_ 1275 DCU2_BSWVersion 0;
BA_ "EventCommandSignal" SG_ 1275 DCU2_HWConfig 0;
BA_ "GatewayedSignals" SG_ 1275 DCU2_HWConfig 0;
BA_ "GenSigSendType" SG_ 1275 DCU2_HWConfig 1;
BA_ "EventCommandSignal" SG_ 1275 DCU2_SWConfig 0;
BA_ "GatewayedSignals" SG_ 1275 DCU2_SWConfig 0;
BA_ "GenSigSendType" SG_ 1275 DCU2_SWConfig 1;
BA_ "EventCommandSignal" SG_ 1275 DCU2_MCAConfig 0;
BA_ "GatewayedSignals" SG_ 1275 DCU2_MCAConfig 0;
BA_ "GenSigSendType" SG_ 1275 DCU2_MCAConfig 1;
BA_ "EventCommandSignal" SG_ 1275 DCU2_FHConfig 0;
BA_ "GatewayedSignals" SG_ 1275 DCU2_FHConfig 0;
BA_ "GenSigSendType" SG_ 1275 DCU2_FHConfig 1;
BA_ "EventCommandSignal" SG_ 1275 DCU2_InvtPhaUTemp 0;
BA_ "GatewayedSignals" SG_ 1275 DCU2_InvtPhaUTemp 0;
BA_ "GenSigInvalidValue" SG_ 1275 DCU2_InvtPhaUTemp 255;
BA_ "GenSigSendType" SG_ 1275 DCU2_InvtPhaUTemp 1;
BA_ "EventCommandSignal" SG_ 1275 DCU2_InvtPhaVTemp 0;
BA_ "GatewayedSignals" SG_ 1275 DCU2_InvtPhaVTemp 0;
BA_ "GenSigInvalidValue" SG_ 1275 DCU2_InvtPhaVTemp 255;
BA_ "GenSigSendType" SG_ 1275 DCU2_InvtPhaVTemp 1;
BA_ "EventCommandSignal" SG_ 1275 DCU2_InvtPhaWTemp 0;
BA_ "GatewayedSignals" SG_ 1275 DCU2_InvtPhaWTemp 0;
BA_ "GenSigInvalidValue" SG_ 1275 DCU2_InvtPhaWTemp 255;
BA_ "GenSigSendType" SG_ 1275 DCU2_InvtPhaWTemp 1;
BA_ "EventCommandSignal" SG_ 1275 DCU2_Stat1Temp 0;
BA_ "GatewayedSignals" SG_ 1275 DCU2_Stat1Temp 0;
BA_ "GenSigInvalidValue" SG_ 1275 DCU2_Stat1Temp 255;
BA_ "GenSigSendType" SG_ 1275 DCU2_Stat1Temp 1;
BA_ "EventCommandSignal" SG_ 1275 DCU2_Stat2Temp 0;
BA_ "GatewayedSignals" SG_ 1275 DCU2_Stat2Temp 0;
BA_ "GenSigInvalidValue" SG_ 1275 DCU2_Stat2Temp 255;
BA_ "GenSigSendType" SG_ 1275 DCU2_Stat2Temp 1;
BA_ "EventCommandSignal" SG_ 1275 DCU2_CtrlBoardTemp 0;
BA_ "GatewayedSignals" SG_ 1275 DCU2_CtrlBoardTemp 0;
BA_ "GenSigInvalidValue" SG_ 1275 DCU2_CtrlBoardTemp 255;
BA_ "GenSigSendType" SG_ 1275 DCU2_CtrlBoardTemp 1;
BA_ "EventCommandSignal" SG_ 1275 DCU2_DrvBoardTemp 0;
BA_ "GatewayedSignals" SG_ 1275 DCU2_DrvBoardTemp 0;
BA_ "GenSigInvalidValue" SG_ 1275 DCU2_DrvBoardTemp 255;
BA_ "GenSigSendType" SG_ 1275 DCU2_DrvBoardTemp 1;
BA_ "EventCommandSignal" SG_ 1275 DCU2_CapTemp 0;
BA_ "GatewayedSignals" SG_ 1275 DCU2_CapTemp 0;
BA_ "GenSigInvalidValue" SG_ 1275 DCU2_CapTemp 255;
BA_ "GenSigSendType" SG_ 1275 DCU2_CapTemp 1;
BA_ "EventCommandSignal" SG_ 1275 DCU2_FusastSafePathReq 0;
BA_ "GatewayedSignals" SG_ 1275 DCU2_FusastSafePathReq 0;
BA_ "GenSigSendType" SG_ 1275 DCU2_FusastSafePathReq 1;
BA_ "EventCommandSignal" SG_ 1275 DCU2_FusaModeSt 0;
BA_ "GatewayedSignals" SG_ 1275 DCU2_FusaModeSt 0;
BA_ "GenSigSendType" SG_ 1275 DCU2_FusaModeSt 1;
BA_ "EventCommandSignal" SG_ 1275 DCU2_FusaQDisChargeReq 0;
BA_ "GatewayedSignals" SG_ 1275 DCU2_FusaQDisChargeReq 0;
BA_ "GenSigSendType" SG_ 1275 DCU2_FusaQDisChargeReq 1;
BA_ "EventCommandSignal" SG_ 1275 DCU2_FusastPWMEna 0;
BA_ "GatewayedSignals" SG_ 1275 DCU2_FusastPWMEna 0;
BA_ "GenSigSendType" SG_ 1275 DCU2_FusastPWMEna 1;
BA_ "EventCommandSignal" SG_ 1275 DCU2_FusaErrCode 0;
BA_ "GatewayedSignals" SG_ 1275 DCU2_FusaErrCode 0;
BA_ "GenSigSendType" SG_ 1275 DCU2_FusaErrCode 1;
BA_ "EventCommandSignal" SG_ 1275 DCU2_FusaRotSpdAct 0;
BA_ "GatewayedSignals" SG_ 1275 DCU2_FusaRotSpdAct 0;
BA_ "GenSigSendType" SG_ 1275 DCU2_FusaRotSpdAct 1;
BA_ "EventCommandSignal" SG_ 1275 DCU2_FusaTorqAct 0;
BA_ "GatewayedSignals" SG_ 1275 DCU2_FusaTorqAct 0;
BA_ "GenSigSendType" SG_ 1275 DCU2_FusaTorqAct 1;
BA_ "EventCommandSignal" SG_ 1275 DCU2_FusaFaultInfo7 0;
BA_ "GatewayedSignals" SG_ 1275 DCU2_FusaFaultInfo7 0;
BA_ "GenSigSendType" SG_ 1275 DCU2_FusaFaultInfo7 1;
BA_ "EventCommandSignal" SG_ 1275 DCU2_FusaFaultInfo8 0;
BA_ "GatewayedSignals" SG_ 1275 DCU2_FusaFaultInfo8 0;
BA_ "GenSigSendType" SG_ 1275 DCU2_FusaFaultInfo8 1;
BA_ "EventCommandSignal" SG_ 1275 DCU2_FaultData_RC 1;
BA_ "GatewayedSignals" SG_ 1275 DCU2_FaultData_RC 0;
BA_ "GenSigSendType" SG_ 1275 DCU2_FaultData_RC 0;
BA_ "EventCommandSignal" SG_ 1275 DCU2_stHandleOff 1;
BA_ "GatewayedSignals" SG_ 1275 DCU2_stHandleOff 0;
BA_ "GenSigSendType" SG_ 1275 DCU2_stHandleOff 0;
BA_ "EventCommandSignal" SG_ 1275 DCU2_stPWMEna 1;
BA_ "GatewayedSignals" SG_ 1275 DCU2_stPWMEna 0;
BA_ "GenSigSendType" SG_ 1275 DCU2_stPWMEna 0;
BA_ "EventCommandSignal" SG_ 1275 DCU2_stMode 1;
BA_ "GatewayedSignals" SG_ 1275 DCU2_stMode 0;
BA_ "GenSigSendType" SG_ 1275 DCU2_stMode 0;
BA_ "GenSigStartValue" SG_ 1275 DCU2_stMode 1;
BA_ "EventCommandSignal" SG_ 1275 DCU2_FailCode 1;
BA_ "GatewayedSignals" SG_ 1275 DCU2_FailCode 0;
BA_ "GenSigSendType" SG_ 1275 DCU2_FailCode 0;
BA_ "EventCommandSignal" SG_ 1275 DCU2_stASCProt 1;
BA_ "GatewayedSignals" SG_ 1275 DCU2_stASCProt 0;
BA_ "GenSigSendType" SG_ 1275 DCU2_stASCProt 0;
BA_ "EventCommandSignal" SG_ 1275 DCU2_agRotorPosn 1;
BA_ "GatewayedSignals" SG_ 1275 DCU2_agRotorPosn 0;
BA_ "GenSigSendType" SG_ 1275 DCU2_agRotorPosn 0;
BA_ "EventCommandSignal" SG_ 1275 DCU2_RelativeTime 1;
BA_ "GatewayedSignals" SG_ 1275 DCU2_RelativeTime 0;
BA_ "GenSigSendType" SG_ 1275 DCU2_RelativeTime 0;
BA_ "EventCommandSignal" SG_ 1275 DCU2_stFaultFlag100us 1;
BA_ "GatewayedSignals" SG_ 1275 DCU2_stFaultFlag100us 0;
BA_ "GenSigSendType" SG_ 1275 DCU2_stFaultFlag100us 0;
BA_ "EventCommandSignal" SG_ 1275 DCU2_PWMFreq 1;
BA_ "GatewayedSignals" SG_ 1275 DCU2_PWMFreq 0;
BA_ "GenSigSendType" SG_ 1275 DCU2_PWMFreq 0;
BA_ "GenSigStartValue" SG_ 1275 DCU2_PWMFreq 10000;
BA_ "EventCommandSignal" SG_ 1275 DCU2_uDcVolt 1;
BA_ "GatewayedSignals" SG_ 1275 DCU2_uDcVolt 0;
BA_ "GenSigSendType" SG_ 1275 DCU2_uDcVolt 0;
BA_ "EventCommandSignal" SG_ 1275 DCU2_uLowVolt 1;
BA_ "GatewayedSignals" SG_ 1275 DCU2_uLowVolt 0;
BA_ "GenSigSendType" SG_ 1275 DCU2_uLowVolt 0;
BA_ "EventCommandSignal" SG_ 1275 DCU2_iCurdFinalRef 1;
BA_ "GatewayedSignals" SG_ 1275 DCU2_iCurdFinalRef 0;
BA_ "GenSigSendType" SG_ 1275 DCU2_iCurdFinalRef 0;
BA_ "EventCommandSignal" SG_ 1275 DCU2_iCurqFinalRef 1;
BA_ "GatewayedSignals" SG_ 1275 DCU2_iCurqFinalRef 0;
BA_ "GenSigSendType" SG_ 1275 DCU2_iCurqFinalRef 0;
BA_ "EventCommandSignal" SG_ 1275 DCU2_iCurdFb 1;
BA_ "GatewayedSignals" SG_ 1275 DCU2_iCurdFb 0;
BA_ "GenSigSendType" SG_ 1275 DCU2_iCurdFb 0;
BA_ "EventCommandSignal" SG_ 1275 DCU2_iCurqFb 1;
BA_ "GatewayedSignals" SG_ 1275 DCU2_iCurqFb 0;
BA_ "GenSigSendType" SG_ 1275 DCU2_iCurqFb 0;
BA_ "EventCommandSignal" SG_ 1275 DCU2_iPhaCurU 1;
BA_ "GatewayedSignals" SG_ 1275 DCU2_iPhaCurU 0;
BA_ "GenSigSendType" SG_ 1275 DCU2_iPhaCurU 0;
BA_ "EventCommandSignal" SG_ 1275 DCU2_iPhaCurV 1;
BA_ "GatewayedSignals" SG_ 1275 DCU2_iPhaCurV 0;
BA_ "GenSigSendType" SG_ 1275 DCU2_iPhaCurV 0;
BA_ "EventCommandSignal" SG_ 1275 DCU2_iPhaCurW 1;
BA_ "GatewayedSignals" SG_ 1275 DCU2_iPhaCurW 0;
BA_ "GenSigSendType" SG_ 1275 DCU2_iPhaCurW 0;
BA_ "EventCommandSignal" SG_ 1275 DCU2_uVoltdFinalRef 1;
BA_ "GatewayedSignals" SG_ 1275 DCU2_uVoltdFinalRef 0;
BA_ "GenSigSendType" SG_ 1275 DCU2_uVoltdFinalRef 0;
BA_ "EventCommandSignal" SG_ 1275 DCU2_uVoltqFinalRef 1;
BA_ "GatewayedSignals" SG_ 1275 DCU2_uVoltqFinalRef 0;
BA_ "GenSigSendType" SG_ 1275 DCU2_uVoltqFinalRef 0;
BA_ "EventCommandSignal" SG_ 1275 DCU2_iDcCur 1;
BA_ "GatewayedSignals" SG_ 1275 DCU2_iDcCur 0;
BA_ "GenSigSendType" SG_ 1275 DCU2_iDcCur 0;
BA_ "EventCommandSignal" SG_ 1275 DCU2_ResFaultFlag 1;
BA_ "GatewayedSignals" SG_ 1275 DCU2_ResFaultFlag 0;
BA_ "GenSigSendType" SG_ 1275 DCU2_ResFaultFlag 0;
BA_ "EventCommandSignal" SG_ 1275 DCU2_stTsc 1;
BA_ "GatewayedSignals" SG_ 1275 DCU2_stTsc 0;
BA_ "GenSigSendType" SG_ 1275 DCU2_stTsc 0;
BA_ "EventCommandSignal" SG_ 1275 DCU2_OperatingCycle 1;
BA_ "GatewayedSignals" SG_ 1275 DCU2_OperatingCycle 0;
BA_ "GenSigSendType" SG_ 1275 DCU2_OperatingCycle 0;
BA_ "EventCommandSignal" SG_ 1275 DCU2_Year 1;
BA_ "GatewayedSignals" SG_ 1275 DCU2_Year 0;
BA_ "GenSigSendType" SG_ 1275 DCU2_Year 0;
BA_ "GenSigStartValue" SG_ 1275 DCU2_Year 15;
BA_ "EventCommandSignal" SG_ 1275 DCU2_Month 1;
BA_ "GatewayedSignals" SG_ 1275 DCU2_Month 0;
BA_ "GenSigSendType" SG_ 1275 DCU2_Month 0;
BA_ "GenSigStartValue" SG_ 1275 DCU2_Month 1;
BA_ "EventCommandSignal" SG_ 1275 DCU2_Day 1;
BA_ "GatewayedSignals" SG_ 1275 DCU2_Day 0;
BA_ "GenSigSendType" SG_ 1275 DCU2_Day 0;
BA_ "GenSigStartValue" SG_ 1275 DCU2_Day 1;
BA_ "EventCommandSignal" SG_ 1275 DCU2_Hour 1;
BA_ "GatewayedSignals" SG_ 1275 DCU2_Hour 0;
BA_ "GenSigSendType" SG_ 1275 DCU2_Hour 0;
BA_ "EventCommandSignal" SG_ 1275 DCU2_Minute 1;
BA_ "GatewayedSignals" SG_ 1275 DCU2_Minute 0;
BA_ "GenSigSendType" SG_ 1275 DCU2_Minute 0;
BA_ "EventCommandSignal" SG_ 1275 DCU2_Second 1;
BA_ "GatewayedSignals" SG_ 1275 DCU2_Second 0;
BA_ "GenSigSendType" SG_ 1275 DCU2_Second 0;
BA_ "EventCommandSignal" SG_ 1275 DCU2_FaultData_1Bit_1 1;
BA_ "GatewayedSignals" SG_ 1275 DCU2_FaultData_1Bit_1 0;
BA_ "GenSigSendType" SG_ 1275 DCU2_FaultData_1Bit_1 0;
BA_ "EventCommandSignal" SG_ 1275 DCU2_FaultData_1Bit_2 1;
BA_ "GatewayedSignals" SG_ 1275 DCU2_FaultData_1Bit_2 0;
BA_ "GenSigSendType" SG_ 1275 DCU2_FaultData_1Bit_2 0;
BA_ "EventCommandSignal" SG_ 1275 DCU2_FaultData_1Bit_3 1;
BA_ "GatewayedSignals" SG_ 1275 DCU2_FaultData_1Bit_3 0;
BA_ "GenSigSendType" SG_ 1275 DCU2_FaultData_1Bit_3 0;
BA_ "EventCommandSignal" SG_ 1275 DCU2_FaultData_1Bit_4 1;
BA_ "GatewayedSignals" SG_ 1275 DCU2_FaultData_1Bit_4 0;
BA_ "GenSigSendType" SG_ 1275 DCU2_FaultData_1Bit_4 0;
BA_ "EventCommandSignal" SG_ 1275 DCU2_FaultData_4Bit_1 1;
BA_ "GatewayedSignals" SG_ 1275 DCU2_FaultData_4Bit_1 0;
BA_ "GenSigSendType" SG_ 1275 DCU2_FaultData_4Bit_1 0;
BA_ "EventCommandSignal" SG_ 1275 DCU2_FaultData_12Bit_1 1;
BA_ "GatewayedSignals" SG_ 1275 DCU2_FaultData_12Bit_1 0;
BA_ "GenSigSendType" SG_ 1275 DCU2_FaultData_12Bit_1 0;
BA_ "EventCommandSignal" SG_ 1275 DCU2_FaultData_16Bit_1 1;
BA_ "GatewayedSignals" SG_ 1275 DCU2_FaultData_16Bit_1 0;
BA_ "GenSigSendType" SG_ 1275 DCU2_FaultData_16Bit_1 0;
BA_ "EventCommandSignal" SG_ 1275 DCU2_stIGBTFault 1;
BA_ "GatewayedSignals" SG_ 1275 DCU2_stIGBTFault 0;
BA_ "GenSigSendType" SG_ 1275 DCU2_stIGBTFault 0;
BA_ "EventCommandSignal" SG_ 1275 DCU2_stBigDataTrigger 1;
BA_ "GatewayedSignals" SG_ 1275 DCU2_stBigDataTrigger 0;
BA_ "GenSigSendType" SG_ 1275 DCU2_stBigDataTrigger 0;
BA_ "EventCommandSignal" SG_ 1275 DCU2_FaultData_4Bit_2 1;
BA_ "GatewayedSignals" SG_ 1275 DCU2_FaultData_4Bit_2 0;
BA_ "GenSigSendType" SG_ 1275 DCU2_FaultData_4Bit_2 0;
BA_ "EventCommandSignal" SG_ 1275 DCU2_FaultData_4Bit_3 1;
BA_ "GatewayedSignals" SG_ 1275 DCU2_FaultData_4Bit_3 0;
BA_ "GenSigSendType" SG_ 1275 DCU2_FaultData_4Bit_3 0;
BA_ "EventCommandSignal" SG_ 1275 DCU2_FaultData_8Bit_1 1;
BA_ "GatewayedSignals" SG_ 1275 DCU2_FaultData_8Bit_1 0;
BA_ "GenSigSendType" SG_ 1275 DCU2_FaultData_8Bit_1 0;
BA_ "EventCommandSignal" SG_ 1275 DCU2_FaultData_8Bit_2 1;
BA_ "GatewayedSignals" SG_ 1275 DCU2_FaultData_8Bit_2 0;
BA_ "GenSigSendType" SG_ 1275 DCU2_FaultData_8Bit_2 0;
BA_ "EventCommandSignal" SG_ 1275 DCU2_FaultData_8Bit_3 1;
BA_ "GatewayedSignals" SG_ 1275 DCU2_FaultData_8Bit_3 0;
BA_ "GenSigSendType" SG_ 1275 DCU2_FaultData_8Bit_3 0;
BA_ "EventCommandSignal" SG_ 1275 DCU2_FaultData_8Bit_4 1;
BA_ "GatewayedSignals" SG_ 1275 DCU2_FaultData_8Bit_4 0;
BA_ "GenSigSendType" SG_ 1275 DCU2_FaultData_8Bit_4 0;
BA_ "EventCommandSignal" SG_ 1275 DCU2_FaultData_12Bit_2 1;
BA_ "GatewayedSignals" SG_ 1275 DCU2_FaultData_12Bit_2 0;
BA_ "GenSigSendType" SG_ 1275 DCU2_FaultData_12Bit_2 0;
BA_ "EventCommandSignal" SG_ 1275 DCU2_FaultData_12Bit_3 1;
BA_ "GatewayedSignals" SG_ 1275 DCU2_FaultData_12Bit_3 0;
BA_ "GenSigSendType" SG_ 1275 DCU2_FaultData_12Bit_3 0;
BA_ "EventCommandSignal" SG_ 1275 DCU2_FaultData_16Bit_2 1;
BA_ "GatewayedSignals" SG_ 1275 DCU2_FaultData_16Bit_2 0;
BA_ "GenSigSendType" SG_ 1275 DCU2_FaultData_16Bit_2 0;
BA_ "EventCommandSignal" SG_ 1275 DCU2_FaultData_20Bit_1 1;
BA_ "GatewayedSignals" SG_ 1275 DCU2_FaultData_20Bit_1 0;
BA_ "GenSigSendType" SG_ 1275 DCU2_FaultData_20Bit_1 0;
BA_ "EventCommandSignal" SG_ 1275 DCU2_stSBCFault 1;
BA_ "GatewayedSignals" SG_ 1275 DCU2_stSBCFault 0;
BA_ "GenSigSendType" SG_ 1275 DCU2_stSBCFault 0;
BA_ "EventCommandSignal" SG_ 384 EOP_1_CRC 0;
BA_ "GatewayedSignals" SG_ 384 EOP_1_CRC 0;
BA_ "GenSigSendType" SG_ 384 EOP_1_CRC 1;
BA_ "EventCommandSignal" SG_ 384 EOP_1_Counter 0;
BA_ "GatewayedSignals" SG_ 384 EOP_1_Counter 0;
BA_ "GenSigSendType" SG_ 384 EOP_1_Counter 1;
BA_ "EventCommandSignal" SG_ 384 EOP_IdcAct 0;
BA_ "GatewayedSignals" SG_ 384 EOP_IdcAct 0;
BA_ "GenSigSendType" SG_ 384 EOP_IdcAct 1;
BA_ "EventCommandSignal" SG_ 384 EOP_IphAct 0;
BA_ "GatewayedSignals" SG_ 384 EOP_IphAct 0;
BA_ "GenSigSendType" SG_ 384 EOP_IphAct 1;
BA_ "EventCommandSignal" SG_ 384 EOP_UdcAct 0;
BA_ "GatewayedSignals" SG_ 384 EOP_UdcAct 0;
BA_ "GenSigSendType" SG_ 384 EOP_UdcAct 1;
BA_ "EventCommandSignal" SG_ 384 EOP_SpdAct 0;
BA_ "GatewayedSignals" SG_ 384 EOP_SpdAct 0;
BA_ "GenSigSendType" SG_ 384 EOP_SpdAct 1;
BA_ "EventCommandSignal" SG_ 384 EOP_Status 0;
BA_ "GatewayedSignals" SG_ 384 EOP_Status 0;
BA_ "GenSigSendType" SG_ 384 EOP_Status 1;
BA_ "EventCommandSignal" SG_ 384 EOP_duty 0;
BA_ "GatewayedSignals" SG_ 384 EOP_duty 0;
BA_ "GenSigSendType" SG_ 384 EOP_duty 1;
BA_ "EventCommandSignal" SG_ 384 EOP_ErrLevel 0;
BA_ "GatewayedSignals" SG_ 384 EOP_ErrLevel 0;
BA_ "GenSigSendType" SG_ 384 EOP_ErrLevel 1;
BA_ "EventCommandSignal" SG_ 384 EOP_RemoteDiagCode 0;
BA_ "GatewayedSignals" SG_ 384 EOP_RemoteDiagCode 0;
BA_ "GenSigSendType" SG_ 384 EOP_RemoteDiagCode 1;
BA_ "EventCommandSignal" SG_ 384 EOP_1_FreshnessValue 0;
BA_ "GatewayedSignals" SG_ 384 EOP_1_FreshnessValue 0;
BA_ "GenSigSendType" SG_ 384 EOP_1_FreshnessValue 1;
BA_ "EventCommandSignal" SG_ 384 EOP_1_MAC_Check 0;
BA_ "GatewayedSignals" SG_ 384 EOP_1_MAC_Check 0;
BA_ "GenSigSendType" SG_ 384 EOP_1_MAC_Check 1;
BA_ "EventCommandSignal" SG_ 704 IPS_DCDCHVPwr 0;
BA_ "GatewayedSignals" SG_ 704 IPS_DCDCHVPwr 0;
BA_ "GenSigSendType" SG_ 704 IPS_DCDCHVPwr 1;
BA_ "EventCommandSignal" SG_ 704 IPS_1_CRC 0;
BA_ "GatewayedSignals" SG_ 704 IPS_1_CRC 0;
BA_ "GenSigSendType" SG_ 704 IPS_1_CRC 1;
BA_ "EventCommandSignal" SG_ 704 IPS_1_Counter 0;
BA_ "GatewayedSignals" SG_ 704 IPS_1_Counter 0;
BA_ "GenSigSendType" SG_ 704 IPS_1_Counter 1;
BA_ "EventCommandSignal" SG_ 704 IPS_DCDCDiagErrCode 0;
BA_ "GatewayedSignals" SG_ 704 IPS_DCDCDiagErrCode 0;
BA_ "GenSigSendType" SG_ 704 IPS_DCDCDiagErrCode 1;
BA_ "EventCommandSignal" SG_ 704 IPS_DCDCModeSt 0;
BA_ "GatewayedSignals" SG_ 704 IPS_DCDCModeSt 0;
BA_ "GenSigSendType" SG_ 704 IPS_DCDCModeSt 1;
BA_ "EventCommandSignal" SG_ 704 IPS_KL15State 0;
BA_ "GatewayedSignals" SG_ 704 IPS_KL15State 0;
BA_ "GenSigSendType" SG_ 704 IPS_KL15State 1;
BA_ "EventCommandSignal" SG_ 704 IPS_DCDCVoltLvAct 0;
BA_ "GatewayedSignals" SG_ 704 IPS_DCDCVoltLvAct 0;
BA_ "GenSigSendType" SG_ 704 IPS_DCDCVoltLvAct 1;
BA_ "EventCommandSignal" SG_ 704 IPS_DCDCCurrHvAct 0;
BA_ "GatewayedSignals" SG_ 704 IPS_DCDCCurrHvAct 0;
BA_ "GenSigSendType" SG_ 704 IPS_DCDCCurrHvAct 1;
BA_ "EventCommandSignal" SG_ 704 IPS_DCDCCurrLvAct 0;
BA_ "GatewayedSignals" SG_ 704 IPS_DCDCCurrLvAct 0;
BA_ "GenSigSendType" SG_ 704 IPS_DCDCCurrLvAct 1;
BA_ "EventCommandSignal" SG_ 704 IPS_DCDCVoltHvAct 0;
BA_ "GatewayedSignals" SG_ 704 IPS_DCDCVoltHvAct 0;
BA_ "GenSigSendType" SG_ 704 IPS_DCDCVoltHvAct 1;
BA_ "EventCommandSignal" SG_ 704 IPS_OBCDiagErrCode 0;
BA_ "GatewayedSignals" SG_ 704 IPS_OBCDiagErrCode 0;
BA_ "GenSigSendType" SG_ 704 IPS_OBCDiagErrCode 1;
BA_ "EventCommandSignal" SG_ 704 IPS_OBCCC_St 0;
BA_ "GatewayedSignals" SG_ 704 IPS_OBCCC_St 0;
BA_ "GenSigSendType" SG_ 704 IPS_OBCCC_St 1;
BA_ "EventCommandSignal" SG_ 704 IPS_OBCCC_Res 0;
BA_ "GatewayedSignals" SG_ 704 IPS_OBCCC_Res 0;
BA_ "GenSigSendType" SG_ 704 IPS_OBCCC_Res 1;
BA_ "EventCommandSignal" SG_ 704 IPS_DchgOverload 0;
BA_ "GatewayedSignals" SG_ 704 IPS_DchgOverload 0;
BA_ "GenSigSendType" SG_ 704 IPS_DchgOverload 1;
BA_ "EventCommandSignal" SG_ 704 IPS_OBCDschDisable 0;
BA_ "GatewayedSignals" SG_ 704 IPS_OBCDschDisable 0;
BA_ "GenSigSendType" SG_ 704 IPS_OBCDschDisable 1;
BA_ "EventCommandSignal" SG_ 704 IPS_OBCModeSt 0;
BA_ "GatewayedSignals" SG_ 704 IPS_OBCModeSt 0;
BA_ "GenSigSendType" SG_ 704 IPS_OBCModeSt 1;
BA_ "EventCommandSignal" SG_ 704 IPS_OBCHvDcCurrAct 0;
BA_ "GatewayedSignals" SG_ 704 IPS_OBCHvDcCurrAct 0;
BA_ "GenSigSendType" SG_ 704 IPS_OBCHvDcCurrAct 1;
BA_ "GenSigStartValue" SG_ 704 IPS_OBCHvDcCurrAct 1024;
BA_ "EventCommandSignal" SG_ 704 IPS_OBCHvDcVoltAct 0;
BA_ "GatewayedSignals" SG_ 704 IPS_OBCHvDcVoltAct 0;
BA_ "GenSigSendType" SG_ 704 IPS_OBCHvDcVoltAct 1;
BA_ "EventCommandSignal" SG_ 704 IPS_OBCCC_Cap 0;
BA_ "GatewayedSignals" SG_ 704 IPS_OBCCC_Cap 0;
BA_ "GenSigSendType" SG_ 704 IPS_OBCCC_Cap 1;
BA_ "EventCommandSignal" SG_ 704 IPS_OBCCpS2St 0;
BA_ "GatewayedSignals" SG_ 704 IPS_OBCCpS2St 0;
BA_ "GenSigSendType" SG_ 704 IPS_OBCCpS2St 1;
BA_ "EventCommandSignal" SG_ 704 IPS_OBCCpFreqSt 0;
BA_ "GatewayedSignals" SG_ 704 IPS_OBCCpFreqSt 0;
BA_ "GenSigSendType" SG_ 704 IPS_OBCCpFreqSt 1;
BA_ "EventCommandSignal" SG_ 704 IPS_OBCCPSt 0;
BA_ "GatewayedSignals" SG_ 704 IPS_OBCCPSt 0;
BA_ "GenSigSendType" SG_ 704 IPS_OBCCPSt 1;
BA_ "EventCommandSignal" SG_ 704 IPS_OBCCp_DutyCycle 0;
BA_ "GatewayedSignals" SG_ 704 IPS_OBCCp_DutyCycle 0;
BA_ "GenSigSendType" SG_ 704 IPS_OBCCp_DutyCycle 1;
BA_ "EventCommandSignal" SG_ 704 IPS_OBCCPVolt 0;
BA_ "GatewayedSignals" SG_ 704 IPS_OBCCPVolt 0;
BA_ "GenSigSendType" SG_ 704 IPS_OBCCPVolt 1;
BA_ "EventCommandSignal" SG_ 704 IPS_OBCV2CSt 0;
BA_ "GatewayedSignals" SG_ 704 IPS_OBCV2CSt 0;
BA_ "GenSigSendType" SG_ 704 IPS_OBCV2CSt 1;
BA_ "EventCommandSignal" SG_ 704 IPS_V2CMicSwitSt 0;
BA_ "GatewayedSignals" SG_ 704 IPS_V2CMicSwitSt 0;
BA_ "GenSigSendType" SG_ 704 IPS_V2CMicSwitSt 1;
BA_ "EventCommandSignal" SG_ 704 IPS_smo_ObcModeSt 0;
BA_ "GatewayedSignals" SG_ 704 IPS_smo_ObcModeSt 0;
BA_ "GenSigSendType" SG_ 704 IPS_smo_ObcModeSt 1;
BA_ "EventCommandSignal" SG_ 704 IPS_smd_DcdcModeSt 0;
BA_ "GatewayedSignals" SG_ 704 IPS_smd_DcdcModeSt 0;
BA_ "GenSigSendType" SG_ 704 IPS_smd_DcdcModeSt 1;
BA_ "EventCommandSignal" SG_ 704 IPS_WakeOriginSignal1 0;
BA_ "GatewayedSignals" SG_ 704 IPS_WakeOriginSignal1 0;
BA_ "GenSigSendType" SG_ 704 IPS_WakeOriginSignal1 1;
BA_ "EventCommandSignal" SG_ 704 IPS_WakeOriginSignal2 0;
BA_ "GatewayedSignals" SG_ 704 IPS_WakeOriginSignal2 0;
BA_ "GenSigSendType" SG_ 704 IPS_WakeOriginSignal2 1;
BA_ "EventCommandSignal" SG_ 704 IPS_OBCCurrActL1 0;
BA_ "GatewayedSignals" SG_ 704 IPS_OBCCurrActL1 0;
BA_ "GenSigSendType" SG_ 704 IPS_OBCCurrActL1 1;
BA_ "EventCommandSignal" SG_ 704 IPS_OBCCurrActL2 0;
BA_ "GatewayedSignals" SG_ 704 IPS_OBCCurrActL2 0;
BA_ "GenSigSendType" SG_ 704 IPS_OBCCurrActL2 1;
BA_ "EventCommandSignal" SG_ 704 IPS_OBCCurrActL3 0;
BA_ "GatewayedSignals" SG_ 704 IPS_OBCCurrActL3 0;
BA_ "GenSigSendType" SG_ 704 IPS_OBCCurrActL3 1;
BA_ "EventCommandSignal" SG_ 704 IPS_DCDCKL30VoltForHyb 0;
BA_ "GatewayedSignals" SG_ 704 IPS_DCDCKL30VoltForHyb 0;
BA_ "GenSigSendType" SG_ 704 IPS_DCDCKL30VoltForHyb 1;
BA_ "EventCommandSignal" SG_ 704 IPS_DCDCHVilSt 0;
BA_ "GatewayedSignals" SG_ 704 IPS_DCDCHVilSt 0;
BA_ "GenSigSendType" SG_ 704 IPS_DCDCHVilSt 1;
BA_ "EventCommandSignal" SG_ 704 IPS_OBC_DCVolt 0;
BA_ "GatewayedSignals" SG_ 704 IPS_OBC_DCVolt 0;
BA_ "GenSigSendType" SG_ 704 IPS_OBC_DCVolt 1;
BA_ "EventCommandSignal" SG_ 704 IPS_OBCUacActL1 0;
BA_ "GatewayedSignals" SG_ 704 IPS_OBCUacActL1 0;
BA_ "GenSigSendType" SG_ 704 IPS_OBCUacActL1 1;
BA_ "EventCommandSignal" SG_ 704 IPS_OBCUacActL2 0;
BA_ "GatewayedSignals" SG_ 704 IPS_OBCUacActL2 0;
BA_ "GenSigSendType" SG_ 704 IPS_OBCUacActL2 1;
BA_ "EventCommandSignal" SG_ 704 IPS_OBCUacActL3 0;
BA_ "GatewayedSignals" SG_ 704 IPS_OBCUacActL3 0;
BA_ "GenSigSendType" SG_ 704 IPS_OBCUacActL3 1;
BA_ "EventCommandSignal" SG_ 704 IPS_HVDCHVilStForHyb 0;
BA_ "GatewayedSignals" SG_ 704 IPS_HVDCHVilStForHyb 0;
BA_ "GenSigSendType" SG_ 704 IPS_HVDCHVilStForHyb 1;
BA_ "EventCommandSignal" SG_ 704 IPS_ACHvilStForHyb 0;
BA_ "GatewayedSignals" SG_ 704 IPS_ACHvilStForHyb 0;
BA_ "GenSigSendType" SG_ 704 IPS_ACHvilStForHyb 1;
BA_ "EventCommandSignal" SG_ 704 IPS_OBCStStep 0;
BA_ "GatewayedSignals" SG_ 704 IPS_OBCStStep 0;
BA_ "GenSigSendType" SG_ 704 IPS_OBCStStep 1;
BA_ "EventCommandSignal" SG_ 704 Reserved1 0;
BA_ "GatewayedSignals" SG_ 704 Reserved1 0;
BA_ "GenSigSendType" SG_ 704 Reserved1 1;
BA_ "EventCommandSignal" SG_ 872 IPS_2_CRC 0;
BA_ "GatewayedSignals" SG_ 872 IPS_2_CRC 0;
BA_ "GenSigSendType" SG_ 872 IPS_2_CRC 1;
BA_ "EventCommandSignal" SG_ 872 IPS_2_Counter 0;
BA_ "GatewayedSignals" SG_ 872 IPS_2_Counter 0;
BA_ "GenSigSendType" SG_ 872 IPS_2_Counter 1;
BA_ "EventCommandSignal" SG_ 872 IPS_SwVersion 0;
BA_ "GatewayedSignals" SG_ 872 IPS_SwVersion 0;
BA_ "GenSigSendType" SG_ 872 IPS_SwVersion 1;
BA_ "EventCommandSignal" SG_ 872 IPS_HwSt 0;
BA_ "GatewayedSignals" SG_ 872 IPS_HwSt 0;
BA_ "GenSigSendType" SG_ 872 IPS_HwSt 1;
BA_ "EventCommandSignal" SG_ 872 IPS_RemoteDiagCode 0;
BA_ "GatewayedSignals" SG_ 872 IPS_RemoteDiagCode 0;
BA_ "GenSigSendType" SG_ 872 IPS_RemoteDiagCode 1;
BA_ "EventCommandSignal" SG_ 872 IPS_TEL_DCDCFaultLampInd 0;
BA_ "GatewayedSignals" SG_ 872 IPS_TEL_DCDCFaultLampInd 0;
BA_ "GenSigSendType" SG_ 872 IPS_TEL_DCDCFaultLampInd 1;
BA_ "EventCommandSignal" SG_ 872 IPS_TEL_DCDCTempOvrErr 0;
BA_ "GatewayedSignals" SG_ 872 IPS_TEL_DCDCTempOvrErr 0;
BA_ "GenSigSendType" SG_ 872 IPS_TEL_DCDCTempOvrErr 1;
BA_ "EventCommandSignal" SG_ 872 IPS_TEL_DCDCModeSt 0;
BA_ "GatewayedSignals" SG_ 872 IPS_TEL_DCDCModeSt 0;
BA_ "GenSigSendType" SG_ 872 IPS_TEL_DCDCModeSt 1;
BA_ "EventCommandSignal" SG_ 872 IPS_TempAct 0;
BA_ "GatewayedSignals" SG_ 872 IPS_TempAct 0;
BA_ "GenSigSendType" SG_ 872 IPS_TempAct 1;
BA_ "EventCommandSignal" SG_ 872 IPS_DCDCFaultLampInd 0;
BA_ "GatewayedSignals" SG_ 872 IPS_DCDCFaultLampInd 0;
BA_ "GenSigSendType" SG_ 872 IPS_DCDCFaultLampInd 1;
BA_ "EventCommandSignal" SG_ 872 IPS_DCDCFlowReq 0;
BA_ "GatewayedSignals" SG_ 872 IPS_DCDCFlowReq 0;
BA_ "GenSigSendType" SG_ 872 IPS_DCDCFlowReq 1;
BA_ "EventCommandSignal" SG_ 872 IPS_ChgWakeDisableFlg 0;
BA_ "GatewayedSignals" SG_ 872 IPS_ChgWakeDisableFlg 0;
BA_ "GenSigSendType" SG_ 872 IPS_ChgWakeDisableFlg 1;
BA_ "EventCommandSignal" SG_ 872 IPS_OBCChgPwrMax 0;
BA_ "GatewayedSignals" SG_ 872 IPS_OBCChgPwrMax 0;
BA_ "GenSigSendType" SG_ 872 IPS_OBCChgPwrMax 1;
BA_ "EventCommandSignal" SG_ 872 IPS_OBCFlowReq 0;
BA_ "GatewayedSignals" SG_ 872 IPS_OBCFlowReq 0;
BA_ "GenSigSendType" SG_ 872 IPS_OBCFlowReq 1;
BA_ "EventCommandSignal" SG_ 872 IPS_OBCFaultLampInd 0;
BA_ "GatewayedSignals" SG_ 872 IPS_OBCFaultLampInd 0;
BA_ "GenSigSendType" SG_ 872 IPS_OBCFaultLampInd 1;
BA_ "EventCommandSignal" SG_ 872 IPS_DCDCState1 0;
BA_ "GatewayedSignals" SG_ 872 IPS_DCDCState1 0;
BA_ "GenSigSendType" SG_ 872 IPS_DCDCState1 1;
BA_ "EventCommandSignal" SG_ 872 IPS_DCDCState2 0;
BA_ "GatewayedSignals" SG_ 872 IPS_DCDCState2 0;
BA_ "GenSigSendType" SG_ 872 IPS_DCDCState2 1;
BA_ "EventCommandSignal" SG_ 872 IPS_DCDCState3 0;
BA_ "GatewayedSignals" SG_ 872 IPS_DCDCState3 0;
BA_ "GenSigSendType" SG_ 872 IPS_DCDCState3 1;
BA_ "EventCommandSignal" SG_ 872 IPS_DCDCState4 0;
BA_ "GatewayedSignals" SG_ 872 IPS_DCDCState4 0;
BA_ "GenSigSendType" SG_ 872 IPS_DCDCState4 1;
BA_ "EventCommandSignal" SG_ 872 IPS_DCDCState5 0;
BA_ "GatewayedSignals" SG_ 872 IPS_DCDCState5 0;
BA_ "GenSigSendType" SG_ 872 IPS_DCDCState5 1;
BA_ "EventCommandSignal" SG_ 872 IPS_OBCState6 0;
BA_ "GatewayedSignals" SG_ 872 IPS_OBCState6 0;
BA_ "GenSigSendType" SG_ 872 IPS_OBCState6 1;
BA_ "EventCommandSignal" SG_ 872 IPS_OBCState7 0;
BA_ "GatewayedSignals" SG_ 872 IPS_OBCState7 0;
BA_ "GenSigSendType" SG_ 872 IPS_OBCState7 1;
BA_ "EventCommandSignal" SG_ 872 IPS_OBCState8 0;
BA_ "GatewayedSignals" SG_ 872 IPS_OBCState8 0;
BA_ "GenSigSendType" SG_ 872 IPS_OBCState8 1;
BA_ "EventCommandSignal" SG_ 872 IPS_OBCState9 0;
BA_ "GatewayedSignals" SG_ 872 IPS_OBCState9 0;
BA_ "GenSigSendType" SG_ 872 IPS_OBCState9 1;
BA_ "EventCommandSignal" SG_ 872 IPS_OBCState1 0;
BA_ "GatewayedSignals" SG_ 872 IPS_OBCState1 0;
BA_ "GenSigSendType" SG_ 872 IPS_OBCState1 1;
BA_ "EventCommandSignal" SG_ 872 IPS_OBCState2 0;
BA_ "GatewayedSignals" SG_ 872 IPS_OBCState2 0;
BA_ "GenSigSendType" SG_ 872 IPS_OBCState2 1;
BA_ "EventCommandSignal" SG_ 872 IPS_OBCState3 0;
BA_ "GatewayedSignals" SG_ 872 IPS_OBCState3 0;
BA_ "GenSigSendType" SG_ 872 IPS_OBCState3 1;
BA_ "EventCommandSignal" SG_ 872 IPS_OBCState4 0;
BA_ "GatewayedSignals" SG_ 872 IPS_OBCState4 0;
BA_ "GenSigSendType" SG_ 872 IPS_OBCState4 1;
BA_ "EventCommandSignal" SG_ 872 IPS_OBCState5 0;
BA_ "GatewayedSignals" SG_ 872 IPS_OBCState5 0;
BA_ "GenSigSendType" SG_ 872 IPS_OBCState5 1;
BA_ "EventCommandSignal" SG_ 872 IPS_DCDCTempAct 0;
BA_ "GatewayedSignals" SG_ 872 IPS_DCDCTempAct 0;
BA_ "GenSigSendType" SG_ 872 IPS_DCDCTempAct 1;
BA_ "EventCommandSignal" SG_ 872 IPS_ChgCurResp 0;
BA_ "GatewayedSignals" SG_ 872 IPS_ChgCurResp 0;
BA_ "GenSigSendType" SG_ 872 IPS_ChgCurResp 1;
BA_ "EventCommandSignal" SG_ 872 IPS_ChgCurRespAvail 0;
BA_ "GatewayedSignals" SG_ 872 IPS_ChgCurRespAvail 0;
BA_ "GenSigSendType" SG_ 872 IPS_ChgCurRespAvail 1;
BA_ "EventCommandSignal" SG_ 872 IPS_DCDCState6 0;
BA_ "GatewayedSignals" SG_ 872 IPS_DCDCState6 0;
BA_ "GenSigSendType" SG_ 872 IPS_DCDCState6 1;
BA_ "EventCommandSignal" SG_ 872 IPS_DCDCFaultLampIndOperationFla 0;
BA_ "GatewayedSignals" SG_ 872 IPS_DCDCFaultLampIndOperationFla 0;
BA_ "GenSigSendType" SG_ 872 IPS_DCDCFaultLampIndOperationFla 1;
BA_ "SystemSignalLongSymbol" SG_ 872 IPS_DCDCFaultLampIndOperationFla "IPS_DCDCFaultLampIndOperationFlag";
BA_ "EventCommandSignal" SG_ 872 IPS_DCDCFaultLampIndFlag 0;
BA_ "GatewayedSignals" SG_ 872 IPS_DCDCFaultLampIndFlag 0;
BA_ "GenSigSendType" SG_ 872 IPS_DCDCFaultLampIndFlag 1;
BA_ "EventCommandSignal" SG_ 872 IPS_OBCFaultLampIndOperationFlag 0;
BA_ "GatewayedSignals" SG_ 872 IPS_OBCFaultLampIndOperationFlag 0;
BA_ "GenSigSendType" SG_ 872 IPS_OBCFaultLampIndOperationFlag 1;
BA_ "EventCommandSignal" SG_ 872 IPS_OBCState10 0;
BA_ "GatewayedSignals" SG_ 872 IPS_OBCState10 0;
BA_ "GenSigSendType" SG_ 872 IPS_OBCState10 1;
BA_ "EventCommandSignal" SG_ 872 IPS_OBCState11 0;
BA_ "GatewayedSignals" SG_ 872 IPS_OBCState11 0;
BA_ "GenSigSendType" SG_ 872 IPS_OBCState11 1;
BA_ "EventCommandSignal" SG_ 872 IPS_DCDCState7 0;
BA_ "GatewayedSignals" SG_ 872 IPS_DCDCState7 0;
BA_ "GenSigSendType" SG_ 872 IPS_DCDCState7 1;
BA_ "EventCommandSignal" SG_ 872 IPS_DCDCState8 0;
BA_ "GatewayedSignals" SG_ 872 IPS_DCDCState8 0;
BA_ "GenSigSendType" SG_ 872 IPS_DCDCState8 1;
BA_ "EventCommandSignal" SG_ 872 IPS_DCDCState9 0;
BA_ "GatewayedSignals" SG_ 872 IPS_DCDCState9 0;
BA_ "GenSigSendType" SG_ 872 IPS_DCDCState9 1;
BA_ "EventCommandSignal" SG_ 872 IPS_DCDCState10 0;
BA_ "GatewayedSignals" SG_ 872 IPS_DCDCState10 0;
BA_ "GenSigSendType" SG_ 872 IPS_DCDCState10 1;
BA_ "EventCommandSignal" SG_ 872 IPS_OBCAclso_Res 0;
BA_ "GatewayedSignals" SG_ 872 IPS_OBCAclso_Res 0;
BA_ "GenSigSendType" SG_ 872 IPS_OBCAclso_Res 1;
BA_ "GenSigStartValue" SG_ 872 IPS_OBCAclso_Res 63;
BA_ "EventCommandSignal" SG_ 872 IPS_OBCState12 0;
BA_ "GatewayedSignals" SG_ 872 IPS_OBCState12 0;
BA_ "GenSigSendType" SG_ 872 IPS_OBCState12 1;
BA_ "EventCommandSignal" SG_ 872 IPS_OBCState13 0;
BA_ "GatewayedSignals" SG_ 872 IPS_OBCState13 0;
BA_ "GenSigSendType" SG_ 872 IPS_OBCState13 1;
BA_ "EventCommandSignal" SG_ 872 IPS_OBCState14 0;
BA_ "GatewayedSignals" SG_ 872 IPS_OBCState14 0;
BA_ "GenSigSendType" SG_ 872 IPS_OBCState14 1;
BA_ "EventCommandSignal" SG_ 872 IPS_DCDCState11 0;
BA_ "GatewayedSignals" SG_ 872 IPS_DCDCState11 0;
BA_ "GenSigSendType" SG_ 872 IPS_DCDCState11 1;
BA_ "EventCommandSignal" SG_ 872 IPS_DCDCState12 0;
BA_ "GatewayedSignals" SG_ 872 IPS_DCDCState12 0;
BA_ "GenSigSendType" SG_ 872 IPS_DCDCState12 1;
BA_ "EventCommandSignal" SG_ 872 IPS_DCDCState13 0;
BA_ "GatewayedSignals" SG_ 872 IPS_DCDCState13 0;
BA_ "GenSigSendType" SG_ 872 IPS_DCDCState13 1;
BA_ "EventCommandSignal" SG_ 872 IPS_OBCV2CCurr 0;
BA_ "GatewayedSignals" SG_ 872 IPS_OBCV2CCurr 0;
BA_ "GenSigSendType" SG_ 872 IPS_OBCV2CCurr 1;
BA_ "EventCommandSignal" SG_ 872 IPS_OBCV2CRlySt 0;
BA_ "GatewayedSignals" SG_ 872 IPS_OBCV2CRlySt 0;
BA_ "GenSigSendType" SG_ 872 IPS_OBCV2CRlySt 1;
BA_ "EventCommandSignal" SG_ 872 IPS_OBCV2LRlySt 0;
BA_ "GatewayedSignals" SG_ 872 IPS_OBCV2LRlySt 0;
BA_ "GenSigSendType" SG_ 872 IPS_OBCV2LRlySt 1;
BA_ "EventCommandSignal" SG_ 872 IPS_OBCDsgPortPwrCons 0;
BA_ "GatewayedSignals" SG_ 872 IPS_OBCDsgPortPwrCons 0;
BA_ "GenSigSendType" SG_ 872 IPS_OBCDsgPortPwrCons 1;
BA_ "EventCommandSignal" SG_ 872 IPS_OBCEngMilLampReq 0;
BA_ "GatewayedSignals" SG_ 872 IPS_OBCEngMilLampReq 0;
BA_ "GenSigSendType" SG_ 872 IPS_OBCEngMilLampReq 1;
BA_ "EventCommandSignal" SG_ 872 IPS_OBCDispDiagInfo 0;
BA_ "GatewayedSignals" SG_ 872 IPS_OBCDispDiagInfo 0;
BA_ "GenSigSendType" SG_ 872 IPS_OBCDispDiagInfo 1;
BA_ "EventCommandSignal" SG_ 1790 NIDU_UDS_Diag_Response 1;
BA_ "GatewayedSignals" SG_ 1790 NIDU_UDS_Diag_Response 0;
BA_ "GenSigSendType" SG_ 1790 NIDU_UDS_Diag_Response 0;
BA_ "EventCommandSignal" SG_ 1662 NIDU_UDS_Diag_Request 1;
BA_ "GatewayedSignals" SG_ 1662 NIDU_UDS_Diag_Request 0;
BA_ "GenSigSendType" SG_ 1662 NIDU_UDS_Diag_Request 0;
BA_ "EventCommandSignal" SG_ 2028 NIDU_OBD_Diag_Response 1;
BA_ "GatewayedSignals" SG_ 2028 NIDU_OBD_Diag_Response 0;
BA_ "GenSigSendType" SG_ 2028 NIDU_OBD_Diag_Response 0;
BA_ "EventCommandSignal" SG_ 2020 NIDU_OBD_Diag_Request 1;
BA_ "GatewayedSignals" SG_ 2020 NIDU_OBD_Diag_Request 0;
BA_ "GenSigSendType" SG_ 2020 NIDU_OBD_Diag_Request 0;
BA_ "EventCommandSignal" SG_ 1406 NIDU_NMNodeAddress 0;
BA_ "GatewayedSignals" SG_ 1406 NIDU_NMNodeAddress 0;
BA_ "GenSigSendType" SG_ 1406 NIDU_NMNodeAddress 1;
BA_ "GenSigStartValue" SG_ 1406 NIDU_NMNodeAddress 100;
BA_ "EventCommandSignal" SG_ 1406 NIDU_NMCBV 0;
BA_ "GatewayedSignals" SG_ 1406 NIDU_NMCBV 0;
BA_ "GenSigSendType" SG_ 1406 NIDU_NMCBV 1;
BA_ "EventCommandSignal" SG_ 1406 NIDU_NMWakeupOrigin 0;
BA_ "GatewayedSignals" SG_ 1406 NIDU_NMWakeupOrigin 0;
BA_ "GenSigSendType" SG_ 1406 NIDU_NMWakeupOrigin 1;
BA_ "EventCommandSignal" SG_ 1406 NIDU_PNCInformation0 0;
BA_ "GatewayedSignals" SG_ 1406 NIDU_PNCInformation0 0;
BA_ "GenSigSendType" SG_ 1406 NIDU_PNCInformation0 1;
BA_ "EventCommandSignal" SG_ 1406 NIDU_PNCInformation1 0;
BA_ "GatewayedSignals" SG_ 1406 NIDU_PNCInformation1 0;
BA_ "GenSigSendType" SG_ 1406 NIDU_PNCInformation1 1;
BA_ "EventCommandSignal" SG_ 1406 NIDU_PNCInformation2 0;
BA_ "GatewayedSignals" SG_ 1406 NIDU_PNCInformation2 0;
BA_ "GenSigSendType" SG_ 1406 NIDU_PNCInformation2 1;
BA_ "EventCommandSignal" SG_ 607 EVCC_OBCCC_Res 0;
BA_ "GatewayedSignals" SG_ 607 EVCC_OBCCC_Res 0;
BA_ "GenSigSendType" SG_ 607 EVCC_OBCCC_Res 1;
BA_ "EventCommandSignal" SG_ 607 EVCC_FaultState 0;
BA_ "GatewayedSignals" SG_ 607 EVCC_FaultState 0;
BA_ "GenSigSendType" SG_ 607 EVCC_FaultState 1;
BA_ "EventCommandSignal" SG_ 607 EVCC_ChgStd 0;
BA_ "GatewayedSignals" SG_ 607 EVCC_ChgStd 0;
BA_ "GenSigSendType" SG_ 607 EVCC_ChgStd 1;
BA_ "EventCommandSignal" SG_ 418 VCU_MotTqRateLimMin 0;
BA_ "GatewayedSignals" SG_ 418 VCU_MotTqRateLimMin 0;
BA_ "GenSigSendType" SG_ 418 VCU_MotTqRateLimMin 1;
BA_ "EventCommandSignal" SG_ 418 VCU_TqUnloadEna 0;
BA_ "GatewayedSignals" SG_ 418 VCU_TqUnloadEna 0;
BA_ "GenSigSendType" SG_ 418 VCU_TqUnloadEna 1;
BA_ "EventCommandSignal" SG_ 418 VCU_MotTqRateLimMax 0;
BA_ "GatewayedSignals" SG_ 418 VCU_MotTqRateLimMax 0;
BA_ "GenSigSendType" SG_ 418 VCU_MotTqRateLimMax 1;
BA_ "GenSigStartValue" SG_ 418 VCU_MotTqRateLimMax 1023;
BA_ "EventCommandSignal" SG_ 417 VCU_13_CRC 0;
BA_ "GatewayedSignals" SG_ 417 VCU_13_CRC 0;
BA_ "GenSigSendType" SG_ 417 VCU_13_CRC 1;
BA_ "EventCommandSignal" SG_ 417 VCU_13_Counter 0;
BA_ "GatewayedSignals" SG_ 417 VCU_13_Counter 0;
BA_ "GenSigSendType" SG_ 417 VCU_13_Counter 1;
BA_ "EventCommandSignal" SG_ 417 VCU_DCU2_IdcMax 0;
BA_ "GatewayedSignals" SG_ 417 VCU_DCU2_IdcMax 0;
BA_ "GenSigSendType" SG_ 417 VCU_DCU2_IdcMax 1;
BA_ "GenSigStartValue" SG_ 417 VCU_DCU2_IdcMax 1022;
BA_ "EventCommandSignal" SG_ 417 VCU_DCU2_IdcMin 0;
BA_ "GatewayedSignals" SG_ 417 VCU_DCU2_IdcMin 0;
BA_ "GenSigSendType" SG_ 417 VCU_DCU2_IdcMin 1;
BA_ "EventCommandSignal" SG_ 417 VCU_DCU2_TorqAllwd 0;
BA_ "GatewayedSignals" SG_ 417 VCU_DCU2_TorqAllwd 0;
BA_ "GenSigSendType" SG_ 417 VCU_DCU2_TorqAllwd 1;
BA_ "EventCommandSignal" SG_ 417 VCU_DCU2_UdcMin 0;
BA_ "GatewayedSignals" SG_ 417 VCU_DCU2_UdcMin 0;
BA_ "GenSigSendType" SG_ 417 VCU_DCU2_UdcMin 1;
BA_ "GenSigStartValue" SG_ 417 VCU_DCU2_UdcMin 1022;
BA_ "EventCommandSignal" SG_ 417 VCU_DCU2_UdcMax 0;
BA_ "GatewayedSignals" SG_ 417 VCU_DCU2_UdcMax 0;
BA_ "GenSigSendType" SG_ 417 VCU_DCU2_UdcMax 1;
BA_ "GenSigStartValue" SG_ 417 VCU_DCU2_UdcMax 1022;
BA_ "EventCommandSignal" SG_ 417 VCU_DCU2_ModeReq 0;
BA_ "GatewayedSignals" SG_ 417 VCU_DCU2_ModeReq 0;
BA_ "GenSigSendType" SG_ 417 VCU_DCU2_ModeReq 1;
BA_ "GenSigStartValue" SG_ 417 VCU_DCU2_ModeReq 1;
BA_ "EventCommandSignal" SG_ 417 VCU_DCU2_SpdSet 0;
BA_ "GatewayedSignals" SG_ 417 VCU_DCU2_SpdSet 0;
BA_ "GenSigSendType" SG_ 417 VCU_DCU2_SpdSet 1;
BA_ "GenSigStartValue" SG_ 417 VCU_DCU2_SpdSet 65534;
BA_ "EventCommandSignal" SG_ 417 VCU_DCU2_DampGain 0;
BA_ "GatewayedSignals" SG_ 417 VCU_DCU2_DampGain 0;
BA_ "GenSigSendType" SG_ 417 VCU_DCU2_DampGain 1;
BA_ "GenSigStartValue" SG_ 417 VCU_DCU2_DampGain 3;
BA_ "EventCommandSignal" SG_ 417 VCU_DCU2_ZeroTorqCompensateReq 0;
BA_ "GatewayedSignals" SG_ 417 VCU_DCU2_ZeroTorqCompensateReq 0;
BA_ "GenSigSendType" SG_ 417 VCU_DCU2_ZeroTorqCompensateReq 1;
BA_ "EventCommandSignal" SG_ 417 VCU_DCU2_DampReq 0;
BA_ "GatewayedSignals" SG_ 417 VCU_DCU2_DampReq 0;
BA_ "GenSigSendType" SG_ 417 VCU_DCU2_DampReq 1;
BA_ "EventCommandSignal" SG_ 417 VCU_DCU2_MaxTorqGradient 0;
BA_ "GatewayedSignals" SG_ 417 VCU_DCU2_MaxTorqGradient 0;
BA_ "GenSigSendType" SG_ 417 VCU_DCU2_MaxTorqGradient 1;
BA_ "GenSigStartValue" SG_ 417 VCU_DCU2_MaxTorqGradient 16382;
BA_ "EventCommandSignal" SG_ 417 VCU_DCU2_TorqMinETCS 0;
BA_ "GatewayedSignals" SG_ 417 VCU_DCU2_TorqMinETCS 0;
BA_ "GenSigSendType" SG_ 417 VCU_DCU2_TorqMinETCS 1;
BA_ "EventCommandSignal" SG_ 417 VCU_DCU2_TorqMaxETCS 0;
BA_ "GatewayedSignals" SG_ 417 VCU_DCU2_TorqMaxETCS 0;
BA_ "GenSigSendType" SG_ 417 VCU_DCU2_TorqMaxETCS 1;
BA_ "GenSigStartValue" SG_ 417 VCU_DCU2_TorqMaxETCS 1022;
BA_ "EventCommandSignal" SG_ 417 VCU_DCU2_TorqMin 0;
BA_ "GatewayedSignals" SG_ 417 VCU_DCU2_TorqMin 0;
BA_ "GenSigSendType" SG_ 417 VCU_DCU2_TorqMin 1;
BA_ "EventCommandSignal" SG_ 417 VCU_DCU2_TorqMax 0;
BA_ "GatewayedSignals" SG_ 417 VCU_DCU2_TorqMax 0;
BA_ "GenSigSendType" SG_ 417 VCU_DCU2_TorqMax 1;
BA_ "GenSigStartValue" SG_ 417 VCU_DCU2_TorqMax 1022;
BA_ "EventCommandSignal" SG_ 417 VCU_DCU2_SpdLmt 0;
BA_ "GatewayedSignals" SG_ 417 VCU_DCU2_SpdLmt 0;
BA_ "GenSigSendType" SG_ 417 VCU_DCU2_SpdLmt 1;
BA_ "GenSigStartValue" SG_ 417 VCU_DCU2_SpdLmt 32766;
BA_ "EventCommandSignal" SG_ 417 VCU_DCU2_MaxTorqDampgCtl 0;
BA_ "GatewayedSignals" SG_ 417 VCU_DCU2_MaxTorqDampgCtl 0;
BA_ "GenSigSendType" SG_ 417 VCU_DCU2_MaxTorqDampgCtl 1;
BA_ "GenSigStartValue" SG_ 417 VCU_DCU2_MaxTorqDampgCtl 254;
BA_ "EventCommandSignal" SG_ 417 VCU_DCU2_TorqSet_Hyb 0;
BA_ "GatewayedSignals" SG_ 417 VCU_DCU2_TorqSet_Hyb 0;
BA_ "GenSigSendType" SG_ 417 VCU_DCU2_TorqSet_Hyb 1;
BA_ "GenSigStartValue" SG_ 417 VCU_DCU2_TorqSet_Hyb 4095;
BA_ "EventCommandSignal" SG_ 417 VCU_ReTqUnloadEna 0;
BA_ "GatewayedSignals" SG_ 417 VCU_ReTqUnloadEna 0;
BA_ "GenSigSendType" SG_ 417 VCU_ReTqUnloadEna 1;
BA_ "EventCommandSignal" SG_ 417 VCU_ReMotTqRateLimMax 0;
BA_ "GatewayedSignals" SG_ 417 VCU_ReMotTqRateLimMax 0;
BA_ "GenSigSendType" SG_ 417 VCU_ReMotTqRateLimMax 1;
BA_ "GenSigStartValue" SG_ 417 VCU_ReMotTqRateLimMax 1023;
BA_ "EventCommandSignal" SG_ 417 VCU_ReMotTqRateLimMin 0;
BA_ "GatewayedSignals" SG_ 417 VCU_ReMotTqRateLimMin 0;
BA_ "GenSigSendType" SG_ 417 VCU_ReMotTqRateLimMin 1;
BA_ "EventCommandSignal" SG_ 557 VCU_3_CRC 0;
BA_ "GatewayedSignals" SG_ 557 VCU_3_CRC 0;
BA_ "GenSigSendType" SG_ 557 VCU_3_CRC 1;
BA_ "EventCommandSignal" SG_ 557 VCU_3_Counter 0;
BA_ "GatewayedSignals" SG_ 557 VCU_3_Counter 0;
BA_ "GenSigSendType" SG_ 557 VCU_3_Counter 1;
BA_ "EventCommandSignal" SG_ 557 VCU_IPS_OBCModeReq 0;
BA_ "GatewayedSignals" SG_ 557 VCU_IPS_OBCModeReq 0;
BA_ "GenSigSendType" SG_ 557 VCU_IPS_OBCModeReq 1;
BA_ "EventCommandSignal" SG_ 557 VCU_IPS_OBCDsChDCCurrLim 0;
BA_ "GatewayedSignals" SG_ 557 VCU_IPS_OBCDsChDCCurrLim 0;
BA_ "GenSigSendType" SG_ 557 VCU_IPS_OBCDsChDCCurrLim 1;
BA_ "EventCommandSignal" SG_ 920 VCU_4_CRC 0;
BA_ "GatewayedSignals" SG_ 920 VCU_4_CRC 0;
BA_ "GenSigSendType" SG_ 920 VCU_4_CRC 1;
BA_ "EventCommandSignal" SG_ 920 VCU_4_Counter 0;
BA_ "GatewayedSignals" SG_ 920 VCU_4_Counter 0;
BA_ "GenSigSendType" SG_ 920 VCU_4_Counter 1;
BA_ "EventCommandSignal" SG_ 920 VCU_IPS_DCDCModeReq 0;
BA_ "GatewayedSignals" SG_ 920 VCU_IPS_DCDCModeReq 0;
BA_ "GenSigSendType" SG_ 920 VCU_IPS_DCDCModeReq 1;
BA_ "EventCommandSignal" SG_ 920 VCU_IPS_DCDCLvCurrLim 0;
BA_ "GatewayedSignals" SG_ 920 VCU_IPS_DCDCLvCurrLim 0;
BA_ "GenSigSendType" SG_ 920 VCU_IPS_DCDCLvCurrLim 1;
BA_ "EventCommandSignal" SG_ 920 VCU_SRSCrashOutputSt 0;
BA_ "GatewayedSignals" SG_ 920 VCU_SRSCrashOutputSt 0;
BA_ "GenSigSendType" SG_ 920 VCU_SRSCrashOutputSt 1;
BA_ "EventCommandSignal" SG_ 920 VCU_IPS_DCDCVoltLvSet 0;
BA_ "GatewayedSignals" SG_ 920 VCU_IPS_DCDCVoltLvSet 0;
BA_ "GenSigSendType" SG_ 920 VCU_IPS_DCDCVoltLvSet 1;
BA_ "GenSigStartValue" SG_ 920 VCU_IPS_DCDCVoltLvSet 138;
BA_ "EventCommandSignal" SG_ 920 VCU_IPS_DCDCVoltLvModeSt 0;
BA_ "GatewayedSignals" SG_ 920 VCU_IPS_DCDCVoltLvModeSt 0;
BA_ "GenSigSendType" SG_ 920 VCU_IPS_DCDCVoltLvModeSt 1;
BA_ "EventCommandSignal" SG_ 920 VCU_DCDCVoltLvModeSt 0;
BA_ "GatewayedSignals" SG_ 920 VCU_DCDCVoltLvModeSt 0;
BA_ "GenSigSendType" SG_ 920 VCU_DCDCVoltLvModeSt 1;
BA_ "EventCommandSignal" SG_ 920 VCU_DCDCVoltLvSet 0;
BA_ "GatewayedSignals" SG_ 920 VCU_DCDCVoltLvSet 0;
BA_ "GenSigSendType" SG_ 920 VCU_DCDCVoltLvSet 1;
BA_ "GenSigStartValue" SG_ 920 VCU_DCDCVoltLvSet 138;
BA_ "EventCommandSignal" SG_ 920 VCU_OBCCPJumpCounter 0;
BA_ "GatewayedSignals" SG_ 920 VCU_OBCCPJumpCounter 0;
BA_ "GenSigSendType" SG_ 920 VCU_OBCCPJumpCounter 1;
BA_ "EventCommandSignal" SG_ 920 VCU_OBCCPWarning 0;
BA_ "GatewayedSignals" SG_ 920 VCU_OBCCPWarning 0;
BA_ "GenSigSendType" SG_ 920 VCU_OBCCPWarning 1;
BA_ "EventCommandSignal" SG_ 998 VCU_5_CRC 0;
BA_ "GatewayedSignals" SG_ 998 VCU_5_CRC 0;
BA_ "GenSigSendType" SG_ 998 VCU_5_CRC 1;
BA_ "EventCommandSignal" SG_ 998 VCU_5_Counter 0;
BA_ "GatewayedSignals" SG_ 998 VCU_5_Counter 0;
BA_ "GenSigSendType" SG_ 998 VCU_5_Counter 1;
BA_ "EventCommandSignal" SG_ 998 VCU_IPS_OBCChgVoltReq 0;
BA_ "GatewayedSignals" SG_ 998 VCU_IPS_OBCChgVoltReq 0;
BA_ "GenSigSendType" SG_ 998 VCU_IPS_OBCChgVoltReq 1;
BA_ "EventCommandSignal" SG_ 998 VCU_IPS_OBCChgCurrReq 0;
BA_ "GatewayedSignals" SG_ 998 VCU_IPS_OBCChgCurrReq 0;
BA_ "GenSigSendType" SG_ 998 VCU_IPS_OBCChgCurrReq 1;
BA_ "EventCommandSignal" SG_ 1034 VCU_6_CRC 0;
BA_ "GatewayedSignals" SG_ 1034 VCU_6_CRC 0;
BA_ "GenSigSendType" SG_ 1034 VCU_6_CRC 1;
BA_ "EventCommandSignal" SG_ 1034 VCU_6_Counter 0;
BA_ "GatewayedSignals" SG_ 1034 VCU_6_Counter 0;
BA_ "GenSigSendType" SG_ 1034 VCU_6_Counter 1;
BA_ "EventCommandSignal" SG_ 1034 VCU_SubEngWarmUPCycle 0;
BA_ "GatewayedSignals" SG_ 1034 VCU_SubEngWarmUPCycle 0;
BA_ "GenSigSendType" SG_ 1034 VCU_SubEngWarmUPCycle 1;
BA_ "EventCommandSignal" SG_ 1034 VCU_VehAltitude 0;
BA_ "GatewayedSignals" SG_ 1034 VCU_VehAltitude 0;
BA_ "GenSigSendType" SG_ 1034 VCU_VehAltitude 1;
BA_ "EventCommandSignal" SG_ 1034 VCU_VehIdleRunningTime 0;
BA_ "GatewayedSignals" SG_ 1034 VCU_VehIdleRunningTime 0;
BA_ "GenSigSendType" SG_ 1034 VCU_VehIdleRunningTime 1;
BA_ "EventCommandSignal" SG_ 1034 VCU_VehRunningTime 0;
BA_ "GatewayedSignals" SG_ 1034 VCU_VehRunningTime 0;
BA_ "GenSigSendType" SG_ 1034 VCU_VehRunningTime 1;
BA_ "EventCommandSignal" SG_ 1034 VCU_DriveCycleSt 0;
BA_ "GatewayedSignals" SG_ 1034 VCU_DriveCycleSt 0;
BA_ "GenSigSendType" SG_ 1034 VCU_DriveCycleSt 1;
BA_ "EventCommandSignal" SG_ 1034 VCU_VehStopTime 0;
BA_ "GatewayedSignals" SG_ 1034 VCU_VehStopTime 0;
BA_ "GenSigSendType" SG_ 1034 VCU_VehStopTime 1;
BA_ "EventCommandSignal" SG_ 860 VCU_VehRdySt 0;
BA_ "GatewayedSignals" SG_ 860 VCU_VehRdySt 0;
BA_ "GenSigSendType" SG_ 860 VCU_VehRdySt 1;
BA_ "EventCommandSignal" SG_ 860 VCU_PlgConnSt 0;
BA_ "GatewayedSignals" SG_ 860 VCU_PlgConnSt 0;
BA_ "GenSigSendType" SG_ 860 VCU_PlgConnSt 1;
BA_ "EventCommandSignal" SG_ 516 VCU_9_CRC 0;
BA_ "GatewayedSignals" SG_ 516 VCU_9_CRC 0;
BA_ "GenSigSendType" SG_ 516 VCU_9_CRC 1;
BA_ "EventCommandSignal" SG_ 516 VCU_9_Counter 0;
BA_ "GatewayedSignals" SG_ 516 VCU_9_Counter 0;
BA_ "GenSigSendType" SG_ 516 VCU_9_Counter 1;
BA_ "EventCommandSignal" SG_ 516 VCU_CrntGearLvl 0;
BA_ "GatewayedSignals" SG_ 516 VCU_CrntGearLvl 0;
BA_ "GenSigSendType" SG_ 516 VCU_CrntGearLvl 1;
BA_ "EventCommandSignal" SG_ 516 VCU_BrkPedPstVD 0;
BA_ "GatewayedSignals" SG_ 516 VCU_BrkPedPstVD 0;
BA_ "GenSigSendType" SG_ 516 VCU_BrkPedPstVD 1;
BA_ "EventCommandSignal" SG_ 516 VCU_BrkPedPst 0;
BA_ "GatewayedSignals" SG_ 516 VCU_BrkPedPst 0;
BA_ "GenSigSendType" SG_ 516 VCU_BrkPedPst 1;
BA_ "EventCommandSignal" SG_ 516 VCU_EMS_AccPedalActPst 0;
BA_ "GatewayedSignals" SG_ 516 VCU_EMS_AccPedalActPst 0;
BA_ "GenSigSendType" SG_ 516 VCU_EMS_AccPedalActPst 1;
BA_ "EventCommandSignal" SG_ 516 VCU_EMS_AccPedalActPstVD 0;
BA_ "GatewayedSignals" SG_ 516 VCU_EMS_AccPedalActPstVD 0;
BA_ "GenSigSendType" SG_ 516 VCU_EMS_AccPedalActPstVD 1;
BA_ "EventCommandSignal" SG_ 516 VCU_HTMSMTCoolantTemp 0;
BA_ "GatewayedSignals" SG_ 516 VCU_HTMSMTCoolantTemp 0;
BA_ "GenSigSendType" SG_ 516 VCU_HTMSMTCoolantTemp 1;
BA_ "GenSigStartValue" SG_ 516 VCU_HTMSMTCoolantTemp 254;
BA_ "EventCommandSignal" SG_ 516 VCU_HTMSMTCoolantTempVD 0;
BA_ "GatewayedSignals" SG_ 516 VCU_HTMSMTCoolantTempVD 0;
BA_ "GenSigSendType" SG_ 516 VCU_HTMSMTCoolantTempVD 1;
BA_ "EventCommandSignal" SG_ 616 CCU_1_CRC 0;
BA_ "GatewayedSignals" SG_ 616 CCU_1_CRC 0;
BA_ "GenSigSendType" SG_ 616 CCU_1_CRC 1;
BA_ "EventCommandSignal" SG_ 616 CCU_1_Counter 0;
BA_ "GatewayedSignals" SG_ 616 CCU_1_Counter 0;
BA_ "GenSigSendType" SG_ 616 CCU_1_Counter 1;
BA_ "EventCommandSignal" SG_ 616 UMM_UsageModeSt 0;
BA_ "GatewayedSignals" SG_ 616 UMM_UsageModeSt 0;
BA_ "GenSigSendType" SG_ 616 UMM_UsageModeSt 1;
BA_ "GenSigStartValue" SG_ 616 UMM_UsageModeSt 7;
BA_ "EventCommandSignal" SG_ 616 VMM_VehModeSt 0;
BA_ "GatewayedSignals" SG_ 616 VMM_VehModeSt 0;
BA_ "GenSigInvalidValue" SG_ 616 VMM_VehModeSt 15;
BA_ "GenSigSendType" SG_ 616 VMM_VehModeSt 1;
BA_ "GenSigStartValue" SG_ 616 VMM_VehModeSt 15;
BA_ "GenSigTimeoutValue" SG_ 616 VMM_VehModeSt 15;
BA_ "EventCommandSignal" SG_ 616 VMM_LastVehModeSt 0;
BA_ "GatewayedSignals" SG_ 616 VMM_LastVehModeSt 0;
BA_ "GenSigInvalidValue" SG_ 616 VMM_LastVehModeSt 15;
BA_ "GenSigSendType" SG_ 616 VMM_LastVehModeSt 1;
BA_ "GenSigStartValue" SG_ 616 VMM_LastVehModeSt 15;
BA_ "GenSigTimeoutValue" SG_ 616 VMM_LastVehModeSt 15;
BA_ "EventCommandSignal" SG_ 616 VMM_OTAModeSt 0;
BA_ "GatewayedSignals" SG_ 616 VMM_OTAModeSt 0;
BA_ "GenSigInvalidValue" SG_ 616 VMM_OTAModeSt 2;
BA_ "GenSigSendType" SG_ 616 VMM_OTAModeSt 1;
BA_ "EventCommandSignal" SG_ 616 IPDS_DysWakeupPowerSup 0;
BA_ "GatewayedSignals" SG_ 616 IPDS_DysWakeupPowerSup 0;
BA_ "GenSigSendType" SG_ 616 IPDS_DysWakeupPowerSup 1;
BA_ "GenSigStartValue" SG_ 616 IPDS_DysWakeupPowerSup 3;
BA_ "EventCommandSignal" SG_ 616 IPDS_EnablePowerSup 0;
BA_ "GatewayedSignals" SG_ 616 IPDS_EnablePowerSup 0;
BA_ "GenSigSendType" SG_ 616 IPDS_EnablePowerSup 1;
BA_ "EventCommandSignal" SG_ 616 Time_Year 0;
BA_ "GatewayedSignals" SG_ 616 Time_Year 0;
BA_ "GenSigSendType" SG_ 616 Time_Year 1;
BA_ "EventCommandSignal" SG_ 616 Time_Month 0;
BA_ "GatewayedSignals" SG_ 616 Time_Month 0;
BA_ "GenSigSendType" SG_ 616 Time_Month 1;
BA_ "EventCommandSignal" SG_ 616 Time_Day 0;
BA_ "GatewayedSignals" SG_ 616 Time_Day 0;
BA_ "GenSigSendType" SG_ 616 Time_Day 1;
BA_ "GenSigStartValue" SG_ 616 Time_Day 1;
BA_ "EventCommandSignal" SG_ 616 Time_Hour 0;
BA_ "GatewayedSignals" SG_ 616 Time_Hour 0;
BA_ "GenSigSendType" SG_ 616 Time_Hour 1;
BA_ "GenSigStartValue" SG_ 616 Time_Hour 1;
BA_ "EventCommandSignal" SG_ 616 Time_Min 0;
BA_ "GatewayedSignals" SG_ 616 Time_Min 0;
BA_ "GenSigSendType" SG_ 616 Time_Min 1;
BA_ "GenSigStartValue" SG_ 616 Time_Min 1;
BA_ "EventCommandSignal" SG_ 616 Time_Sec 0;
BA_ "GatewayedSignals" SG_ 616 Time_Sec 0;
BA_ "GenSigSendType" SG_ 616 Time_Sec 1;
BA_ "GenSigStartValue" SG_ 616 Time_Sec 1;
BA_ "EventCommandSignal" SG_ 816 HVAC_CorrectedExterTemp 0;
BA_ "GatewayedSignals" SG_ 816 HVAC_CorrectedExterTemp 0;
BA_ "GenSigSendType" SG_ 816 HVAC_CorrectedExterTemp 1;
BA_ "GenSigStartValue" SG_ 816 HVAC_CorrectedExterTemp 120;
BA_ "GenSigTimeoutValue" SG_ 816 HVAC_CorrectedExterTemp 120;
BA_ "EventCommandSignal" SG_ 816 HVAC_CorrectedExterTempVD 0;
BA_ "GatewayedSignals" SG_ 816 HVAC_CorrectedExterTempVD 0;
BA_ "GenSigSendType" SG_ 816 HVAC_CorrectedExterTempVD 1;
BA_ "EventCommandSignal" SG_ 816 HVAC_PTCHeatingReq 0;
BA_ "GatewayedSignals" SG_ 816 HVAC_PTCHeatingReq 0;
BA_ "GenSigSendType" SG_ 816 HVAC_PTCHeatingReq 1;
BA_ "EventCommandSignal" SG_ 816 HVAC_PTCSt 0;
BA_ "GatewayedSignals" SG_ 816 HVAC_PTCSt 0;
BA_ "GenSigSendType" SG_ 816 HVAC_PTCSt 1;
BA_ "EventCommandSignal" SG_ 816 HVAC_ECPPwrConsump 0;
BA_ "GatewayedSignals" SG_ 816 HVAC_ECPPwrConsump 0;
BA_ "GenSigInvalidValue" SG_ 816 HVAC_ECPPwrConsump 2047;
BA_ "GenSigSendType" SG_ 816 HVAC_ECPPwrConsump 1;
BA_ "EventCommandSignal" SG_ 816 HVAC_PTCOnReq 0;
BA_ "GatewayedSignals" SG_ 816 HVAC_PTCOnReq 0;
BA_ "GenSigSendType" SG_ 816 HVAC_PTCOnReq 1;
BA_ "GenSigStartValue" SG_ 816 HVAC_PTCOnReq 3;
BA_ "GenSigTimeoutValue" SG_ 816 HVAC_PTCOnReq 3;
BA_ "EventCommandSignal" SG_ 960 TMS_4_CRC 0;
BA_ "GatewayedSignals" SG_ 960 TMS_4_CRC 0;
BA_ "GenSigSendType" SG_ 960 TMS_4_CRC 1;
BA_ "EventCommandSignal" SG_ 960 TMS_4_Counter 0;
BA_ "GatewayedSignals" SG_ 960 TMS_4_Counter 0;
BA_ "GenSigSendType" SG_ 960 TMS_4_Counter 1;
BA_ "EventCommandSignal" SG_ 960 TMS_WtrPmp1DutyReq 0;
BA_ "GatewayedSignals" SG_ 960 TMS_WtrPmp1DutyReq 0;
BA_ "GenSigSendType" SG_ 960 TMS_WtrPmp1DutyReq 1;
BA_ "EventCommandSignal" SG_ 960 TMS_WtrPmp1PerdReq 0;
BA_ "GatewayedSignals" SG_ 960 TMS_WtrPmp1PerdReq 0;
BA_ "GenSigSendType" SG_ 960 TMS_WtrPmp1PerdReq 1;
BA_ "EventCommandSignal" SG_ 960 TMS_MotRadrOutCooltT 0;
BA_ "GatewayedSignals" SG_ 960 TMS_MotRadrOutCooltT 0;
BA_ "GenSigSendType" SG_ 960 TMS_MotRadrOutCooltT 1;
BA_ "GenSigStartValue" SG_ 960 TMS_MotRadrOutCooltT 130;
BA_ "GenSigTimeoutValue" SG_ 960 TMS_MotRadrOutCooltT 130;
BA_ "EventCommandSignal" SG_ 960 TMS_MotRadrOutCooltTVld 0;
BA_ "GatewayedSignals" SG_ 960 TMS_MotRadrOutCooltTVld 0;
BA_ "GenSigSendType" SG_ 960 TMS_MotRadrOutCooltTVld 1;
BA_ "EventCommandSignal" SG_ 960 TMS_WtrPmp1Fault 0;
BA_ "GatewayedSignals" SG_ 960 TMS_WtrPmp1Fault 0;
BA_ "GenSigSendType" SG_ 960 TMS_WtrPmp1Fault 1;
BA_ "GenSigTimeoutValue" SG_ 960 TMS_WtrPmp1Fault 1;
BA_ "EventCommandSignal" SG_ 960 TMS_MotRadrInCooltTFault 0;
BA_ "GatewayedSignals" SG_ 960 TMS_MotRadrInCooltTFault 0;
BA_ "GenSigSendType" SG_ 960 TMS_MotRadrInCooltTFault 1;
BA_ "EventCommandSignal" SG_ 960 TMS_MotRadrInCooltT 0;
BA_ "GatewayedSignals" SG_ 960 TMS_MotRadrInCooltT 0;
BA_ "GenSigSendType" SG_ 960 TMS_MotRadrInCooltT 1;
BA_ "EventCommandSignal" SG_ 290 IPDS_RearEOPPowerSup 1;
BA_ "GatewayedSignals" SG_ 290 IPDS_RearEOPPowerSup 0;
BA_ "GenSigSendType" SG_ 290 IPDS_RearEOPPowerSup 0;
BA_ "GenSigStartValue" SG_ 290 IPDS_RearEOPPowerSup 3;
BA_ "EventCommandSignal" SG_ 290 IPDS_KL15T1PowerSup 1;
BA_ "GatewayedSignals" SG_ 290 IPDS_KL15T1PowerSup 0;
BA_ "GenSigSendType" SG_ 290 IPDS_KL15T1PowerSup 0;
BA_ "GenSigStartValue" SG_ 290 IPDS_KL15T1PowerSup 3;
BA_ "EventCommandSignal" SG_ 1359 CCU_NMNodeAddress 0;
BA_ "GatewayedSignals" SG_ 1359 CCU_NMNodeAddress 0;
BA_ "GenSigSendType" SG_ 1359 CCU_NMNodeAddress 1;
BA_ "GenSigStartValue" SG_ 1359 CCU_NMNodeAddress 79;
BA_ "EventCommandSignal" SG_ 1359 CCU_NMCBV 0;
BA_ "GatewayedSignals" SG_ 1359 CCU_NMCBV 0;
BA_ "GenSigSendType" SG_ 1359 CCU_NMCBV 1;
BA_ "EventCommandSignal" SG_ 1359 CCU_NMWakeupOrigin 0;
BA_ "GatewayedSignals" SG_ 1359 CCU_NMWakeupOrigin 0;
BA_ "GenSigSendType" SG_ 1359 CCU_NMWakeupOrigin 1;
BA_ "EventCommandSignal" SG_ 1359 CCU_PNCInformation0 0;
BA_ "GatewayedSignals" SG_ 1359 CCU_PNCInformation0 0;
BA_ "GenSigSendType" SG_ 1359 CCU_PNCInformation0 1;
BA_ "EventCommandSignal" SG_ 1359 CCU_PNCInformation1 0;
BA_ "GatewayedSignals" SG_ 1359 CCU_PNCInformation1 0;
BA_ "GenSigSendType" SG_ 1359 CCU_PNCInformation1 1;
BA_ "EventCommandSignal" SG_ 1359 CCU_PNCInformation2 0;
BA_ "GatewayedSignals" SG_ 1359 CCU_PNCInformation2 0;
BA_ "GenSigSendType" SG_ 1359 CCU_PNCInformation2 1;
BA_ "EventCommandSignal" SG_ 352 BCS_2_CRC 0;
BA_ "GatewayedSignals" SG_ 352 BCS_2_CRC 0;
BA_ "GenSigSendType" SG_ 352 BCS_2_CRC 1;
BA_ "EventCommandSignal" SG_ 352 BCS_2_Counter 0;
BA_ "GatewayedSignals" SG_ 352 BCS_2_Counter 0;
BA_ "GenSigSendType" SG_ 352 BCS_2_Counter 1;
BA_ "EventCommandSignal" SG_ 352 BCS_VehSpd 0;
BA_ "GatewayedSignals" SG_ 352 BCS_VehSpd 0;
BA_ "GenSigSendType" SG_ 352 BCS_VehSpd 1;
BA_ "EventCommandSignal" SG_ 352 BCS_VehSpdVD 0;
BA_ "GatewayedSignals" SG_ 352 BCS_VehSpdVD 0;
BA_ "GenSigSendType" SG_ 352 BCS_VehSpdVD 1;
BA_ "EventCommandSignal" SG_ 352 BCS_EBDActiveSt 0;
BA_ "GatewayedSignals" SG_ 352 BCS_EBDActiveSt 0;
BA_ "GenSigSendType" SG_ 352 BCS_EBDActiveSt 1;
BA_ "EventCommandSignal" SG_ 352 BCS_EBDFaultSt 0;
BA_ "GatewayedSignals" SG_ 352 BCS_EBDFaultSt 0;
BA_ "GenSigSendType" SG_ 352 BCS_EBDFaultSt 1;
BA_ "GenSigStartValue" SG_ 352 BCS_EBDFaultSt 1;
BA_ "GenSigTimeoutValue" SG_ 352 BCS_EBDFaultSt 1;
BA_ "EventCommandSignal" SG_ 352 BCS_ABSActiveSt 0;
BA_ "GatewayedSignals" SG_ 352 BCS_ABSActiveSt 0;
BA_ "GenSigSendType" SG_ 352 BCS_ABSActiveSt 1;
BA_ "EventCommandSignal" SG_ 352 BCS_ABSFaultSt 0;
BA_ "GatewayedSignals" SG_ 352 BCS_ABSFaultSt 0;
BA_ "GenSigSendType" SG_ 352 BCS_ABSFaultSt 1;
BA_ "GenSigStartValue" SG_ 352 BCS_ABSFaultSt 1;
BA_ "GenSigTimeoutValue" SG_ 352 BCS_ABSFaultSt 1;
BA_ "EventCommandSignal" SG_ 352 BCS_TCSActiveSt 0;
BA_ "GatewayedSignals" SG_ 352 BCS_TCSActiveSt 0;
BA_ "GenSigSendType" SG_ 352 BCS_TCSActiveSt 1;
BA_ "EventCommandSignal" SG_ 352 BCS_TCSFaultSt 0;
BA_ "GatewayedSignals" SG_ 352 BCS_TCSFaultSt 0;
BA_ "GenSigSendType" SG_ 352 BCS_TCSFaultSt 1;
BA_ "GenSigStartValue" SG_ 352 BCS_TCSFaultSt 1;
BA_ "GenSigTimeoutValue" SG_ 352 BCS_TCSFaultSt 1;
BA_ "EventCommandSignal" SG_ 352 BCS_VDCActiveSt 0;
BA_ "GatewayedSignals" SG_ 352 BCS_VDCActiveSt 0;
BA_ "GenSigSendType" SG_ 352 BCS_VDCActiveSt 1;
BA_ "EventCommandSignal" SG_ 352 BCS_VDCFaultSt 0;
BA_ "GatewayedSignals" SG_ 352 BCS_VDCFaultSt 0;
BA_ "GenSigSendType" SG_ 352 BCS_VDCFaultSt 1;
BA_ "GenSigStartValue" SG_ 352 BCS_VDCFaultSt 1;
BA_ "GenSigTimeoutValue" SG_ 352 BCS_VDCFaultSt 1;
BA_ "EventCommandSignal" SG_ 352 BCS_RegenModulationAvailable 0;
BA_ "GatewayedSignals" SG_ 352 BCS_RegenModulationAvailable 0;
BA_ "GenSigSendType" SG_ 352 BCS_RegenModulationAvailable 1;
BA_ "EventCommandSignal" SG_ 352 BCS_RegenModuleActive 0;
BA_ "GatewayedSignals" SG_ 352 BCS_RegenModuleActive 0;
BA_ "GenSigSendType" SG_ 352 BCS_RegenModuleActive 1;
BA_ "EventCommandSignal" SG_ 352 BCS_DMCTarSpdFA 0;
BA_ "GatewayedSignals" SG_ 352 BCS_DMCTarSpdFA 0;
BA_ "GenSigSendType" SG_ 352 BCS_DMCTarSpdFA 1;
BA_ "GenSigStartValue" SG_ 352 BCS_DMCTarSpdFA 62767;
BA_ "EventCommandSignal" SG_ 352 BCS_DMCCtrModeFA 0;
BA_ "GatewayedSignals" SG_ 352 BCS_DMCCtrModeFA 0;
BA_ "GenSigSendType" SG_ 352 BCS_DMCCtrModeFA 1;
BA_ "GenSigStartValue" SG_ 352 BCS_DMCCtrModeFA 1;
BA_ "EventCommandSignal" SG_ 352 BCS_DMCVariant 0;
BA_ "GatewayedSignals" SG_ 352 BCS_DMCVariant 0;
BA_ "GenSigSendType" SG_ 352 BCS_DMCVariant 1;
BA_ "EventCommandSignal" SG_ 352 BCS_DMCTarSpdRA 0;
BA_ "GatewayedSignals" SG_ 352 BCS_DMCTarSpdRA 0;
BA_ "GenSigSendType" SG_ 352 BCS_DMCTarSpdRA 1;
BA_ "GenSigStartValue" SG_ 352 BCS_DMCTarSpdRA 62767;
BA_ "EventCommandSignal" SG_ 352 BCS_DMCCtrModeRA 0;
BA_ "GatewayedSignals" SG_ 352 BCS_DMCCtrModeRA 0;
BA_ "GenSigSendType" SG_ 352 BCS_DMCCtrModeRA 1;
BA_ "GenSigStartValue" SG_ 352 BCS_DMCCtrModeRA 1;
BA_ "EventCommandSignal" SG_ 352 BCS_EngTorqDecActiveStRA 0;
BA_ "GatewayedSignals" SG_ 352 BCS_EngTorqDecActiveStRA 0;
BA_ "GenSigSendType" SG_ 352 BCS_EngTorqDecActiveStRA 1;
BA_ "EventCommandSignal" SG_ 398 EMS_EngSpd 0;
BA_ "GatewayedSignals" SG_ 398 EMS_EngSpd 0;
BA_ "GenSigSendType" SG_ 398 EMS_EngSpd 1;
BA_ "EventCommandSignal" SG_ 398 EMS_EngSpdVD 0;
BA_ "GatewayedSignals" SG_ 398 EMS_EngSpdVD 0;
BA_ "GenSigSendType" SG_ 398 EMS_EngSpdVD 1;
BA_ "EventCommandSignal" SG_ 398 EMS_EngIdleRefSpd 0;
BA_ "GatewayedSignals" SG_ 398 EMS_EngIdleRefSpd 0;
BA_ "GenSigSendType" SG_ 398 EMS_EngIdleRefSpd 1;
BA_ "EventCommandSignal" SG_ 398 EMS_OBDDrivingCycleStForPDTC 0;
BA_ "GatewayedSignals" SG_ 398 EMS_OBDDrivingCycleStForPDTC 0;
BA_ "GenSigSendType" SG_ 398 EMS_OBDDrivingCycleStForPDTC 1;
BA_ "EventCommandSignal" SG_ 398 EMS_OBDWarmUpCycleSt 0;
BA_ "GatewayedSignals" SG_ 398 EMS_OBDWarmUpCycleSt 0;
BA_ "GenSigSendType" SG_ 398 EMS_OBDWarmUpCycleSt 1;
BA_ "EventCommandSignal" SG_ 398 EMS_AbsoluteThrottlepst 0;
BA_ "GatewayedSignals" SG_ 398 EMS_AbsoluteThrottlepst 0;
BA_ "GenSigSendType" SG_ 398 EMS_AbsoluteThrottlepst 1;
BA_ "EventCommandSignal" SG_ 398 EMS_EngWaterTemp 0;
BA_ "GatewayedSignals" SG_ 398 EMS_EngWaterTemp 0;
BA_ "GenSigSendType" SG_ 398 EMS_EngWaterTemp 1;
BA_ "EventCommandSignal" SG_ 398 EMS_EngWaterTempVD 0;
BA_ "GatewayedSignals" SG_ 398 EMS_EngWaterTempVD 0;
BA_ "GenSigSendType" SG_ 398 EMS_EngWaterTempVD 1;
BA_ "EventCommandSignal" SG_ 398 EMS_EngCalculatedLoad 0;
BA_ "GatewayedSignals" SG_ 398 EMS_EngCalculatedLoad 0;
BA_ "GenSigSendType" SG_ 398 EMS_EngCalculatedLoad 1;
BA_ "EventCommandSignal" SG_ 445 EMS_IUPRGenInh 0;
BA_ "GatewayedSignals" SG_ 445 EMS_IUPRGenInh 0;
BA_ "GenSigSendType" SG_ 445 EMS_IUPRGenInh 1;
BA_ "EventCommandSignal" SG_ 445 EMS_IURPGenDen 0;
BA_ "GatewayedSignals" SG_ 445 EMS_IURPGenDen 0;
BA_ "GenSigSendType" SG_ 445 EMS_IURPGenDen 1;
BA_ "EventCommandSignal" SG_ 445 EMS_IUPRIgCnt 0;
BA_ "GatewayedSignals" SG_ 445 EMS_IUPRIgCnt 0;
BA_ "GenSigSendType" SG_ 445 EMS_IUPRIgCnt 1;
BA_ "EventCommandSignal" SG_ 407 EMS_EngRunningTime 0;
BA_ "GatewayedSignals" SG_ 407 EMS_EngRunningTime 0;
BA_ "GenSigInvalidValue" SG_ 407 EMS_EngRunningTime 255;
BA_ "GenSigSendType" SG_ 407 EMS_EngRunningTime 1;
BA_ "EventCommandSignal" SG_ 905 ICM_TotalOdometer 0;
BA_ "GatewayedSignals" SG_ 905 ICM_TotalOdometer 0;
BA_ "GenSigSendType" SG_ 905 ICM_TotalOdometer 1;
BA_ "EventCommandSignal" SG_ 161 ACU_ACChgCurCfg 1;
BA_ "GatewayedSignals" SG_ 161 ACU_ACChgCurCfg 0;
BA_ "GenSigSendType" SG_ 161 ACU_ACChgCurCfg 0;
BA_ "EventCommandSignal" SG_ 909 WtrPmp1DutyFb 0;
BA_ "GatewayedSignals" SG_ 909 WtrPmp1DutyFb 0;
BA_ "GenSigSendType" SG_ 909 WtrPmp1DutyFb 1;
BA_ "EventCommandSignal" SG_ 909 IPDS_RearMotorPowerSt 0;
BA_ "GatewayedSignals" SG_ 909 IPDS_RearMotorPowerSt 0;
BA_ "GenSigSendType" SG_ 909 IPDS_RearMotorPowerSt 1;
BA_ "EventCommandSignal" SG_ 909 IPDS_RearEOPPowerSt 0;
BA_ "GatewayedSignals" SG_ 909 IPDS_RearEOPPowerSt 0;
BA_ "GenSigSendType" SG_ 909 IPDS_RearEOPPowerSt 1;
BA_ "EventCommandSignal" SG_ 909 IPDS_RearMotorPowerFaultSt 0;
BA_ "GatewayedSignals" SG_ 909 IPDS_RearMotorPowerFaultSt 0;
BA_ "GenSigSendType" SG_ 909 IPDS_RearMotorPowerFaultSt 1;
BA_ "EventCommandSignal" SG_ 909 IPDS_RearEOPPowerFaultSt 0;
BA_ "GatewayedSignals" SG_ 909 IPDS_RearEOPPowerFaultSt 0;
BA_ "GenSigSendType" SG_ 909 IPDS_RearEOPPowerFaultSt 1;
BA_ "EventCommandSignal" SG_ 909 IPDS_KL15T1PowerSt 0;
BA_ "GatewayedSignals" SG_ 909 IPDS_KL15T1PowerSt 0;
BA_ "GenSigSendType" SG_ 909 IPDS_KL15T1PowerSt 1;
BA_ "GenSigStartValue" SG_ 2683305995 DCU2_TempCoolant 40;
BA_ "GenSigStartValue" SG_ 2683305995 DCU2_FusaTorqAct_Debug 4095;
BA_ "GenSigStartValue" SG_ 2683305995 DCU2_FusaRotSpdAct_Debug 32767;
BA_ "EventCommandSignal" SG_ 2683305995 DCU2_DataFaultHandle 0;
BA_ "GatewayedSignals" SG_ 2683305995 DCU2_DataFaultHandle 0;
BA_ "GenSigSendType" SG_ 2683305995 DCU2_DataFaultHandle 0;
VAL_ 378 BMS_PwrDwnReq 2 "2 Request shut;" 1 "1 No request;" 0 "0 Default;" ;
VAL_ 378 BMS_DCUBattSt 1 "HVBattCntctr_Closed;" 0 "HVBattCntctr_Open;" ;
VAL_ 729 EDL_DiffLockModSt_R 0 "Disable" 1 "moving" 2 "Locked" 3 "Unlock" ;
VAL_ 1377 BMS_NMCBV 0 "Node has not woken up the    network(passive wakeup);" 1 "Node has woken up the network(active wakeup)" 0 "NM PDU contains no Partial Network request information" 1 "NM PDU contains Partial Network request information" ;
VAL_ 1377 BMS_NMWakeupOrigin 1 "Message wakeup" 18 "KL15 wakeup" 21 "CC2 wakeup" 22 "A+  wakeup" 23 "Battery check" 24 "CC1wakeup" ;
VAL_ 1377 BMS_PNCInformation0 0 "No request" 1 "Request" 0 "No request" 1 "Request" 0 "No request" 1 "Request" 0 "No request" 1 "Request" 1 "Request" 0 "No request" 1 "Request" 0 "No request" 1 "Request" ;
VAL_ 1377 BMS_PNCInformation1 0 "No request" 1 "Request" 0 "No request" 1 "Request" ;
VAL_ 369 DCU2_CCUEOPPowerSup 0 "Reserved" 1 "No active" 2 "Active" 3 "Reserved" ;
VAL_ 369 DCU2_HvilSt 3 "Failure;" 2 "HVIL is interrupted;" 1 "HVIL is closed;" 0 "HVIL generator is ready but HVIL result is not available;" ;
VAL_ 369 DCU2_DstActive 1 "Active;" 0 "No Active;" ;
VAL_ 369 DCU2_GateDrvSt 3 "ShortCircuit;" 2 "Discharge;" 1 "PWMrun;" 0 "FreeWheel;" ;
VAL_ 369 DCU2_EOP_SpdSet 0 "Init" 4095 "Error" ;
VAL_ 369 DCU2_ModeSt_Hyb 12 "HillholdCtrl" 11 "Service_General( reserved)" 10 "Power off" 9 "Offsetcal" 8 "Failure" 7 "AfterRun" 6 "Discharge" 5 "SpdCtrl" 4 "TrqCtrl" 3 "Ready" 2 "Standby" 1 "Init" 0 "Reserved" ;
VAL_ 369 DCU2_ADC_MCUBlkst 0 "no block" 1 "block" 2 "reserved" ;
VAL_ 369 DCU2_ADC_SpdSvModAvl 0 "not available" 1 "available" ;
VAL_ 369 DCU2_ADC_MCUStandstill 0 "not standstill" 1 "standstill" ;
VAL_ 369 DCU2_ADC_MCUSpdSVModFit 0 "no fault" 1 "excessive output torque fault" ;
VAL_ 369 DCU2_ADC_MCUVehSldSt 0 "not slide" 1 "slide" ;
VAL_ 369 DCU2_KL15St 0 "off" 1 "on" ;
VAL_ 866 DCU2_OffsetCalInd 1 "Calibration succeeded;" 0 "Default / nok;" ;
VAL_ 866 DCU2_SysTempOvrInd 1 "Lamp on;" 0 "Lamp off;" ;
VAL_ 866 DCU2_FaultLampInd 1 "Lamp on;" 0 "Lamp off;" ;
VAL_ 866 DCU2_ErrNotice 0 "reserved" 1 "PwrLimitLevel1" 2 "PwrLimitLevel2" 3 "Pwrloss" ;
VAL_ 866 DCU2_ETCS 0 "Inactive" 1 "Active" ;
VAL_ 866 DCU2_TEL_ECUTempOvrErr 1 "Error;" 0 "No error;" ;
VAL_ 866 DCU2_TEL_MotTempOvrErr 1 "Error;" 0 "No error;" ;
VAL_ 866 DCU2_TEL_ModeSt 4 "Standby;" 3 "Stop;" 2 "Generate electricity;" 1 "Electricity consumed;" 0 "Reserved;" 5 "Reserved;" 6 "Reserved;" 7 "Reserved;" ;
VAL_ 866 DCU2_EngMilLampReq 1 "Request" 0 "No request" ;
VAL_ 866 DCU2_ZeroTorqCompensateSt 1 "active" 0 "inactive" ;
VAL_ 384 EOP_Status 0 "Systme_Sta_Init" 1 "Systme_SelfCheck_Failure" 2 "Systme_Sta_Stand_By" 3 "Systme_Sta_Motor_Run" 4 "Systme_Sta_Failure" ;
VAL_ 384 EOP_ErrLevel 7 "reserved" 6 "reserved" 5 "reserved" 4 "Error unable to work" 3 "communication fail EOP is able to work following the strategy of itself" 2 "Error but still can work limit the EOP power as 50% or less (TBD)" 1 "Error but still can work" 0 "Normal" ;
VAL_ 384 EOP_RemoteDiagCode 0 "NOFault" 1 "A -" 2 "B Faults that cannot work" 3 "C Only store DTC corresponding faults" ;
VAL_ 704 IPS_DCDCModeSt 7 "Failure;" 3 "Active - Buck Mode;" 2 "Connected (HV is active);" 1 "Disconnected;" 0 "Init;" ;
VAL_ 704 IPS_KL15State 0 "Off;" 1 "On;" ;
VAL_ 704 IPS_OBCCC_St 7 "failure;" 4 "Connected V2L;" 2 "Connected charging/ V2V;" 1 "half connected charging/ V2V/ V2L;" 0 "disconnected;" ;
VAL_ 704 IPS_OBCDschDisable 1 "CP Duty&Frequency&Volt is OK;" 0 "CP state is not oK;" ;
VAL_ 704 IPS_OBCModeSt 7 "Failure;" 6 "Discharge overload;" 5 "Active -? V2V discharging;" 4 "Active - V2L discharging;" 3 "Active - Charging;" 2 "Connected (HV is active);" 1 "Disconnected;" 0 "Init;" ;
VAL_ 704 IPS_OBCCC_Cap 4 "64A;" 3 "32A;" 2 "16A;" 1 "10A;" 0 "Not valid;" ;
VAL_ 704 IPS_OBCCpS2St 1 "S2 is on;" 0 "S2 is off;" ;
VAL_ 704 IPS_OBCCpFreqSt 0 "The frequency is beyond 900Hz to 1100Hz" 1 "The frequency is between 900Hz to 1100Hz" ;
VAL_ 704 IPS_OBCCPSt 1 "CP Duty&Frequency&Volt is OK;" 0 "CP state is not oK;" ;
VAL_ 704 IPS_OBCV2CSt 0 "Init" 1 "V2C Inactive" 2 "V2C Active" 3 "Reserved" 4 "Reserved" 5 "Reserved" 6 "Reserved" 7 "Reserved" ;
VAL_ 704 IPS_V2CMicSwitSt 0 "Invalid" 1 "No plug in" 2 "Plug in" 3 "Failure" ;
VAL_ 704 IPS_DCDCHVilSt 3 "Failure;" 2 "HVIL is interrupted;" 1 "HVIL is closed;" 0 "HVIL generator is ready but HVIL result is not available;" ;
VAL_ 704 IPS_HVDCHVilStForHyb 3 "Failure;" 2 "HVIL is interrupted;" 1 "HVIL is closed;" 0 "HVIL generator is ready but HVIL result is not available;" ;
VAL_ 704 IPS_ACHvilStForHyb 3 "Failure;" 2 "HVIL is interrupted;" 1 "HVIL is closed;" 0 "HVIL generator is ready but HVIL result is not available;" ;
VAL_ 704 IPS_OBCStStep 0 "Step1" 1 "Step2" 2 "Step3" 3 "Step4" ;
VAL_ 872 IPS_HwSt 0 "单DCDC" 1 "单向6.6KW二合一" 2 "双向6.6KW二合一" 3 "单向6.6KW三合一" 4 "双向6.6KW三合一" 5 "双向DCDC" ;
VAL_ 872 IPS_TEL_DCDCFaultLampInd 1 "Lamp on;" 0 "Lamp off;" ;
VAL_ 872 IPS_TEL_DCDCTempOvrErr 1 "Error;" 0 "OK;" ;
VAL_ 872 IPS_TEL_DCDCModeSt 2 "OFF;" 1 "Buck;" 0 "Init;" ;
VAL_ 872 IPS_DCDCFaultLampInd 1 "Lamp on;" 0 "Lamp off;" ;
VAL_ 872 IPS_ChgWakeDisableFlg 1 "Disable" 0 "Normal" ;
VAL_ 872 IPS_OBCFaultLampInd 1 "Lamp on;" 0 "Lamp off;" ;
VAL_ 872 IPS_ChgCurResp 0 "Default；" 1 "4A；" 2 "8A；" 3 "12A；" 4 "16A；" 5 "20A；" 6 "24A；" 7 "28A；" 8 "32A；" ;
VAL_ 872 IPS_ChgCurRespAvail 0 "Not available" 1 "Available" ;
VAL_ 872 IPS_OBCV2CRlySt 5 "5 Failure" 4 "4 Stuck in closed;" 3 "3 Stuck in open;" 2 "2 Closed;" 1 "1 Open;" 0 "0 Init;" ;
VAL_ 872 IPS_OBCV2LRlySt 5 "5 Failure" 4 "4 Stuck in closed;" 3 "3 Stuck in open;" 2 "2 Closed;" 1 "1 Open;" 0 "0 Init;" ;
VAL_ 872 IPS_OBCEngMilLampReq 1 "Request;" 0 "No request;" ;
VAL_ 1406 NIDU_NMCBV 0 "Node has not woken up the    network(passive wakeup);" 1 "Node has woken up the network(active wakeup)" 0 "NM PDU contains no Partial Network request information" 1 "NM PDU contains Partial Network request information" ;
VAL_ 1406 NIDU_NMWakeupOrigin 1 "Message wakeup" 18 "KL15 wakeup" 19 "CC wakeup" 20 "CP wakeup" ;
VAL_ 1406 NIDU_PNCInformation0 0 "No request" 1 "Request" 0 "No request" 1 "Request" 0 "No request" 1 "Request" 0 "No request" 1 "Request" 1 "Request" 0 "No request" 1 "Request" 0 "No request" 1 "Request" ;
VAL_ 1406 NIDU_PNCInformation1 0 "No request" 1 "Request" 0 "No request" 1 "Request" ;
VAL_ 607 EVCC_OBCCC_Res 0 "ValueInvalid" 1 "Unconnected" 2 "ShortToGround" 3 "1500Ω" 4 "680Ω" 5 "220Ω" 6 "100Ω" 7 "480Ω" 8 "150Ω" ;
VAL_ 607 EVCC_FaultState 0 "No fault" ;
VAL_ 607 EVCC_ChgStd 0 "Initial" 1 "Europe" 2 "America" ;
VAL_ 418 VCU_TqUnloadEna 0 "disable" 1 "enabe" 2 "reserved" 3 "reserved" ;
VAL_ 417 VCU_DCU2_IdcMax 1023 "Error;" 1022 "Init;" ;
VAL_ 417 VCU_DCU2_TorqAllwd 3 "All Propulsive and Regenerative;" 2 "Regenerative torque allowed;" 1 "Propulsive torque allowed;" 0 "No torque allowed;" ;
VAL_ 417 VCU_DCU2_UdcMin 1023 "Error;" 1022 "Init;" ;
VAL_ 417 VCU_DCU2_UdcMax 1023 "Error;" 1022 "Init;" ;
VAL_ 417 VCU_DCU2_ModeReq 12 "HillholdCtrl;" 9 "Offsetcal;" 6 "Discharge;" 5 "SpdCtrl;" 4 "TrqCtrl;" 3 "Ready;" 2 "Standby;" 1 "Init;" 0 "Reserved;" ;
VAL_ 417 VCU_DCU2_SpdSet 65535 "Error;" 65534 "Init;" ;
VAL_ 417 VCU_DCU2_DampGain 3 "Default value;" 2 "High damping;" 1 "Medium damping;" 0 "Low damping;" ;
VAL_ 417 VCU_DCU2_ZeroTorqCompensateReq 1 "No request" 0 "Request" ;
VAL_ 417 VCU_DCU2_DampReq 1 "Enable;" 0 "Disable;" ;
VAL_ 417 VCU_DCU2_MaxTorqGradient 16383 "Error;" 16382 "Init;" ;
VAL_ 417 VCU_DCU2_MaxTorqDampgCtl 255 "Error;" 254 "Init;" ;
VAL_ 417 VCU_DCU2_TorqSet_Hyb 255 "Error;" 254 "Init;" ;
VAL_ 417 VCU_ReTqUnloadEna 0 "disable" 1 "enabe" 2 "reserved" 3 "reserved" ;
VAL_ 557 VCU_IPS_OBCModeReq 0 "no request" 1 "Standby" 2 "Charging" 3 "Discharging(V2L/V2V)" 4 "V2C" 5 "V2L+V2C" ;
VAL_ 920 VCU_IPS_DCDCModeReq 4 "Service_General(resvered);" 2 "Buck Mode request;" 1 "Standby requested, No power conversion;" 0 "No request, sleep indication allowed;" ;
VAL_ 920 VCU_SRSCrashOutputSt 0 "No crash," ;
VAL_ 920 VCU_IPS_DCDCVoltLvModeSt 0 "Reserved;" 1 "PAA mode;" 2 "OTA mode;" 3 "Light mode;" 4 "EEM set mode;" 5 "Transport mode;" 6 "Sensitive load mode;" 7 "EBS Fault;" 8 "Normal mode;" 9 "ChgDchgBatPrecdngMode" ;
VAL_ 920 VCU_DCDCVoltLvModeSt 0 "Reserved;" 1 "PAA mode;" 2 "OTA mode;" 3 "Light mode;" 4 "EEM set mode;" 5 "Transport mode;" 6 "Sensitive load mode;" 7 "EBS Fault;" 8 "Normal mode;" 9 "ChgDchgBatPrecdngMode" ;
VAL_ 920 VCU_OBCCPWarning 0 "No warning" 1 "Warning" ;
VAL_ 1034 VCU_SubEngWarmUPCycle 1 "True;" 0 "False;" ;
VAL_ 1034 VCU_DriveCycleSt 3 "Rserved;" 2 "Next cycle;" 1 "Current cycle;" 0 "Init;" ;
VAL_ 860 VCU_VehRdySt 0 "Not ready" 1 "Ready" ;
VAL_ 860 VCU_PlgConnSt 0 "Not connected" 1 "Plug connector connected" ;
VAL_ 516 VCU_CrntGearLvl 0 "Invalid" 1 "'D' Drive gear" 2 "'N' Neutral gear" 3 "'R' Reverse gear" 4 "'P' Park gear" 5 "Not used" 6 "Not used" 7 "Not used" ;
VAL_ 516 VCU_BrkPedPstVD 0 "Not valid" 1 "Valid" ;
VAL_ 516 VCU_EMS_AccPedalActPstVD 0 "Not valid" 1 "Valid" ;
VAL_ 516 VCU_HTMSMTCoolantTemp 255 "error;" 254 "Init;" ;
VAL_ 516 VCU_HTMSMTCoolantTempVD 1 "Valid;" 0 "invalid;" ;
VAL_ 616 UMM_UsageModeSt 0 "Standby" 1 "Comfort" 2 "Reserved" 3 "DRV" 4 "Reserved" 5 "Reserved" 6 "Reserved" 7 "Invalid" ;
VAL_ 616 VMM_VehModeSt 0 "Normal Mode" 1 "Manufacture Mode" 2 "Transport Mode" 3 "Showroom Mode" 4 "PostCrash Mode" 5 "Maintenance Mode" 6 "Reserved" 7 "Reserved" 8 "Reserved" 9 "Reserved" 10 "Reserved" 11 "Reserved" 12 "Reserved" 13 "Reserved" 14 "Reserved" 15 "Invalid Value" ;
VAL_ 616 VMM_LastVehModeSt 0 "Normal Mode" 1 "Manufacture Mode" 2 "Transport Mode" 3 "Showroom Mode" 4 "PostCrash Mode" 5 "Maintenance Mode" 6 "Reserved" 7 "Reserved" 8 "Reserved" 9 "Reserved" 10 "Reserved" 11 "Reserved" 12 "Reserved" 13 "Reserved" 14 "Reserved" 15 "Invalid Value" ;
VAL_ 616 VMM_OTAModeSt 0 "NonOTA Mode" 1 "OTA Mode" 2 "Invalid Value" 3 "reserved" ;
VAL_ 616 IPDS_DysWakeupPowerSup 0 "Not Active" 1 "Active" 2 "PreOFF" 3 "Invalid" ;
VAL_ 616 IPDS_EnablePowerSup 0 "Not Active" 1 "Active" 2 "PreOFF" 3 "Reserve" ;
VAL_ 816 HVAC_CorrectedExterTempVD 0 "Not valid" 1 "Valid" ;
VAL_ 816 HVAC_PTCSt 0 "NO OFF& downshift" 1 "OFF or downshift" ;
VAL_ 816 HVAC_PTCOnReq 0 "Reserve" 1 "PTC off" 2 "PTC on" 3 "Reserve" ;
VAL_ 960 TMS_MotRadrOutCooltTVld 0 "Invalid" 1 "Valid" ;
VAL_ 960 TMS_WtrPmp1Fault 0 "No ERROR" 1 "ERROR" ;
VAL_ 960 TMS_MotRadrInCooltTFault 0 "Normal" 1 "circuit short to ground" 2 "circuit short to battery or open" 3 "reserve" ;
VAL_ 290 IPDS_RearEOPPowerSup 0 "Not Active" 1 "Active" 2 "PreOFF" 3 "Invalid" ;
VAL_ 290 IPDS_KL15T1PowerSup 0 "Not Active" 1 "Active" 2 "PreOFF" 3 "Invalid" ;
VAL_ 1359 CCU_NMCBV 0 "Node has not woken up the    network(passive wakeup);" 1 "Node has woken up the network(active wakeup)" 0 "NM PDU contains no Partial Network request information" 1 "NM PDU contains Partial Network request information" ;
VAL_ 1359 CCU_NMWakeupOrigin 0 "Reserved" 1 "CAN channel 0" 2 "CAN channel 1" 3 "CAN channel 2" 4 "CAN channel 3" 5 "CAN channel 4" 6 "CAN channel 5" 7 "CAN channel 6" 8 "CAN channel 7" 9 "CAN channel 8" 10 "CAN channel 9" 11 "CAN channel 10" 12 "CAN channel 11" 13 "CAN channel 12" 14 "CAN channel 13" 15 "CAN channel 14" 16 "CAN channel 15" 17 "Reserved" 18 "Reserved" 19 "Reserved" 20 "AcoreRequest" 21 "Reserved" 22 "Reserved" 23 "Reserved" 24 "Reserved" 25 "Reserved" 26 "Reserved" 27 "Reserved" 28 "Reserved" 29 "Reserved" 30 "Reserved" 31 "Reserved" 32 "Reserved" 33 "Reserved" 34 "Reserved" 35 "Reserved" 36 "Reserved" 37 "Reserved" 38 "Reserved" 39 "Reserved" 40 "Reserved" 41 "Reserved" 42 "Reserved" 43 "Reserved" 44 "Reserved" 45 "Reserved" 46 "Reserved" 47 "Reserved" 48 "Reserved" 49 "Reserved" 50 "UsageModeSt" 51 "NMiDPSNMKeepAwakeFlag" 52 "NMEEMKeepAwakeFlag" 53 "NMEEMKeepAwakeFlag_Aux" 54 "NMVCUGlobalKeepAwakeFlag" 55 "NMVCUChargingKeepAwakeFlag（新能源，VCU_hcu）" 56 "DoIPActiveLineStatus" 57 "NMBMSGlobalKeepAwakeFlag" 58 "NMBMSChargingKeepAwakeFlag" 59 "NMBMSThermalRunawayKeepAwakeFlag（新能源，BMS）" 60 "Reserved" 61 "NMBMSThermalRunawayKeepAwakeFlag （动力，VCU_slccu）" 62 "NMVCUChargingKeepAwakeFlag（动力，VCU_slccu）" 63 "NMVCU2GlobalKeepAwakeFlag" 64 "NMVHMKeepAwakeFlag" 65 "Reserved" 66 "CSM_RC_KeepAwake" 67 "NMHVACKeepAwakeFlag（新能源，TMS）" 68 "Reserved" 69 "Reserved" 70 "BDC_NMBDCKeepAwakeFlag" 71 "NMTMSChargingKeepAwakeFlag" 72 "NMTMSGlobalKeepAwakeFlag" 73 "Reserved" 74 "Reserved" 75 "Reserved" 76 "Reserved" 77 "Reserved" 78 "Reserved" 79 "Reserved" 80 "Reserved" 81 "Reserved" 82 "Reserved" 83 "Reserved" 84 "Reserved" 85 "Reserved" 86 "Reserved" 87 "Reserved" 88 "Reserved" 89 "NMWCCDownloadRequest_RT1" 90 "CAN7_DiagMSG_ID ！" 91 "CAN7_DiagMSG_ID" 92 "Reserved" 93 "Reserved" 94 "Reserved" 95 "Reserved" 96 "Reserved" 97 "Reserved" 98 "Reserved" 99 "Reserved" 100 "NMATWSKeepAwakeFlag" 101 "NMExteriorLightKeepAwakeFlag" 102 "NMLockingKeepAwakeFlag" 103 "NMPWLKeepAwakeFlag" 104 "NMSunRoofKeepAwakeFlag" 105 "NMPLGKeepAwakeFlag" 106 "NMPowerOperatedDoorKeepAwakeFlag" 107 "MR_NMMirrorKeepAwakeFlag" 108 "NMSeatControlKeepAwakeFlag" 109 "NMHVACKeepAwakeFlag" 110 "NMHVACRLSLinAwakeFlag" 111 "NMAQCKeepAwakeFlag" 112 "NMTPMSKeepAwakeFlag" 113 "ILC_NMKeepAwakeFlag" 114 "NMESMKeepAwakeFlag" 115 "NMKAEKeepAwakeFlag" 116 "NMVRMPNCCharingKeepAwakeFlag" 140 "NMWCCDownloadReques_RT2" ;
VAL_ 1359 CCU_PNCInformation0 0 "No request" 1 "Request" 0 "No request" 1 "Request" 0 "No request" 1 "Request" 0 "No request" 1 "Request" 1 "Request" 0 "No request" 1 "Request" 0 "No request" 1 "Request" ;
VAL_ 1359 CCU_PNCInformation1 0 "No request" 1 "Request" 0 "No request" 1 "Request" ;
VAL_ 352 BCS_VehSpdVD 0 "Not Valid" 1 "Valid" ;
VAL_ 352 BCS_EBDActiveSt 0 "Not active" 1 "Active" ;
VAL_ 352 BCS_EBDFaultSt 0 "Not fault" 1 "Fault" ;
VAL_ 352 BCS_ABSActiveSt 0 "Not active" 1 "Active" ;
VAL_ 352 BCS_ABSFaultSt 0 "Not fault" 1 "Fault" ;
VAL_ 352 BCS_TCSActiveSt 0 "Not active" 1 "Active" ;
VAL_ 352 BCS_TCSFaultSt 0 "Not fault" 1 "Fault" ;
VAL_ 352 BCS_VDCActiveSt 0 "Not active" 1 "Active" ;
VAL_ 352 BCS_VDCFaultSt 0 "Not fault" 1 "Fault" ;
VAL_ 352 BCS_RegenModulationAvailable 0 "Not available" 1 "Available" ;
VAL_ 352 BCS_RegenModuleActive 0 "Not Active" 1 "Active" ;
VAL_ 352 BCS_DMCCtrModeFA 0 "ModeDMC_Off" 1 "ModeDMC_Rpm" 2 "ModeDMC_Trq" ;
VAL_ 352 BCS_DMCCtrModeRA 0 "ModeDMC_Off" 1 "ModeDMC_Rpm" 2 "ModeDMC_Trq" ;
VAL_ 352 BCS_EngTorqDecActiveStRA 0 "Not active" 1 "Active" ;
VAL_ 398 EMS_EngSpdVD 0 "Invalid" 1 "Valid" ;
VAL_ 398 EMS_OBDDrivingCycleStForPDTC 0 "Not achieved" 1 "Achieved" ;
VAL_ 398 EMS_OBDWarmUpCycleSt 0 "Not Achieved" 1 "Achieved" ;
VAL_ 398 EMS_EngWaterTempVD 0 "Invalid" 1 "Valid" ;
VAL_ 445 EMS_IUPRGenInh 0 "update inhibition condition is not met" 1 "update inhibition condition is met" ;
VAL_ 445 EMS_IURPGenDen 0 "update permission condition is not met" 1 "update permission condition is met" ;
VAL_ 445 EMS_IUPRIgCnt 0 "update permission condition is not met" 1 "update permission condition is met" ;
VAL_ 161 ACU_ACChgCurCfg 0 "No command；" 1 "4A；" 2 "8A；" 3 "12A；" 4 "16A；" 5 "20A；" 6 "24A；" 7 "28A；" 8 "32A；" 9 "reserved" 10 "reserved" 11 "reserved" 12 "reserved" 13 "reserved" 14 "reserved" 15 "reserved" 16 "reserved" 17 "reserved" 18 "reserved" 19 "reserved" 20 "reserved" 21 "reserved" 22 "reserved" 23 "reserved" 24 "reserved" 25 "reserved" 26 "reserved" 27 "reserved" 28 "reserved" 29 "reserved" 30 "reserved" 31 "reserved" ;
VAL_ 909 IPDS_RearMotorPowerSt 0 "Not Active" 1 "Active" ;
VAL_ 909 IPDS_RearEOPPowerSt 0 "Not Active" 1 "Active" ;
VAL_ 909 IPDS_RearMotorPowerFaultSt 0 "Normal" 1 "Circuit short to ground" 2 "Circuit short to battery" 3 "Open" 4 "Overpower" 5 "Reserve" 6 "Reserve" 7 "Reserve" ;
VAL_ 909 IPDS_RearEOPPowerFaultSt 0 "Normal" 1 "Circuit short to ground" 2 "Circuit short to battery" 3 "Open" 4 "Overpower" 5 "Reserve" 6 "Reserve" 7 "Reserve" ;
VAL_ 909 IPDS_KL15T1PowerSt 0 "Not Active" 1 "Active" ;
VAL_ 2683306012 IPS_spd_NmReq 2 "释放网络" 1 "维持网络" 0 "初始状态" ;
